VERSION ""

NS_ :

BS_:

BU_: Receiver ChassisBus VehicleBus PartyBus

BO_ 12 ID00CUI_status: 8 VehicleBus
 SG_ UI_audioActive : 1|1@1+ (1,0) [0|1] ""  Receiver
 SG_ UI_autopilotTrial : 12|2@1+ (1,0) [0|3] ""  Receiver
 SG_ UI_bluetoothActive : 2|1@1+ (1,0) [0|1] ""  Receiver
 SG_ UI_cameraActive : 41|1@1+ (1,0) [0|1] ""  Receiver
 SG_ UI_cellActive : 3|1@1+ (1,0) [0|1] ""  Receiver
 SG_ UI_cellConnected : 10|1@1+ (1,0) [0|1] ""  Receiver
 SG_ UI_cellNetworkTechnology : 19|4@1+ (1,0) [0|15] ""  Receiver
 SG_ UI_cellReceiverPower : 24|8@1+ (1,-128) [-128|127] "dB"  Receiver
 SG_ UI_cellSignalBars : 42|3@1+ (1,0) [0|7] ""  Receiver
 SG_ UI_cpuTemperature : 56|8@1- (1,40) [-20|100] "C"  Receiver
 SG_ UI_developmentCar : 40|1@1+ (1,0) [0|1] ""  Receiver
 SG_ UI_displayOn : 5|1@1+ (1,0) [0|1] ""  Receiver
 SG_ UI_displayReady : 4|1@1+ (1,0) [0|1] ""  Receiver
 SG_ UI_factoryReset : 14|2@1+ (1,0) [0|3] ""  Receiver
 SG_ UI_falseTouchCounter : 32|8@1+ (1,0) [0|255] "1"  Receiver
 SG_ UI_gpsActive : 16|1@1+ (1,0) [0|1] ""  Receiver
 SG_ UI_pcbTemperature : 48|8@1- (1,40) [-20|100] "C"  Receiver
 SG_ UI_radioActive : 18|1@1+ (1,0) [0|1] ""  Receiver
 SG_ UI_readyForDrive : 9|1@1+ (1,0) [0|1] ""  Receiver
 SG_ UI_screenshotActive : 17|1@1+ (1,0) [0|1] ""  Receiver
 SG_ UI_systemActive : 8|1@1+ (1,0) [0|1] ""  Receiver
 SG_ UI_touchActive : 0|1@1+ (1,0) [0|1] ""  Receiver
 SG_ UI_vpnActive : 11|1@1+ (1,0) [0|1] ""  Receiver
 SG_ UI_wifiActive : 6|1@1+ (1,0) [0|1] ""  Receiver
 SG_ UI_wifiConnected : 7|1@1+ (1,0) [0|1] ""  Receiver

BO_ 851 ID353UI_status: 8 VehicleBus
 SG_ UI_audioActive : 1|1@1+ (1,0) [0|1] ""  Receiver
 SG_ UI_autopilotTrial : 12|2@1+ (1,0) [0|3] ""  Receiver
 SG_ UI_bluetoothActive : 2|1@1+ (1,0) [0|1] ""  Receiver
 SG_ UI_cameraActive : 41|1@1+ (1,0) [0|1] ""  Receiver
 SG_ UI_cellActive : 3|1@1+ (1,0) [0|1] ""  Receiver
 SG_ UI_cellConnected : 10|1@1+ (1,0) [0|1] ""  Receiver
 SG_ UI_cellNetworkTechnology : 19|4@1+ (1,0) [0|15] ""  Receiver
 SG_ UI_cellReceiverPower : 24|8@1+ (1,-128) [-128|127] "dB"  Receiver
 SG_ UI_cellSignalBars : 42|3@1+ (1,0) [0|7] ""  Receiver
 SG_ UI_cpuTemperature : 56|8@1- (1,40) [-20|100] "C"  Receiver
 SG_ UI_developmentCar : 40|1@1+ (1,0) [0|1] ""  Receiver
 SG_ UI_displayOn : 5|1@1+ (1,0) [0|1] ""  Receiver
 SG_ UI_displayReady : 4|1@1+ (1,0) [0|1] ""  Receiver
 SG_ UI_factoryReset : 14|2@1+ (1,0) [0|3] ""  Receiver
 SG_ UI_falseTouchCounter : 32|8@1+ (1,0) [0|255] "1"  Receiver
 SG_ UI_gpsActive : 16|1@1+ (1,0) [0|1] ""  Receiver
 SG_ UI_pcbTemperature : 48|8@1- (1,40) [-20|100] "C"  Receiver
 SG_ UI_radioActive : 18|1@1+ (1,0) [0|1] ""  Receiver
 SG_ UI_readyForDrive : 9|1@1+ (1,0) [0|1] ""  Receiver
 SG_ UI_screenshotActive : 17|1@1+ (1,0) [0|1] ""  Receiver
 SG_ UI_systemActive : 8|1@1+ (1,0) [0|1] ""  Receiver
 SG_ UI_touchActive : 0|1@1+ (1,0) [0|1] ""  Receiver
 SG_ UI_vpnActive : 11|1@1+ (1,0) [0|1] ""  Receiver
 SG_ UI_wifiActive : 6|1@1+ (1,0) [0|1] ""  Receiver
 SG_ UI_wifiConnected : 7|1@1+ (1,0) [0|1] ""  Receiver

BO_ 22 ID016DI_bmsRequest: 1 VehicleBus
 SG_ DI_bmsOpenContactorsRequest : 4|1@1+ (1,0) [0|1] ""  Receiver
 SG_ DI_bmsRequestInterfaceVersion : 0|4@1+ (1,0) [0|15] ""  Receiver

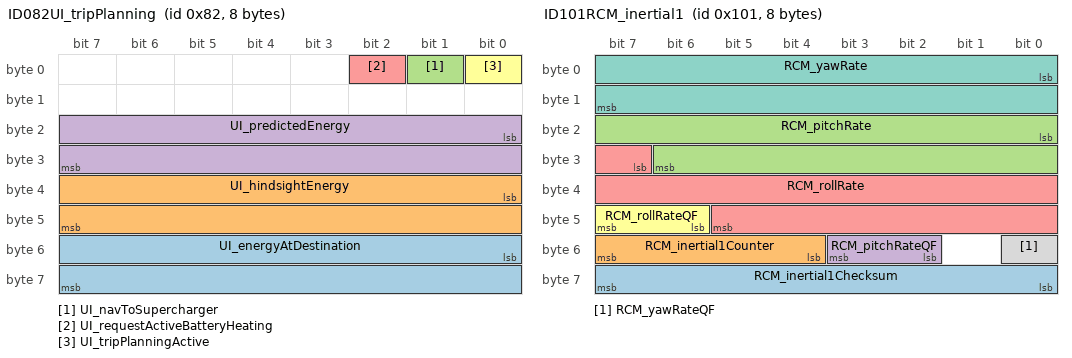
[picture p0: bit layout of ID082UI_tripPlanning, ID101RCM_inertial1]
BO_ 130 ID082UI_tripPlanning: 8 VehicleBus
 SG_ UI_energyAtDestination : 48|16@1- (0.01,0) [-327.67|327.67] "kWh"  Receiver
 SG_ UI_hindsightEnergy : 32|16@1- (0.01,0) [-327.67|327.67] "kWh"  Receiver
 SG_ UI_navToSupercharger : 1|1@1+ (1,0) [0|1] ""  Receiver
 SG_ UI_predictedEnergy : 16|16@1- (0.01,0) [-327.67|327.67] "kWh"  Receiver
 SG_ UI_requestActiveBatteryHeating : 2|1@1+ (1,0) [0|1] ""  Receiver
 SG_ UI_tripPlanningActive : 0|1@1+ (1,0) [0|1] ""  Receiver

BO_ 257 ID101RCM_inertial1: 8 ChassisBus
 SG_ RCM_inertial1Checksum : 56|8@1+ (1,0) [0|255] ""  Receiver
 SG_ RCM_inertial1Counter : 52|4@1+ (1,0) [0|15] ""  Receiver
 SG_ RCM_pitchRate : 16|15@1- (0.00025,0) [-4.096|4.09575] "rad/s"  Receiver
 SG_ RCM_pitchRateQF : 50|2@1+ (1,0) [0|3] ""  Receiver
 SG_ RCM_rollRate : 31|15@1- (0.00025,0) [-4.096|4.09575] "rad/s"  Receiver
 SG_ RCM_rollRateQF : 46|2@1+ (1,0) [0|3] ""  Receiver
 SG_ RCM_yawRate : 0|16@1- (0.0001,0) [-3.2766|3.2766] "rad/s"  Receiver
 SG_ RCM_yawRateQF : 48|1@1+ (1,0) [0|1] ""  Receiver

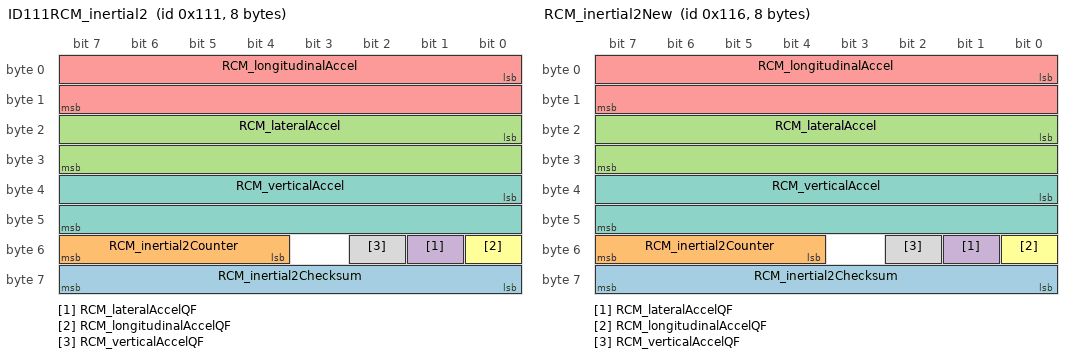
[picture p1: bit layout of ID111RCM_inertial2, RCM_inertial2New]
BO_ 273 ID111RCM_inertial2: 8 ChassisBus
 SG_ RCM_inertial2Checksum : 56|8@1+ (1,0) [0|255] ""  Receiver
 SG_ RCM_inertial2Counter : 52|4@1+ (1,0) [0|15] ""  Receiver
 SG_ RCM_lateralAccel : 16|16@1- (0.00125,0) [-40.9575|40.9575] "m/s^2"  Receiver
 SG_ RCM_lateralAccelQF : 49|1@1+ (1,0) [0|1] ""  Receiver
 SG_ RCM_longitudinalAccel : 0|16@1- (0.00125,0) [-40.9575|40.9575] "m/s^2"  Receiver
 SG_ RCM_longitudinalAccelQF : 48|1@1+ (1,0) [0|1] ""  Receiver
 SG_ RCM_verticalAccel : 32|16@1- (0.00125,0) [-40.9575|40.9575] "m/s^2"  Receiver
 SG_ RCM_verticalAccelQF : 50|1@1+ (1,0) [0|1] ""  Receiver

BO_ 278 RCM_inertial2New: 8 ChassisBus
 SG_ RCM_inertial2Checksum : 56|8@1+ (1,0) [0|255] ""  Receiver
 SG_ RCM_inertial2Counter : 52|4@1+ (1,0) [0|15] ""  Receiver
 SG_ RCM_lateralAccel : 16|16@1- (0.00125,0) [-40.9575|40.9575] "m/s^2"  Receiver
 SG_ RCM_lateralAccelQF : 49|1@1+ (1,0) [0|1] ""  Receiver
 SG_ RCM_longitudinalAccel : 0|16@1- (0.00125,0) [-40.9575|40.9575] "m/s^2"  Receiver
 SG_ RCM_longitudinalAccelQF : 48|1@1+ (1,0) [0|1] ""  Receiver
 SG_ RCM_verticalAccel : 32|16@1- (0.00125,0) [-40.9575|40.9575] "m/s^2"  Receiver
 SG_ RCM_verticalAccelQF : 50|1@1+ (1,0) [0|1] ""  Receiver

BO_ 258 ID102VCLEFT_doorStatus: 8 VehicleBus
 SG_ VCLEFT_frontHandlePWM : 16|7@1+ (1,0) [0|100] "%"  Receiver
 SG_ VCLEFT_frontHandlePulled : 10|1@1+ (1,0) [0|1] ""  Receiver
 SG_ VCLEFT_frontHandlePulledPersist : 62|1@1+ (1,0) [0|1] ""  Receiver
 SG_ VCLEFT_frontIntSwitchPressed : 31|1@1+ (1,0) [0|1] ""  Receiver
 SG_ VCLEFT_frontLatchStatus : 0|4@1+ (1,0) [0|8] ""  Receiver
 SG_ VCLEFT_frontLatchSwitch : 8|1@1+ (1,0) [0|1] ""  Receiver
 SG_ VCLEFT_frontRelActuatorSwitch : 12|1@1+ (1,0) [0|1] ""  Receiver
 SG_ VCLEFT_mirrorDipped : 61|1@1+ (1,0) [0|1] ""  Receiver
 SG_ VCLEFT_mirrorFoldState : 52|3@1+ (1,0) [0|4] ""  Receiver
 SG_ VCLEFT_mirrorHeatState : 58|3@1+ (1,0) [0|4] ""  Receiver
 SG_ VCLEFT_mirrorRecallState : 55|3@1+ (1,0) [0|5] ""  Receiver
 SG_ VCLEFT_mirrorState : 49|3@1+ (1,0) [0|4] ""  Receiver
 SG_ VCLEFT_mirrorTiltXPosition : 33|8@1+ (0.02,0) [0|5] "V"  Receiver
 SG_ VCLEFT_mirrorTiltYPosition : 41|8@1+ (0.02,0) [0|5] "V"  Receiver
 SG_ VCLEFT_rearHandlePWM : 24|7@1+ (1,0) [0|100] "%"  Receiver
 SG_ VCLEFT_rearHandlePulled : 11|1@1+ (1,0) [0|1] ""  Receiver
 SG_ VCLEFT_rearIntSwitchPressed : 32|1@1+ (1,0) [0|1] ""  Receiver
 SG_ VCLEFT_rearLatchStatus : 4|4@1+ (1,0) [0|8] ""  Receiver
 SG_ VCLEFT_rearLatchSwitch : 9|1@1+ (1,0) [0|1] ""  Receiver
 SG_ VCLEFT_rearRelActuatorSwitch : 13|1@1+ (1,0) [0|1] ""  Receiver

BO_ 259 ID103VCRIGHT_doorStatus: 8 VehicleBus
 SG_ VCRIGHT_frontHandlePWM : 14|7@1+ (1,0) [0|100] "%"  Receiver
 SG_ VCRIGHT_frontHandlePulled : 10|1@1+ (1,0) [0|1] ""  Receiver
 SG_ VCRIGHT_frontHandlePulledPersist : 30|1@1+ (1,0) [0|1] ""  Receiver
 SG_ VCRIGHT_frontIntSwitchPressed : 31|1@1+ (1,0) [0|1] ""  Receiver
 SG_ VCRIGHT_frontLatchStatus : 0|4@1+ (1,0) [0|8] ""  Receiver
 SG_ VCRIGHT_frontLatchSwitch : 8|1@1+ (1,0) [0|1] ""  Receiver
 SG_ VCRIGHT_frontRelActuatorSwitch : 12|1@1+ (1,0) [0|1] ""  Receiver
 SG_ VCRIGHT_mirrorDipped : 63|1@1+ (1,0) [0|1] ""  Receiver
 SG_ VCRIGHT_mirrorFoldState : 52|3@1+ (1,0) [0|4] ""  Receiver
 SG_ VCRIGHT_mirrorRecallState : 60|3@1+ (1,0) [0|5] ""  Receiver
 SG_ VCRIGHT_mirrorState : 49|3@1+ (1,0) [0|4] ""  Receiver
 SG_ VCRIGHT_mirrorTiltXPosition : 33|8@1+ (0.02,0) [0|5] "V"  Receiver
 SG_ VCRIGHT_mirrorTiltYPosition : 41|8@1+ (0.02,0) [0|5] "V"  Receiver
 SG_ VCRIGHT_rearHandlePWM : 21|7@1+ (1,0) [0|100] "%"  Receiver
 SG_ VCRIGHT_rearHandlePulled : 11|1@1+ (1,0) [0|1] ""  Receiver
 SG_ VCRIGHT_rearIntSwitchPressed : 32|1@1+ (1,0) [0|1] ""  Receiver
 SG_ VCRIGHT_rearLatchStatus : 4|4@1+ (1,0) [0|8] ""  Receiver
 SG_ VCRIGHT_rearLatchSwitch : 9|1@1+ (1,0) [0|1] ""  Receiver
 SG_ VCRIGHT_rearRelActuatorSwitch : 13|1@1+ (1,0) [0|1] ""  Receiver
 SG_ VCRIGHT_reservedForBackCompat : 28|2@1+ (1,0) [0|3] ""  Receiver
 SG_ VCRIGHT_trunkLatchStatus : 56|4@1+ (1,0) [0|8] ""  Receiver

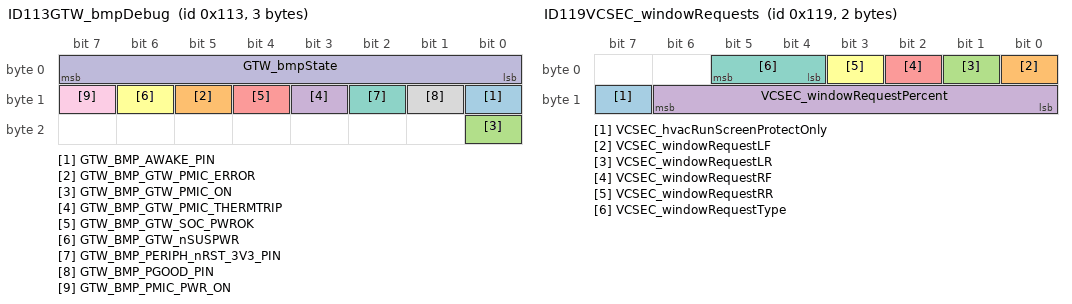
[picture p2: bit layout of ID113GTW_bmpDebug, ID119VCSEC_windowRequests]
BO_ 275 ID113GTW_bmpDebug: 3 VehicleBus
 SG_ GTW_BMP_AWAKE_PIN : 8|1@1+ (1,0) [0|1] ""  Receiver
 SG_ GTW_BMP_GTW_PMIC_ERROR : 13|1@1+ (1,0) [0|1] ""  Receiver
 SG_ GTW_BMP_GTW_PMIC_ON : 16|1@1+ (1,0) [0|1] ""  Receiver
 SG_ GTW_BMP_GTW_PMIC_THERMTRIP : 11|1@1+ (1,0) [0|1] ""  Receiver
 SG_ GTW_BMP_GTW_SOC_PWROK : 12|1@1+ (1,0) [0|1] ""  Receiver
 SG_ GTW_BMP_GTW_nSUSPWR : 14|1@1+ (1,0) [0|1] ""  Receiver
 SG_ GTW_BMP_PERIPH_nRST_3V3_PIN : 10|1@1+ (1,0) [0|1] ""  Receiver
 SG_ GTW_BMP_PGOOD_PIN : 9|1@1+ (1,0) [0|1] ""  Receiver
 SG_ GTW_BMP_PMIC_PWR_ON : 15|1@1+ (1,0) [0|1] ""  Receiver
 SG_ GTW_bmpState : 7|8@0+ (1,0) [0|255] ""  Receiver

BO_ 281 ID119VCSEC_windowRequests: 2 VehicleBus
 SG_ VCSEC_hvacRunScreenProtectOnly : 15|1@1+ (1,0) [0|1] ""  Receiver
 SG_ VCSEC_windowRequestLF : 0|1@1+ (1,0) [0|1] ""  Receiver
 SG_ VCSEC_windowRequestLR : 1|1@1+ (1,0) [0|1] ""  Receiver
 SG_ VCSEC_windowRequestPercent : 8|7@1+ (1,0) [0|127] ""  Receiver
 SG_ VCSEC_windowRequestRF : 2|1@1+ (1,0) [0|1] ""  Receiver
 SG_ VCSEC_windowRequestRR : 3|1@1+ (1,0) [0|1] ""  Receiver
 SG_ VCSEC_windowRequestType : 4|2@1+ (1,0) [0|3] ""  Receiver

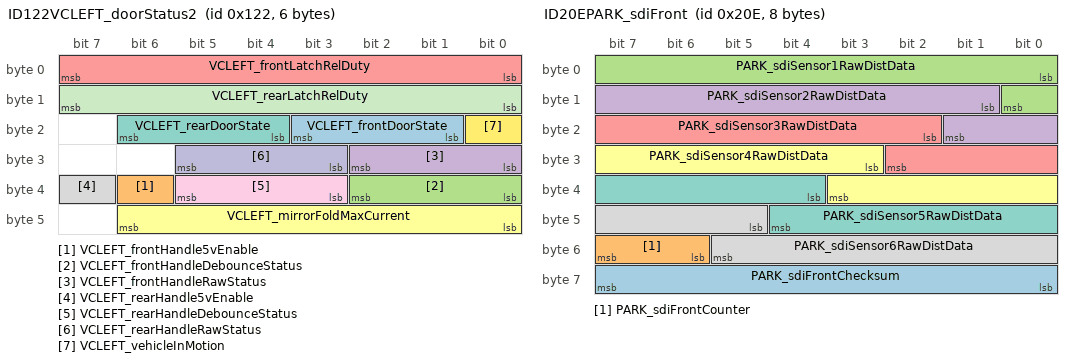
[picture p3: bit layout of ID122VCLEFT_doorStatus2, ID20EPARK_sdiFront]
BO_ 290 ID122VCLEFT_doorStatus2: 6 VehicleBus
 SG_ VCLEFT_frontDoorState : 17|3@1+ (1,0) [0|4] ""  Receiver
 SG_ VCLEFT_frontHandle5vEnable : 38|1@1+ (1,0) [0|1] ""  Receiver
 SG_ VCLEFT_frontHandleDebounceStatus : 32|3@1+ (1,0) [0|5] ""  Receiver
 SG_ VCLEFT_frontHandleRawStatus : 24|3@1+ (1,0) [0|5] ""  Receiver
 SG_ VCLEFT_frontLatchRelDuty : 0|8@1+ (1,0) [0|255] "%"  Receiver
 SG_ VCLEFT_mirrorFoldMaxCurrent : 40|7@1- (0.046,0) [-2.944|2.898] "A"  Receiver
 SG_ VCLEFT_rearDoorState : 20|3@1+ (1,0) [0|4] ""  Receiver
 SG_ VCLEFT_rearHandle5vEnable : 39|1@1+ (1,0) [0|1] ""  Receiver
 SG_ VCLEFT_rearHandleDebounceStatus : 35|3@1+ (1,0) [0|5] ""  Receiver
 SG_ VCLEFT_rearHandleRawStatus : 27|3@1+ (1,0) [0|5] ""  Receiver
 SG_ VCLEFT_rearLatchRelDuty : 8|8@1+ (1,0) [0|255] "%"  Receiver
 SG_ VCLEFT_vehicleInMotion : 16|1@1+ (1,0) [0|1] ""  Receiver

BO_ 291 ID123UI_alertMatrix1: 8 VehicleBus
 SG_ UI_a001_DriverDoorOpen : 0|1@1+ (1,0) [0|1] ""  Receiver
 SG_ UI_a002_DoorOpen : 1|1@1+ (1,0) [0|1] ""  Receiver
 SG_ UI_a003_TrunkOpen : 2|1@1+ (1,0) [0|1] ""  Receiver
 SG_ UI_a004_FrunkOpen : 3|1@1+ (1,0) [0|1] ""  Receiver
 SG_ UI_a005_HeadlightsOnDoorOpen : 4|1@1+ (1,0) [0|1] ""  Receiver
 SG_ UI_a006_RemoteServiceAlert : 5|1@1+ (1,0) [0|1] ""  Receiver
 SG_ UI_a007_SoftPackConfigMismatch : 6|1@1+ (1,0) [0|1] ""  Receiver
 SG_ UI_a008_TouchScreenError : 7|1@1+ (1,0) [0|1] ""  Receiver
 SG_ UI_a009_SquashfsError : 8|1@1+ (1,0) [0|1] ""  Receiver
 SG_ UI_a010_MapsMissing : 9|1@1+ (1,0) [0|1] ""  Receiver
 SG_ UI_a011_IncorrectMap : 10|1@1+ (1,0) [0|1] ""  Receiver
 SG_ UI_a012_NotOnPrivateProperty : 11|1@1+ (1,0) [0|1] ""  Receiver
 SG_ UI_a013_TPMSHardWarning : 12|1@1+ (1,0) [0|1] ""  Receiver
 SG_ UI_a014_TPMSSoftWarning : 13|1@1+ (1,0) [0|1] ""  Receiver
 SG_ UI_a015_TPMSOverPressureWarning : 14|1@1+ (1,0) [0|1] ""  Receiver
 SG_ UI_a016_TPMSTemperatureWarning : 15|1@1+ (1,0) [0|1] ""  Receiver
 SG_ UI_a017_TPMSSystemFault : 16|1@1+ (1,0) [0|1] ""  Receiver
 SG_ UI_a018_SlipStartOn : 17|1@1+ (1,0) [0|1] ""  Receiver
 SG_ UI_a019_ParkBrakeFault : 18|1@1+ (1,0) [0|1] ""  Receiver
 SG_ UI_a020_SteeringReduced : 19|1@1+ (1,0) [0|1] ""  Receiver
 SG_ UI_a021_RearSeatbeltUnbuckled : 20|1@1+ (1,0) [0|1] ""  Receiver
 SG_ UI_a022_ApeFusesEtc : 21|1@1+ (1,0) [0|1] ""  Receiver
 SG_ UI_a023_CellInternetCheckFailed : 22|1@1+ (1,0) [0|1] ""  Receiver
 SG_ UI_a024_WifiInternetCheckFailed : 23|1@1+ (1,0) [0|1] ""  Receiver
 SG_ UI_a025_WifiOnlineCheckFailed : 24|1@1+ (1,0) [0|1] ""  Receiver
 SG_ UI_a026_ModemResetLoopDetected : 25|1@1+ (1,0) [0|1] ""  Receiver
 SG_ UI_a027_AutoSteerMIA : 26|1@1+ (1,0) [0|1] ""  Receiver
 SG_ UI_a028_FrontTrunkPopupClosed : 27|1@1+ (1,0) [0|1] ""  Receiver
 SG_ UI_a029_ModemMIA : 28|1@1+ (1,0) [0|1] ""  Receiver
 SG_ UI_a030_ModemVMCrash : 29|1@1+ (1,0) [0|1] ""  Receiver
 SG_ UI_a031_BrakeFluidLow : 30|1@1+ (1,0) [0|1] ""  Receiver
 SG_ UI_a032_CellModemRecoveryResets : 31|1@1+ (1,0) [0|1] ""  Receiver
 SG_ UI_a033_ApTrialExpired : 32|1@1+ (1,0) [0|1] ""  Receiver
 SG_ UI_a034_WakeupProblem : 33|1@1+ (1,0) [0|1] ""  Receiver
 SG_ UI_a035_AudioWatchdogKernelError : 34|1@1+ (1,0) [0|1] ""  Receiver
 SG_ UI_a036_AudioWatchdogHfpError : 35|1@1+ (1,0) [0|1] ""  Receiver
 SG_ UI_a037_AudioWatchdogXrunStormEr : 36|1@1+ (1,0) [0|1] ""  Receiver
 SG_ UI_a038_AudioWatchdogA2bI2cLocku : 37|1@1+ (1,0) [0|1] ""  Receiver
 SG_ UI_a039_AudioA2bNeedRediscovery : 38|1@1+ (1,0) [0|1] ""  Receiver
 SG_ UI_a040_HomelinkTransmit : 39|1@1+ (1,0) [0|1] ""  Receiver
 SG_ UI_a041_AudioDmesgXrun : 40|1@1+ (1,0) [0|1] ""  Receiver
 SG_ UI_a042_AudioDmesgRtThrottling : 41|1@1+ (1,0) [0|1] ""  Receiver
 SG_ UI_a043_InvalidMapDataOverride : 42|1@1+ (1,0) [0|1] ""  Receiver
 SG_ UI_a044_AudioDmesgDspException : 43|1@1+ (1,0) [0|1] ""  Receiver
 SG_ UI_a045_ECallNeedsService : 44|1@1+ (1,0) [0|1] ""  Receiver
 SG_ UI_a046_BackupCameraStreamError : 45|1@1+ (1,0) [0|1] ""  Receiver
 SG_ UI_a047_CellRoamingDisallowed : 46|1@1+ (1,0) [0|1] ""  Receiver
 SG_ UI_a048_AudioPremiumAmpCheckFail : 47|1@1+ (1,0) [0|1] ""  Receiver
 SG_ UI_a049_BrakeShiftRequired : 48|1@1+ (1,0) [0|1] ""  Receiver
 SG_ UI_a050_BackupCameraIPUTimeout : 49|1@1+ (1,0) [0|1] ""  Receiver
 SG_ UI_a051_BackupCameraFrameTimeout : 50|1@1+ (1,0) [0|1] ""  Receiver
 SG_ UI_a052_KernelPanicReported : 51|1@1+ (1,0) [0|1] ""  Receiver
 SG_ UI_a053_QtCarExitError : 52|1@1+ (1,0) [0|1] ""  Receiver
 SG_ UI_a054_AudioBoostPowerBad : 53|1@1+ (1,0) [0|1] ""  Receiver
 SG_ UI_a055_ManualECallDisabled : 54|1@1+ (1,0) [0|1] ""  Receiver
 SG_ UI_a056_ManualECallButtonDisconn : 55|1@1+ (1,0) [0|1] ""  Receiver
 SG_ UI_a057_CellAntennaDisconnected : 56|1@1+ (1,0) [0|1] ""  Receiver
 SG_ UI_a058_GPSAntennaDisconnected : 57|1@1+ (1,0) [0|1] ""  Receiver
 SG_ UI_a059_ECallSpeakerDisconnected : 58|1@1+ (1,0) [0|1] ""  Receiver
 SG_ UI_a060_ECallMicDisconnected : 59|1@1+ (1,0) [0|1] ""  Receiver
 SG_ UI_a061_SIMTestFailed : 60|1@1+ (1,0) [0|1] ""  Receiver
 SG_ UI_a062_ENSTestFailed : 61|1@1+ (1,0) [0|1] ""  Receiver
 SG_ UI_a063_CellularTestFailed : 62|1@1+ (1,0) [0|1] ""  Receiver
 SG_ UI_a064_ModemFirmwareTestFailed : 63|1@1+ (1,0) [0|1] ""  Receiver

BO_ 322 ID142VCLEFT_liftgateStatus: 8 VehicleBus
 SG_ VCLEFT_liftgateStatusIndex M : 0|2@1+ (1,0) [0|2] ""  Receiver
 SG_ VCLEFT_liftgateLatchRequest m0 : 61|3@1+ (1,0) [0|4] ""  Receiver
 SG_ VCLEFT_liftgateMvmntNotAllowedCo m0 : 14|3@1+ (1,0) [0|5] ""  Receiver
 SG_ VCLEFT_liftgatePhysicalChimeRequ m0 : 21|3@1+ (1,0) [0|4] ""  Receiver
 SG_ VCLEFT_liftgatePosition m1 : 21|7@1- (1,46) [-5|95] "deg"  Receiver
 SG_ VCLEFT_liftgatePositionCalibrate m0 : 17|1@1+ (1,0) [0|1] ""  Receiver
 SG_ VCLEFT_liftgateRequestSource m0 : 7|3@1+ (1,0) [0|7] ""  Receiver
 SG_ VCLEFT_liftgateSpeed m1 : 28|10@1- (0.1,0) [-30|30] "deg/s"  Receiver
 SG_ VCLEFT_liftgateState m0 : 3|4@1+ (1,0) [0|12] ""  Receiver
 SG_ VCLEFT_liftgateStoppingCondition m0 : 10|4@1+ (1,0) [0|11] ""  Receiver
 SG_ VCLEFT_liftgateStrutCurrent m1 : 11|10@1- (0.1,0) [-30|30] "A"  Receiver
 SG_ VCLEFT_liftgateStrutDutyCycle m1 : 3|8@1- (1,0) [-100|100] "%"  Receiver
 SG_ VCLEFT_liftgateUIChimeRequest m0 : 18|3@1+ (1,0) [0|4] ""  Receiver

BO_ 325 ID145ESP_status: 8 ChassisBus
 SG_ ESP_absBrakeEvent2 : 22|2@1+ (1,0) [0|3] ""  Receiver
 SG_ ESP_absFaultLamp : 17|1@1+ (1,0) [0|1] ""  Receiver
 SG_ ESP_brakeApply : 31|1@1+ (1,0) [0|1] ""  Receiver
 SG_ ESP_brakeDiscWipingActive : 28|1@1+ (1,0) [0|1] ""  Receiver
 SG_ ESP_brakeLamp : 21|1@1+ (1,0) [0|1] ""  Receiver
 SG_ ESP_brakeTorqueTarget : 51|13@1+ (2,0) [0|16382] "Nm"  Receiver
 SG_ ESP_btcTargetState : 38|2@1+ (1,0) [0|3] ""  Receiver
 SG_ ESP_cdpStatus : 34|2@1+ (1,0) [0|3] ""  Receiver
 SG_ ESP_driverBrakeApply : 29|2@1+ (1,0) [0|3] ""  Receiver
 SG_ ESP_ebdFaultLamp : 16|1@1+ (1,0) [0|1] ""  Receiver
 SG_ ESP_ebrStandstillSkid : 48|1@1+ (1,0) [0|1] ""  Receiver
 SG_ ESP_ebrStatus : 49|2@1+ (1,0) [0|3] ""  Receiver
 SG_ ESP_espFaultLamp : 18|1@1+ (1,0) [0|1] ""  Receiver
 SG_ ESP_espLampFlash : 20|1@1+ (1,0) [0|1] ""  Receiver
 SG_ ESP_espModeActive : 12|2@1+ (1,0) [0|3] ""  Receiver
 SG_ ESP_hydraulicBoostEnabled : 19|1@1+ (1,0) [0|1] ""  Receiver
 SG_ ESP_lateralAccelQF : 25|1@1+ (1,0) [0|1] ""  Receiver
 SG_ ESP_longitudinalAccelQF : 24|1@1+ (1,0) [0|1] ""  Receiver
 SG_ ESP_ptcTargetState : 36|2@1+ (1,0) [0|3] ""  Receiver
 SG_ ESP_stabilityControlSts2 : 14|2@1+ (1,0) [0|3] ""  Receiver
 SG_ ESP_statusChecksum : 0|8@1+ (1,0) [0|255] ""  Receiver
 SG_ ESP_statusCounter : 8|4@1+ (1,0) [0|15] ""  Receiver
 SG_ ESP_steeringAngleQF : 27|1@1+ (1,0) [0|1] ""  Receiver
 SG_ ESP_yawRateQF : 26|1@1+ (1,0) [0|1] ""  Receiver

BO_ 470 ID1D6DI_limits: 5 VehicleBus
 SG_ DI_limitBaseSpeed : 15|1@1+ (1,0) [0|1] ""  Receiver
 SG_ DI_limitClutch : 28|1@1+ (1,0) [0|1] ""  Receiver
 SG_ DI_limitDcCapTemp : 17|1@1+ (1,0) [0|1] ""  Receiver
 SG_ DI_limitDeltaFluidTemp : 5|1@1+ (1,0) [0|1] ""  Receiver
 SG_ DI_limitDiff : 22|1@1+ (1,0) [0|1] ""  Receiver
 SG_ DI_limitDischargePower : 6|1@1+ (1,0) [0|1] ""  Receiver
 SG_ DI_limitDriveTorque : 10|1@1+ (1,0) [0|1] ""  Receiver
 SG_ DI_limitGracefulPowerOff : 23|1@1+ (1,0) [0|1] ""  Receiver
 SG_ DI_limitIBat : 16|1@1+ (1,0) [0|1] ""  Receiver
 SG_ DI_limitIGBTJunctTemp : 24|1@1+ (1,0) [0|1] ""  Receiver
 SG_ DI_limitInverterTemp : 1|1@1+ (1,0) [0|1] ""  Receiver
 SG_ DI_limitLimpMode : 4|1@1+ (1,0) [0|1] ""  Receiver
 SG_ DI_limitMotorCurrent : 8|1@1+ (1,0) [0|1] ""  Receiver
 SG_ DI_limitMotorSpeed : 20|1@1+ (1,0) [0|1] ""  Receiver
 SG_ DI_limitMotorVoltage : 9|1@1+ (1,0) [0|1] ""  Receiver
 SG_ DI_limitObstacleDetection : 29|1@1+ (1,0) [0|1] ""  Receiver
 SG_ DI_limitOilPumpFluidTemp : 26|1@1+ (1,0) [0|1] ""  Receiver
 SG_ DI_limitPCBTemp : 0|1@1+ (1,0) [0|1] ""  Receiver
 SG_ DI_limitPoleTemp : 3|1@1+ (1,0) [0|1] ""  Receiver
 SG_ DI_limitRegenPower : 7|1@1+ (1,0) [0|1] ""  Receiver
 SG_ DI_limitRegenTorque : 11|1@1+ (1,0) [0|1] ""  Receiver
 SG_ DI_limitRotorTemp : 36|1@1+ (1,0) [0|1] ""  Receiver
 SG_ DI_limitShift : 14|1@1+ (1,0) [0|1] ""  Receiver
 SG_ DI_limitShockTorque : 25|1@1+ (1,0) [0|1] ""  Receiver
 SG_ DI_limitStatorFrequency : 27|1@1+ (1,0) [0|1] ""  Receiver
 SG_ DI_limitStatorTemp : 2|1@1+ (1,0) [0|1] ""  Receiver
 SG_ DI_limitTCDrive : 12|1@1+ (1,0) [0|1] ""  Receiver
 SG_ DI_limitTCRegen : 13|1@1+ (1,0) [0|1] ""  Receiver
 SG_ DI_limitVBatHigh : 19|1@1+ (1,0) [0|1] ""  Receiver
 SG_ DI_limitVBatLow : 18|1@1+ (1,0) [0|1] ""  Receiver
 SG_ DI_limitVehicleSpeed : 21|1@1+ (1,0) [0|1] ""  Receiver
 SG_ DI_limitdcLinkCapTemp : 33|1@1+ (1,0) [0|1] ""  Receiver
 SG_ DI_limithvDcCableTemp : 37|1@1+ (1,0) [0|1] ""  Receiver
 SG_ DI_limitnegDcBusbarTemp : 34|1@1+ (1,0) [0|1] ""  Receiver
 SG_ DI_limitphaseOutBusBarWeldTemp : 31|1@1+ (1,0) [0|1] ""  Receiver
 SG_ DI_limitphaseOutBusbarTemp : 30|1@1+ (1,0) [0|1] ""  Receiver
 SG_ DI_limitphaseOutLugTemp : 32|1@1+ (1,0) [0|1] ""  Receiver
 SG_ DI_limitposDcBusbarTemp : 35|1@1+ (1,0) [0|1] ""  Receiver

BO_ 522 ID20AHVP_contactorState: 6 VehicleBus
 SG_ HVP_dcLinkAllowedToEnergize : 36|1@1+ (1,0) [0|1] ""  Receiver
 SG_ HVP_fcContNegativeAuxOpen : 7|1@1+ (1,0) [0|1] ""  Receiver
 SG_ HVP_fcContNegativeState : 12|3@1+ (1,0) [0|7] ""  Receiver
 SG_ HVP_fcContPositiveAuxOpen : 6|1@1+ (1,0) [0|1] ""  Receiver
 SG_ HVP_fcContPositiveState : 16|3@1+ (1,0) [0|7] ""  Receiver
 SG_ HVP_fcContactorSetState : 19|4@1+ (1,0) [0|9] ""  Receiver
 SG_ HVP_fcCtrsClosingAllowed : 29|1@1+ (1,0) [0|1] ""  Receiver
 SG_ HVP_fcCtrsOpenNowRequested : 27|1@1+ (1,0) [0|1] ""  Receiver
 SG_ HVP_fcCtrsOpenRequested : 28|1@1+ (1,0) [0|1] ""  Receiver
 SG_ HVP_fcCtrsRequestStatus : 24|2@1+ (1,0) [0|2] ""  Receiver
 SG_ HVP_fcCtrsResetRequestRequired : 26|1@1+ (1,0) [0|1] ""  Receiver
 SG_ HVP_fcLinkAllowedToEnergize : 44|2@1+ (1,0) [0|2] ""  Receiver
 SG_ HVP_hvilStatus : 40|4@1+ (1,0) [0|9] ""  Receiver
 SG_ HVP_packContNegativeState : 0|3@1+ (1,0) [0|7] ""  Receiver
 SG_ HVP_packContPositiveState : 3|3@1+ (1,0) [0|7] ""  Receiver
 SG_ HVP_packContactorSetState : 8|4@1+ (1,0) [0|9] ""  Receiver
 SG_ HVP_packCtrsClosingAllowed : 35|1@1+ (1,0) [0|1] ""  Receiver
 SG_ HVP_packCtrsOpenNowRequested : 33|1@1+ (1,0) [0|1] ""  Receiver
 SG_ HVP_packCtrsOpenRequested : 34|1@1+ (1,0) [0|1] ""  Receiver
 SG_ HVP_packCtrsRequestStatus : 30|2@1+ (1,0) [0|2] ""  Receiver
 SG_ HVP_packCtrsResetRequestRequired : 32|1@1+ (1,0) [0|1] ""  Receiver
 SG_ HVP_pyroTestInProgress : 37|1@1+ (1,0) [0|1] ""  Receiver

BO_ 526 ID20EPARK_sdiFront: 8 ChassisBus
 SG_ PARK_sdiFrontChecksum : 56|8@1+ (1,0) [0|255] ""  Receiver
 SG_ PARK_sdiFrontCounter : 54|2@1+ (1,0) [0|3] ""  Receiver
 SG_ PARK_sdiSensor1RawDistData : 0|9@1+ (1,0) [0|511] "cm"  Receiver
 SG_ PARK_sdiSensor2RawDistData : 9|9@1+ (1,0) [0|511] "cm"  Receiver
 SG_ PARK_sdiSensor3RawDistData : 18|9@1+ (1,0) [0|511] "cm"  Receiver
 SG_ PARK_sdiSensor4RawDistData : 27|9@1+ (1,0) [0|511] "cm"  Receiver
 SG_ PARK_sdiSensor5RawDistData : 36|9@1+ (1,0) [0|511] "cm"  Receiver
 SG_ PARK_sdiSensor6RawDistData : 45|9@1+ (1,0) [0|511] "cm"  Receiver

BO_ 537 ID219VCSEC_TPMSData: 5 ChassisBus
 SG_ VCSEC_TPMSDataIndex M : 0|2@1+ (1,0) [0|3] ""  Receiver
 SG_ VCSEC_TPMSBatVoltage0 m0 : 24|8@1+ (0.01,1.5) [1.5|4.04] "V"  Receiver
 SG_ VCSEC_TPMSBatVoltage1 m1 : 24|8@1+ (0.01,1.5) [1.5|4.04] "V"  Receiver
 SG_ VCSEC_TPMSBatVoltage2 m2 : 24|8@1+ (0.01,1.5) [1.5|4.04] "V"  Receiver
 SG_ VCSEC_TPMSBatVoltage3 m3 : 24|8@1+ (0.01,1.5) [1.5|4.04] "V"  Receiver
 SG_ VCSEC_TPMSLocation0 m0 : 32|3@1+ (1,0) [0|4] ""  Receiver
 SG_ VCSEC_TPMSLocation1 m1 : 32|3@1+ (1,0) [0|4] ""  Receiver
 SG_ VCSEC_TPMSLocation2 m2 : 32|3@1+ (1,0) [0|4] ""  Receiver
 SG_ VCSEC_TPMSLocation3 m3 : 32|3@1+ (1,0) [0|4] ""  Receiver
 SG_ VCSEC_TPMSPressure0 m0 : 8|8@1+ (0.025,0) [0|6.35] "bar"  Receiver
 SG_ VCSEC_TPMSPressure1 m1 : 8|8@1+ (0.025,0) [0|6.35] "bar"  Receiver
 SG_ VCSEC_TPMSPressure2 m2 : 8|8@1+ (0.025,0) [0|6.35] "bar"  Receiver
 SG_ VCSEC_TPMSPressure3 m3 : 8|8@1+ (0.025,0) [0|6.35] "bar"  Receiver
 SG_ VCSEC_TPMSTemperature0 m0 : 16|8@1+ (1,-40) [-40|214] "C"  Receiver
 SG_ VCSEC_TPMSTemperature1 m1 : 16|8@1+ (1,-40) [-40|214] "C"  Receiver
 SG_ VCSEC_TPMSTemperature2 m2 : 16|8@1+ (1,-40) [-40|214] "C"  Receiver
 SG_ VCSEC_TPMSTemperature3 m3 : 16|8@1+ (1,-40) [-40|214] "C"  Receiver

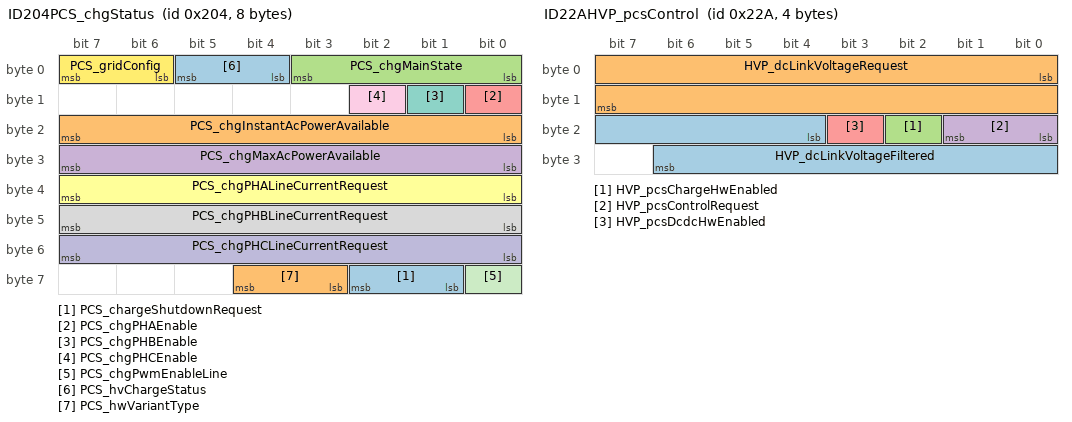
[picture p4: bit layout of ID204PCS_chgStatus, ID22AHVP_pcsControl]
BO_ 516 ID204PCS_chgStatus: 8 VehicleBus
 SG_ PCS_chargeShutdownRequest : 57|2@1+ (1,0) [0|2] ""  Receiver
 SG_ PCS_chgInstantAcPowerAvailable : 16|8@1+ (0.1,0) [0|20] "kW"  Receiver
 SG_ PCS_chgMainState : 0|4@1+ (1,0) [0|9] ""  Receiver
 SG_ PCS_chgMaxAcPowerAvailable : 24|8@1+ (0.1,0) [0|20] "kW"  Receiver
 SG_ PCS_chgPHAEnable : 8|1@1+ (1,0) [0|1] ""  Receiver
 SG_ PCS_chgPHALineCurrentRequest : 32|8@1+ (0.1,0) [0|20] "A"  Receiver
 SG_ PCS_chgPHBEnable : 9|1@1+ (1,0) [0|1] ""  Receiver
 SG_ PCS_chgPHBLineCurrentRequest : 40|8@1+ (0.1,0) [0|20] "A"  Receiver
 SG_ PCS_chgPHCEnable : 10|1@1+ (1,0) [0|1] ""  Receiver
 SG_ PCS_chgPHCLineCurrentRequest : 48|8@1+ (0.1,0) [0|20] "A"  Receiver
 SG_ PCS_chgPwmEnableLine : 56|1@1+ (1,0) [0|1] ""  Receiver
 SG_ PCS_gridConfig : 6|2@1+ (1,0) [0|3] ""  Receiver
 SG_ PCS_hvChargeStatus : 4|2@1+ (1,0) [0|3] ""  Receiver
 SG_ PCS_hwVariantType : 59|2@1+ (1,0) [0|3] ""  Receiver

BO_ 554 ID22AHVP_pcsControl: 4 VehicleBus
 SG_ HVP_dcLinkVoltageFiltered : 20|11@1- (1,0) [-550|550] "V"  Receiver
 SG_ HVP_dcLinkVoltageRequest : 0|16@1- (0.1,0) [-550|550] "V"  Receiver
 SG_ HVP_pcsChargeHwEnabled : 18|1@1+ (1,0) [0|1] ""  Receiver
 SG_ HVP_pcsControlRequest : 16|2@1+ (1,0) [0|3] ""  Receiver
 SG_ HVP_pcsDcdcHwEnabled : 19|1@1+ (1,0) [0|1] ""  Receiver

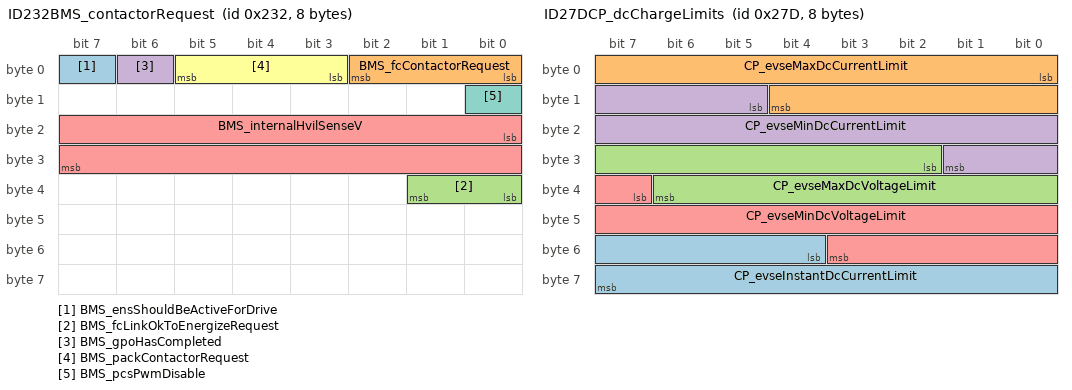
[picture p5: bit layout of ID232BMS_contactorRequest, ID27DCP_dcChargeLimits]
BO_ 562 ID232BMS_contactorRequest: 8 VehicleBus
 SG_ BMS_ensShouldBeActiveForDrive : 7|1@1+ (1,0) [0|1] ""  Receiver
 SG_ BMS_fcContactorRequest : 0|3@1+ (1,0) [0|5] ""  Receiver
 SG_ BMS_fcLinkOkToEnergizeRequest : 32|2@1+ (1,0) [0|2] ""  Receiver
 SG_ BMS_gpoHasCompleted : 6|1@1+ (1,0) [0|1] ""  Receiver
 SG_ BMS_internalHvilSenseV : 16|16@1+ (0.001,0) [0|65.534] "V"  Receiver
 SG_ BMS_packContactorRequest : 3|3@1+ (1,0) [0|5] ""  Receiver
 SG_ BMS_pcsPwmDisable : 8|1@1+ (1,0) [0|1] ""  Receiver

BO_ 627 ID273UI_vehicleControl: 8 VehicleBus
 SG_ UI_accessoryPowerRequest : 0|1@1+ (1,0) [0|1] ""  Receiver
 SG_ UI_alarmEnabled : 20|1@1+ (1,0) [0|1] ""  Receiver
 SG_ UI_ambientLightingEnabled : 40|1@1+ (1,0) [0|1] ""  Receiver
 SG_ UI_autoFoldMirrorsOn : 52|1@1+ (1,0) [0|1] ""  Receiver
 SG_ UI_autoHighBeamEnabled : 41|1@1+ (1,0) [0|1] ""  Receiver
 SG_ UI_childDoorLockOn : 16|1@1+ (1,0) [0|1] ""  Receiver
 SG_ UI_displayBrightnessLevel : 32|8@1+ (0.5,0) [0|127] "%"  Receiver
 SG_ UI_domeLightSwitch : 59|2@1+ (1,0) [0|2] ""  Receiver
 SG_ UI_driveStateRequest : 62|1@1+ (1,0) [0|1] ""  Receiver
 SG_ UI_frontFogSwitch : 3|1@1+ (1,0) [0|1] ""  Receiver
 SG_ UI_frontLeftSeatHeatReq : 42|2@1+ (1,0) [0|3] ""  Receiver
 SG_ UI_frontRightSeatHeatReq : 44|2@1+ (1,0) [0|3] ""  Receiver
 SG_ UI_frunkRequest : 5|1@1+ (1,0) [0|1] ""  Receiver
 SG_ UI_globalUnlockOn : 15|1@1+ (1,0) [0|1] ""  Receiver
 SG_ UI_honkHorn : 61|1@1+ (1,0) [0|1] ""  Receiver
 SG_ UI_intrusionSensorOn : 21|1@1+ (1,0) [0|1] ""  Receiver
 SG_ UI_lockRequest : 17|3@1+ (1,0) [0|7] ""  Receiver
 SG_ UI_mirrorDipOnReverse : 53|1@1+ (1,0) [0|1] ""  Receiver
 SG_ UI_mirrorFoldRequest : 24|2@1+ (1,0) [0|3] ""  Receiver
 SG_ UI_mirrorHeatRequest : 26|1@1+ (1,0) [0|1] ""  Receiver
 SG_ UI_powerOff : 31|1@1+ (1,0) [0|1] ""  Receiver
 SG_ UI_rearCenterSeatHeatReq : 48|2@1+ (1,0) [0|3] ""  Receiver
 SG_ UI_rearFogSwitch : 23|1@1+ (1,0) [0|1] ""  Receiver
 SG_ UI_rearLeftSeatHeatReq : 46|2@1+ (1,0) [0|3] ""  Receiver
 SG_ UI_rearRightSeatHeatReq : 50|2@1+ (1,0) [0|3] ""  Receiver
 SG_ UI_rearWindowLockout : 63|1@1+ (1,0) [0|1] ""  Receiver
 SG_ UI_remoteClosureRequest : 54|2@1+ (1,0) [0|3] ""  Receiver
 SG_ UI_remoteStartRequest : 27|3@1+ (1,0) [0|4] ""  Receiver
 SG_ UI_seeYouHomeLightingOn : 30|1@1+ (1,0) [0|1] ""  Receiver
 SG_ UI_steeringBacklightEnabled : 8|1@1+ (1,0) [0|1] ""  Receiver
 SG_ UI_steeringButtonMode : 9|3@1+ (1,0) [0|5] ""  Receiver
 SG_ UI_stop12vSupport : 22|1@1+ (1,0) [0|1] ""  Receiver
 SG_ UI_summonActive : 4|1@1+ (1,0) [0|1] ""  Receiver
 SG_ UI_unlockOnPark : 14|1@1+ (1,0) [0|1] ""  Receiver
 SG_ UI_walkAwayLock : 13|1@1+ (1,0) [0|1] ""  Receiver
 SG_ UI_walkUpUnlock : 12|1@1+ (1,0) [0|1] ""  Receiver
 SG_ UI_wiperMode : 6|2@1+ (1,0) [0|3] ""  Receiver
 SG_ UI_wiperRequest : 56|3@1+ (1,0) [0|6] ""  Receiver

BO_ 637 ID27DCP_dcChargeLimits: 8 VehicleBus
 SG_ CP_evseInstantDcCurrentLimit : 52|12@1+ (0.146484,0) [0|599.854] "A"  Receiver
 SG_ CP_evseMaxDcCurrentLimit : 0|13@1+ (0.0732422,0) [0|599.927] "A"  Receiver
 SG_ CP_evseMaxDcVoltageLimit : 26|13@1+ (0.0732422,0) [0|599.927] "V"  Receiver
 SG_ CP_evseMinDcCurrentLimit : 13|13@1+ (0.0732422,0) [0|599.927] "A"  Receiver
 SG_ CP_evseMinDcVoltageLimit : 39|13@1+ (0.0732422,0) [0|599.927] "V"  Receiver

BO_ 701 ID2BDCP_dcPowerLimits: 4 VehicleBus
 SG_ CP_evseInstantDcPowerLimit : 0|13@1+ (0.0622559,0) [0|509.938] "kW"  Receiver
 SG_ CP_evseMaxDcPowerLimit : 16|13@1+ (0.0622559,0) [0|509.938] "kW"  Receiver

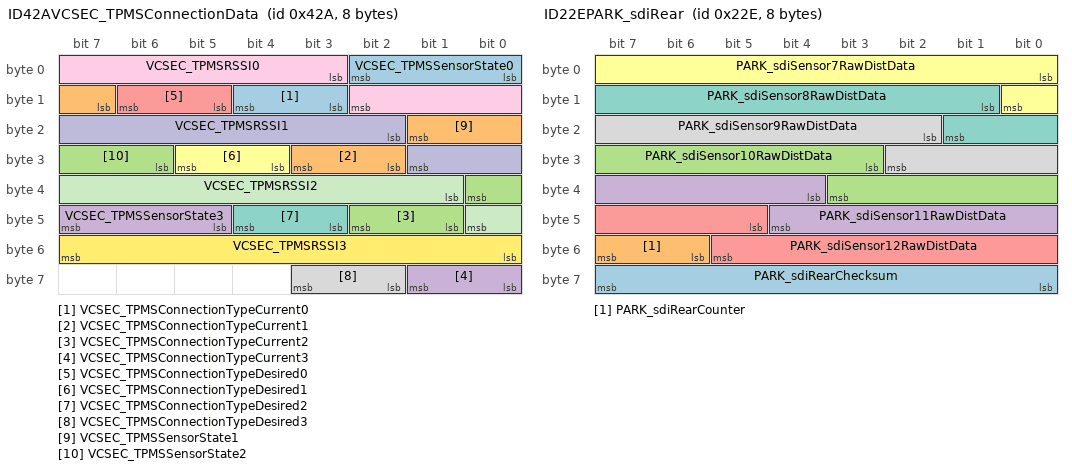
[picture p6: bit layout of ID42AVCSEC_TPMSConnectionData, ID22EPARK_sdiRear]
BO_ 1066 ID42AVCSEC_TPMSConnectionData: 8 VehicleBus
 SG_ VCSEC_TPMSConnectionTypeCurrent0 : 11|2@1+ (1,0) [0|2] ""  Receiver
 SG_ VCSEC_TPMSConnectionTypeCurrent1 : 26|2@1+ (1,0) [0|2] ""  Receiver
 SG_ VCSEC_TPMSConnectionTypeCurrent2 : 41|2@1+ (1,0) [0|2] ""  Receiver
 SG_ VCSEC_TPMSConnectionTypeCurrent3 : 56|2@1+ (1,0) [0|2] ""  Receiver
 SG_ VCSEC_TPMSConnectionTypeDesired0 : 13|2@1+ (1,0) [0|2] ""  Receiver
 SG_ VCSEC_TPMSConnectionTypeDesired1 : 28|2@1+ (1,0) [0|2] ""  Receiver
 SG_ VCSEC_TPMSConnectionTypeDesired2 : 43|2@1+ (1,0) [0|2] ""  Receiver
 SG_ VCSEC_TPMSConnectionTypeDesired3 : 58|2@1+ (1,0) [0|2] ""  Receiver
 SG_ VCSEC_TPMSRSSI0 : 3|8@1- (1,0) [-127|0] "dBm"  Receiver
 SG_ VCSEC_TPMSRSSI1 : 18|8@1- (1,0) [-127|0] "dBm"  Receiver
 SG_ VCSEC_TPMSRSSI2 : 33|8@1- (1,0) [-127|0] "dBm"  Receiver
 SG_ VCSEC_TPMSRSSI3 : 48|8@1- (1,0) [-127|0] "dBm"  Receiver
 SG_ VCSEC_TPMSSensorState0 : 0|3@1+ (1,0) [0|4] ""  Receiver
 SG_ VCSEC_TPMSSensorState1 : 15|3@1+ (1,0) [0|4] ""  Receiver
 SG_ VCSEC_TPMSSensorState2 : 30|3@1+ (1,0) [0|4] ""  Receiver
 SG_ VCSEC_TPMSSensorState3 : 45|3@1+ (1,0) [0|4] ""  Receiver

BO_ 558 ID22EPARK_sdiRear: 8 VehicleBus
 SG_ PARK_sdiRearChecksum : 56|8@1+ (1,0) [0|255] ""  Receiver
 SG_ PARK_sdiRearCounter : 54|2@1+ (1,0) [0|3] ""  Receiver
 SG_ PARK_sdiSensor10RawDistData : 27|9@1+ (1,0) [0|511] "cm"  Receiver
 SG_ PARK_sdiSensor11RawDistData : 36|9@1+ (1,0) [0|511] "cm"  Receiver
 SG_ PARK_sdiSensor12RawDistData : 45|9@1+ (1,0) [0|511] "cm"  Receiver
 SG_ PARK_sdiSensor7RawDistData : 0|9@1+ (1,0) [0|511] "cm"  Receiver
 SG_ PARK_sdiSensor8RawDistData : 9|9@1+ (1,0) [0|511] "cm"  Receiver
 SG_ PARK_sdiSensor9RawDistData : 18|9@1+ (1,0) [0|511] "cm"  Receiver

BO_ 568 ID238UI_driverAssistMapData: 8 ChassisBus
 SG_ UI_acceptBottsDots : 48|1@1+ (1,0) [0|1] ""  Receiver
 SG_ UI_autosteerRestricted : 49|1@1+ (1,0) [0|1] ""  Receiver
 SG_ UI_controlledAccess : 37|1@1+ (1,0) [0|1] ""  Receiver
 SG_ UI_countryCode : 16|10@1+ (1,0) [0|1023] ""  Receiver
 SG_ UI_gpsRoadMatch : 28|1@1+ (1,0) [0|1] ""  Receiver
 SG_ UI_inSuperchargerGeofence : 6|1@1+ (1,0) [0|1] ""  Receiver
 SG_ UI_mapDataChecksum : 56|8@1+ (1,0) [0|255] ""  Receiver
 SG_ UI_mapDataCounter : 52|4@1+ (1,0) [0|15] ""  Receiver
 SG_ UI_mapSpeedLimit : 8|5@1+ (1,0) [0|31] ""  Receiver
 SG_ UI_mapSpeedLimitDependency : 0|3@1+ (1,0) [0|7] ""  Receiver
 SG_ UI_mapSpeedLimitType : 13|3@1+ (1,0) [0|7] ""  Receiver
 SG_ UI_mapSpeedUnits : 7|1@1+ (1,0) [0|1] ""  Receiver
 SG_ UI_navRouteActive : 29|1@1+ (1,0) [0|1] ""  Receiver
 SG_ UI_nextBranchDist : 32|5@1+ (10,0) [0|300] "m"  Receiver
 SG_ UI_nextBranchLeftOffRamp : 38|1@1+ (1,0) [0|1] ""  Receiver
 SG_ UI_nextBranchRightOffRamp : 39|1@1+ (1,0) [0|1] ""  Receiver
 SG_ UI_parallelAutoparkEnabled : 30|1@1+ (1,0) [0|1] ""  Receiver
 SG_ UI_perpendicularAutoparkEnabled : 31|1@1+ (1,0) [0|1] ""  Receiver
 SG_ UI_pmmEnabled : 50|1@1+ (1,0) [0|1] ""  Receiver
 SG_ UI_rejectAutosteer : 46|1@1+ (1,0) [0|1] ""  Receiver
 SG_ UI_rejectHPP : 42|1@1+ (1,0) [0|1] ""  Receiver
 SG_ UI_rejectHandsOn : 47|1@1+ (1,0) [0|1] ""  Receiver
 SG_ UI_rejectLeftFreeSpace : 44|1@1+ (1,0) [0|1] ""  Receiver
 SG_ UI_rejectLeftLane : 40|1@1+ (1,0) [0|1] ""  Receiver
 SG_ UI_rejectNav : 43|1@1+ (1,0) [0|1] ""  Receiver
 SG_ UI_rejectRightFreeSpace : 45|1@1+ (1,0) [0|1] ""  Receiver
 SG_ UI_rejectRightLane : 41|1@1+ (1,0) [0|1] ""  Receiver
 SG_ UI_roadClass : 3|3@1+ (1,0) [0|6] ""  Receiver
 SG_ UI_scaEnabled : 51|1@1+ (1,0) [0|1] ""  Receiver
 SG_ UI_streetCount : 26|2@1+ (1,0) [0|3] ""  Receiver

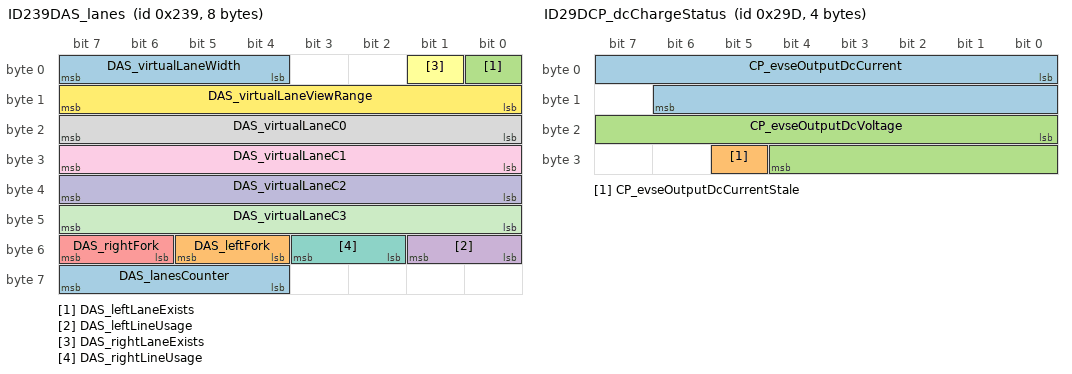
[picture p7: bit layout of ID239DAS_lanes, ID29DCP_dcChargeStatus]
BO_ 569 ID239DAS_lanes: 8 ChassisBus
 SG_ DAS_lanesCounter : 60|4@1+ (1,0) [0|15] ""  Receiver
 SG_ DAS_leftFork : 52|2@1+ (1,0) [0|3] ""  Receiver
 SG_ DAS_leftLaneExists : 0|1@1+ (1,0) [0|1] ""  Receiver
 SG_ DAS_leftLineUsage : 48|2@1+ (1,0) [0|3] ""  Receiver
 SG_ DAS_rightFork : 54|2@1+ (1,0) [0|3] ""  Receiver
 SG_ DAS_rightLaneExists : 1|1@1+ (1,0) [0|1] ""  Receiver
 SG_ DAS_rightLineUsage : 50|2@1+ (1,0) [0|3] ""  Receiver
 SG_ DAS_virtualLaneC0 : 16|8@1+ (0.035,-3.5) [-3.5|3.5] "m"  Receiver
 SG_ DAS_virtualLaneC1 : 24|8@1+ (0.0016,-0.2) [-0.2|0.2] "rad"  Receiver
 SG_ DAS_virtualLaneC2 : 32|8@1+ (2E-005,-0.0025) [-0.0025|0.0025] "m-1"  Receiver
 SG_ DAS_virtualLaneC3 : 40|8@1+ (2.4E-007,-3E-005) [-3E-005|3E-005] "m-2"  Receiver
 SG_ DAS_virtualLaneViewRange : 8|8@1+ (1,0) [0|160] "m"  Receiver
 SG_ DAS_virtualLaneWidth : 4|4@1+ (0.3125,2) [2|6.6875] "m"  Receiver

BO_ 586 ID24ADAS_visualDebug: 8 ChassisBus
 SG_ DAS_accSmartSpeedActive : 48|1@1+ (1,0) [0|1] ""  Receiver
 SG_ DAS_accSmartSpeedState : 49|3@1+ (1,0) [0|7] ""  Receiver
 SG_ DAS_autosteerBottsDotsUsage : 12|2@1+ (1,0) [0|3] ""  Receiver
 SG_ DAS_autosteerHPPUsage : 6|2@1+ (1,0) [0|3] ""  Receiver
 SG_ DAS_autosteerHealthAnomalyLevel : 18|3@1+ (1,0) [0|7] ""  Receiver
 SG_ DAS_autosteerHealthState : 21|3@1+ (1,0) [0|5] ""  Receiver
 SG_ DAS_autosteerModelUsage : 10|2@1+ (1,0) [0|3] ""  Receiver
 SG_ DAS_autosteerNavigationUsage : 8|2@1+ (1,0) [0|3] ""  Receiver
 SG_ DAS_autosteerVehiclesUsage : 4|2@1+ (1,0) [0|3] ""  Receiver
 SG_ DAS_behaviorType : 56|2@1+ (1,0) [0|3] ""  Receiver
 SG_ DAS_devAppInterfaceEnabled : 38|1@1+ (1,0) [0|1] ""  Receiver
 SG_ DAS_lastAutosteerAbortReason : 32|6@1+ (1,0) [0|34] ""  Receiver
 SG_ DAS_lastLinePreferenceReason : 24|4@1+ (1,0) [0|15] ""  Receiver
 SG_ DAS_navAvailable : 39|1@1+ (1,0) [0|1] ""  Receiver
 SG_ DAS_navDistance : 40|8@1+ (100,0) [0|25500] "km"  Receiver
 SG_ DAS_offsetSide : 14|2@1+ (1,0) [0|3] ""  Receiver
 SG_ DAS_plannerState : 28|4@1+ (1,0) [0|7] ""  Receiver
 SG_ DAS_rearLeftVehDetectedCurrent : 61|1@1+ (1,0) [0|1] ""  Receiver
 SG_ DAS_rearLeftVehDetectedTrip : 63|1@1+ (1,0) [0|1] ""  Receiver
 SG_ DAS_rearRightVehDetectedTrip : 62|1@1+ (1,0) [0|1] ""  Receiver
 SG_ DAS_rearVehDetectedThisCycle : 60|1@1+ (1,0) [0|1] ""  Receiver
 SG_ DAS_roadSurfaceType : 16|2@1+ (1,0) [0|2] ""  Receiver
 SG_ DAS_ulcInProgress : 52|1@1+ (1,0) [0|1] ""  Receiver
 SG_ DAS_ulcType : 58|2@1+ (1,0) [0|2] ""  Receiver

BO_ 603 ID25BAPP_environment: 1 ChassisBus
 SG_ APP_environmentRainy : 0|1@1+ (1,0) [0|1] ""  Receiver
 SG_ APP_environmentSnowy : 1|1@1+ (1,0) [0|1] ""  Receiver

BO_ 605 ID25DCP_status: 8 VehicleBus
 SG_ CP_UHF_controlState : 38|4@1+ (1,0) [0|10] ""  Receiver
 SG_ CP_UHF_handleFound : 42|1@1+ (1,0) [0|1] ""  Receiver
 SG_ CP_apsVoltage : 24|8@1+ (0.0715686,0) [0|18.249] "V"  Receiver
 SG_ CP_chargeCablePresent : 3|1@1+ (1,0) [0|1] ""  Receiver
 SG_ CP_chargeCableSecured : 4|1@1+ (1,0) [0|1] ""  Receiver
 SG_ CP_chargeCableState : 14|2@1+ (1,0) [0|2] ""  Receiver
 SG_ CP_chargeDoorOpen : 10|1@1+ (1,0) [0|1] ""  Receiver
 SG_ CP_chargeDoorOpenUI : 51|1@1+ (1,0) [0|1] ""  Receiver
 SG_ CP_coldWeatherMode : 60|1@1+ (1,0) [0|1] ""  Receiver
 SG_ CP_coverClosed : 63|1@1+ (1,0) [0|1] ""  Receiver
 SG_ CP_doorButtonPressed : 32|1@1+ (1,0) [0|1] ""  Receiver
 SG_ CP_doorControlState : 11|3@1+ (1,0) [0|6] ""  Receiver
 SG_ CP_doorOpenRequested : 43|1@1+ (1,0) [0|1] ""  Receiver
 SG_ CP_faultLineSensed : 44|1@1+ (1,0) [0|1] ""  Receiver
 SG_ CP_hvInletExposed : 61|1@1+ (1,0) [0|1] ""  Receiver
 SG_ CP_inductiveDoorState : 45|3@1+ (1,0) [0|7] ""  Receiver
 SG_ CP_inductiveSensorState : 48|3@1+ (1,0) [0|7] ""  Receiver
 SG_ CP_insertEnableLine : 2|1@1+ (1,0) [0|1] ""  Receiver
 SG_ CP_latch2ControlState : 19|3@1+ (1,0) [0|5] ""  Receiver
 SG_ CP_latch2State : 8|2@1+ (1,0) [0|3] ""  Receiver
 SG_ CP_latchControlState : 16|3@1+ (1,0) [0|5] ""  Receiver
 SG_ CP_latchEngaged : 62|1@1+ (1,0) [0|1] ""  Receiver
 SG_ CP_latchState : 5|2@1+ (1,0) [0|3] ""  Receiver
 SG_ CP_ledColor : 33|4@1+ (1,0) [0|10] ""  Receiver
 SG_ CP_numAlertsSet : 53|7@1+ (1,0) [0|127] ""  Receiver
 SG_ CP_permanentPowerRequest : 7|1@1+ (1,0) [0|1] ""  Receiver
 SG_ CP_swcanRelayClosed : 37|1@1+ (1,0) [0|1] ""  Receiver
 SG_ CP_type : 0|2@1+ (1,0) [0|3] ""  Receiver
 SG_ CP_vehicleUnlockRequest : 52|1@1+ (1,0) [0|1] ""  Receiver

BO_ 669 ID29DCP_dcChargeStatus: 4 VehicleBus
 SG_ CP_evseOutputDcCurrent : 0|15@1- (0.0732467,0) [-1200|1200] "A"  Receiver
 SG_ CP_evseOutputDcCurrentStale : 29|1@1+ (1,0) [0|1] ""  Receiver
 SG_ CP_evseOutputDcVoltage : 16|13@1+ (0.0732422,0) [0|599.927] "V"  Receiver

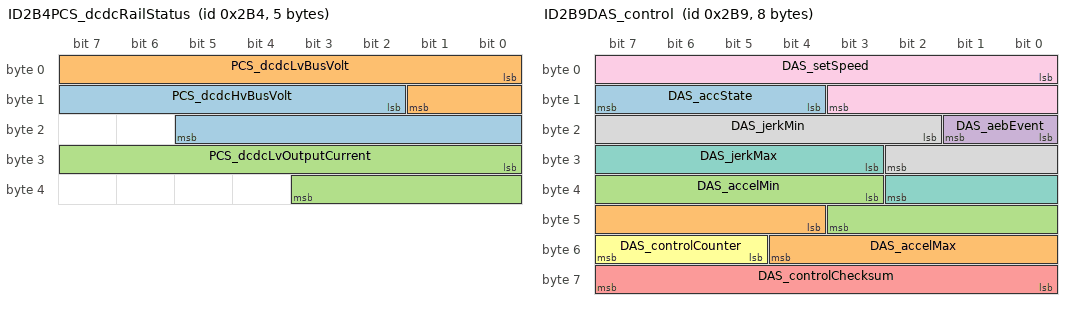
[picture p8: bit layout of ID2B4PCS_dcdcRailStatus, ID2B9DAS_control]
BO_ 692 ID2B4PCS_dcdcRailStatus: 5 VehicleBus
 SG_ PCS_dcdcHvBusVolt : 10|12@1+ (0.146484,0) [0|599.854] "V"  Receiver
 SG_ PCS_dcdcLvBusVolt : 0|10@1+ (0.0390625,0) [0|39.9609] "V"  Receiver
 SG_ PCS_dcdcLvOutputCurrent : 24|12@1+ (0.1,0) [0|400] "A"  Receiver

BO_ 697 ID2B9DAS_control: 8 ChassisBus
 SG_ DAS_accState : 12|4@1+ (1,0) [0|15] ""  Receiver
 SG_ DAS_accelMax : 44|9@1+ (0.04,-15) [-15|5.44] "m/s^2"  Receiver
 SG_ DAS_accelMin : 35|9@1+ (0.04,-15) [-15|5.44] "m/s^2"  Receiver
 SG_ DAS_aebEvent : 16|2@1+ (1,0) [0|3] ""  Receiver
 SG_ DAS_controlChecksum : 56|8@1+ (1,0) [0|255] ""  Receiver
 SG_ DAS_controlCounter : 53|3@1+ (1,0) [0|7] ""  Receiver
 SG_ DAS_jerkMax : 27|8@1+ (0.059,0) [0|15.045] "m/s^3"  Receiver
 SG_ DAS_jerkMin : 18|9@1+ (0.03,-15.232) [-15.232|0.098] "m/s^3"  Receiver
 SG_ DAS_setSpeed : 0|12@1+ (0.1,0) [0|409.4] "kph"  Receiver

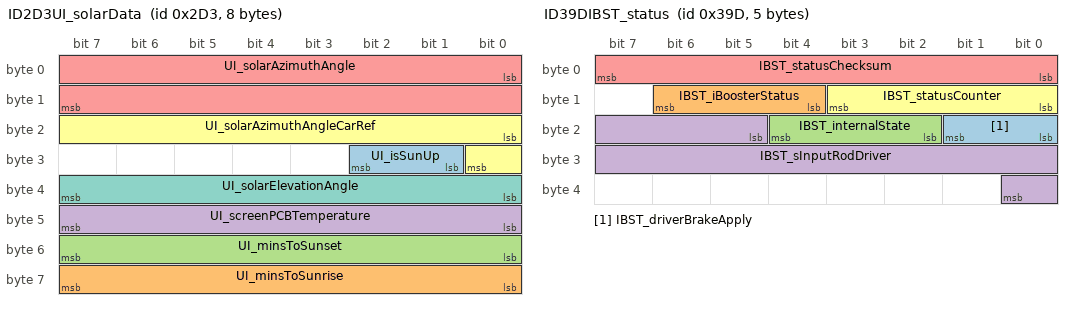
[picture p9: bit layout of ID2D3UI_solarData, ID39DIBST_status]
BO_ 723 ID2D3UI_solarData: 8 ChassisBus
 SG_ UI_isSunUp : 25|2@1+ (1,0) [0|3] ""  Receiver
 SG_ UI_minsToSunrise : 56|8@1+ (10,0) [0|2550] "min"  Receiver
 SG_ UI_minsToSunset : 48|8@1+ (10,0) [0|2550] "min"  Receiver
 SG_ UI_screenPCBTemperature : 40|8@1- (0.5,40) [-20|100] "C"  Receiver
 SG_ UI_solarAzimuthAngle : 0|16@1- (1,0) [-32767|32767] "deg"  Receiver
 SG_ UI_solarAzimuthAngleCarRef : 16|9@1- (1,0) [-256|254] "deg"  Receiver
 SG_ UI_solarElevationAngle : 32|8@1- (1,0) [-128|126] "deg"  Receiver

BO_ 777 ID309DAS_object: 8 VehicleBus
 SG_ DAS_objectId M : 0|3@1+ (1,0) [0|5] ""  Receiver
 SG_ DAS_cutinVehDx m3 : 8|8@1+ (0.5,0) [0|127] "m"  Receiver
 SG_ DAS_cutinVehDy m3 : 20|7@1+ (0.35,-22.05) [-22.05|22.4] "m"  Receiver
 SG_ DAS_cutinVehHeading m5 : 56|8@1+ (0.0245437,-3.14159) [-3.14159|3.09251] "rad"  Receiver
 SG_ DAS_cutinVehId m3 : 27|7@1+ (1,0) [0|127] ""  Receiver
 SG_ DAS_cutinVehRelevantForControl m3 : 7|1@1+ (1,0) [0|1] ""  Receiver
 SG_ DAS_cutinVehType m3 : 3|3@1+ (1,0) [0|5] ""  Receiver
 SG_ DAS_cutinVehVxRel m3 : 16|4@1+ (4,-30) [-30|26] "m/s"  Receiver
 SG_ DAS_leadVeh2Dx m0 : 39|8@1+ (0.5,0) [0|127] "m"  Receiver
 SG_ DAS_leadVeh2Dy m0 : 51|7@1+ (0.35,-22.05) [-22.05|22.4] "m"  Receiver
 SG_ DAS_leadVeh2Heading m5 : 16|8@1+ (0.0245437,-3.14159) [-3.14159|3.09251] "rad"  Receiver
 SG_ DAS_leadVeh2Id m0 : 58|6@1+ (1,0) [0|63] ""  Receiver
 SG_ DAS_leadVeh2RelevantForControl m0 : 38|1@1+ (1,0) [0|1] ""  Receiver
 SG_ DAS_leadVeh2Type m0 : 34|3@1+ (1,0) [0|5] ""  Receiver
 SG_ DAS_leadVeh2VxRel m0 : 47|4@1+ (4,-30) [-30|26] "m/s"  Receiver
 SG_ DAS_leadVehDx m0 : 8|8@1+ (0.5,0) [0|127] "m"  Receiver
 SG_ DAS_leadVehDy m0 : 20|7@1+ (0.35,-22.05) [-22.05|22.4] "m"  Receiver
 SG_ DAS_leadVehHeading m5 : 8|8@1+ (0.0245437,-3.14159) [-3.14159|3.09251] "rad"  Receiver
 SG_ DAS_leadVehId m0 : 27|7@1+ (1,0) [0|127] ""  Receiver
 SG_ DAS_leadVehRelevantForControl m0 : 7|1@1+ (1,0) [0|1] ""  Receiver
 SG_ DAS_leadVehType m0 : 3|3@1+ (1,0) [0|6] ""  Receiver
 SG_ DAS_leadVehVxRel m0 : 16|4@1+ (4,-30) [-30|26] "m/s"  Receiver
 SG_ DAS_leftVeh2Dx m1 : 39|8@1+ (0.5,0) [0|127] "m"  Receiver
 SG_ DAS_leftVeh2Dy m1 : 51|7@1+ (0.35,-22.05) [-22.05|22.4] "m"  Receiver
 SG_ DAS_leftVeh2Heading m5 : 32|8@1+ (0.0245437,-3.14159) [-3.14159|3.09251] "rad"  Receiver
 SG_ DAS_leftVeh2Id m1 : 58|6@1+ (1,0) [0|63] ""  Receiver
 SG_ DAS_leftVeh2RelevantForControl m1 : 38|1@1+ (1,0) [0|1] ""  Receiver
 SG_ DAS_leftVeh2Type m1 : 34|3@1+ (1,0) [0|5] ""  Receiver
 SG_ DAS_leftVeh2VxRel m1 : 47|4@1+ (4,-30) [-30|26] "m/s"  Receiver
 SG_ DAS_leftVehDx m1 : 8|8@1+ (0.5,0) [0|127] "m"  Receiver
 SG_ DAS_leftVehDy m1 : 20|7@1+ (0.35,-22.05) [-22.05|22.4] "m"  Receiver
 SG_ DAS_leftVehHeading m5 : 24|8@1+ (0.0245437,-3.14159) [-3.14159|3.09251] "rad"  Receiver
 SG_ DAS_leftVehId m1 : 27|7@1+ (1,0) [0|127] ""  Receiver
 SG_ DAS_leftVehRelevantForControl m1 : 7|1@1+ (1,0) [0|1] ""  Receiver
 SG_ DAS_leftVehType m1 : 3|3@1+ (1,0) [0|5] ""  Receiver
 SG_ DAS_leftVehVxRel m1 : 16|4@1+ (4,-30) [-30|26] "m/s"  Receiver
 SG_ DAS_rightVeh2Dx m2 : 39|8@1+ (0.5,0) [0|127] "m"  Receiver
 SG_ DAS_rightVeh2Dy m2 : 51|7@1+ (0.35,-22.05) [-22.05|22.4] "m"  Receiver
 SG_ DAS_rightVeh2Heading m5 : 48|8@1+ (0.0245437,-3.14159) [-3.14159|3.09251] "rad"  Receiver
 SG_ DAS_rightVeh2Id m2 : 58|6@1+ (1,0) [0|63] ""  Receiver
 SG_ DAS_rightVeh2RelevantForControl m2 : 38|1@1+ (1,0) [0|1] ""  Receiver
 SG_ DAS_rightVeh2Type m2 : 34|3@1+ (1,0) [0|5] ""  Receiver
 SG_ DAS_rightVeh2VxRel m2 : 47|4@1+ (4,-30) [-30|26] "m/s"  Receiver
 SG_ DAS_rightVehDx m2 : 8|8@1+ (0.5,0) [0|127] "m"  Receiver
 SG_ DAS_rightVehDy m2 : 20|7@1+ (0.35,-22.05) [-22.05|22.4] "m"  Receiver
 SG_ DAS_rightVehHeading m5 : 40|8@1+ (0.0245437,-3.14159) [-3.14159|3.09251] "rad"  Receiver
 SG_ DAS_rightVehId m2 : 27|7@1+ (1,0) [0|127] ""  Receiver
 SG_ DAS_rightVehRelevantForControl m2 : 7|1@1+ (1,0) [0|1] ""  Receiver
 SG_ DAS_rightVehType m2 : 3|3@1+ (1,0) [0|5] ""  Receiver
 SG_ DAS_rightVehVxRel m2 : 16|4@1+ (4,-30) [-30|26] "m/s"  Receiver
 SG_ DAS_roadSignArrow m4 : 27|3@1+ (1,0) [0|4] ""  Receiver
 SG_ DAS_roadSignColor m4 : 3|3@1+ (1,0) [0|4] ""  Receiver
 SG_ DAS_roadSignControlActive m4 : 24|1@1+ (1,0) [0|1] ""  Receiver
 SG_ DAS_roadSignId m4 : 6|8@1+ (1,0) [0|255] ""  Receiver
 SG_ DAS_roadSignOrientation m4 : 30|2@1+ (1,0) [0|2] ""  Receiver
 SG_ DAS_roadSignSource m4 : 25|2@1+ (1,0) [0|2] ""  Receiver
 SG_ DAS_roadSignStopLineDist m4 : 14|10@1+ (0.2,-20) [-20|184.4] "m"  Receiver

BO_ 905 ID389DAS_status2: 8 ChassisBus
 SG_ DAS_ACC_report : 26|5@1+ (1,0) [0|24] ""  Receiver
 SG_ DAS_accSpeedLimit : 0|10@1+ (0.2,0) [0|204.6] "mph"  Receiver
 SG_ DAS_activationFailureStatus : 14|2@1+ (1,0) [0|2] ""  Receiver
 SG_ DAS_csaState : 32|2@1+ (1,0) [0|3] ""  Receiver
 SG_ DAS_driverInteractionLevel : 38|2@1+ (1,0) [0|2] ""  Receiver
 SG_ DAS_longCollisionWarning : 48|4@1+ (1,0) [0|15] ""  Receiver
 SG_ DAS_pmmCameraFaultReason : 24|2@1+ (1,0) [0|2] ""  Receiver
 SG_ DAS_pmmLoggingRequest : 13|1@1+ (1,0) [0|1] ""  Receiver
 SG_ DAS_pmmObstacleSeverity : 10|3@1+ (1,0) [0|7] ""  Receiver
 SG_ DAS_pmmRadarFaultReason : 19|2@1+ (1,0) [0|2] ""  Receiver
 SG_ DAS_pmmSysFaultReason : 21|3@1+ (1,0) [0|7] ""  Receiver
 SG_ DAS_pmmUltrasonicsFaultReason : 16|3@1+ (1,0) [0|4] ""  Receiver
 SG_ DAS_ppOffsetDesiredRamp : 40|8@1+ (0.01,-1.28) [-1.28|1.27] "m"  Receiver
 SG_ DAS_radarTelemetry : 34|2@1+ (1,0) [0|2] ""  Receiver
 SG_ DAS_relaxCruiseLimits : 31|1@1+ (1,0) [0|1] ""  Receiver
 SG_ DAS_robState : 36|2@1+ (1,0) [0|3] ""  Receiver
 SG_ DAS_status2Checksum : 56|8@1+ (1,0) [0|255] ""  Receiver
 SG_ DAS_status2Counter : 52|4@1+ (1,0) [0|15] ""  Receiver

BO_ 921 ID399DAS_status: 8 ChassisBus
 SG_ DAS_autoLaneChangeState : 46|5@1+ (1,0) [0|31] ""  Receiver
 SG_ DAS_autoParked : 25|1@1+ (1,0) [0|1] ""  Receiver
 SG_ DAS_autoparkReady : 24|1@1+ (1,0) [0|1] ""  Receiver
 SG_ DAS_autoparkWaitingForBrake : 26|1@1+ (1,0) [0|1] ""  Receiver
 SG_ DAS_autopilotHandsOnState : 42|4@1+ (1,0) [0|15] ""  Receiver
 SG_ DAS_autopilotState : 0|4@1+ (1,0) [0|15] ""  Receiver
 SG_ DAS_blindSpotRearLeft : 4|2@1+ (1,0) [0|3] ""  Receiver
 SG_ DAS_blindSpotRearRight : 6|2@1+ (1,0) [0|3] ""  Receiver
 SG_ DAS_fleetSpeedState : 40|2@1+ (1,0) [0|3] ""  Receiver
 SG_ DAS_forwardCollisionWarning : 22|2@1+ (1,0) [0|3] ""  Receiver
 SG_ DAS_fusedSpeedLimit : 8|5@1+ (5,0) [0|150] "kph/mph"  Receiver
 SG_ DAS_heaterState : 21|1@1+ (1,0) [0|1] ""  Receiver
 SG_ DAS_laneDepartureWarning : 37|3@1+ (1,0) [0|5] ""  Receiver
 SG_ DAS_lssState : 29|3@1+ (1,0) [0|7] ""  Receiver
 SG_ DAS_sideCollisionAvoid : 32|2@1+ (1,0) [0|3] ""  Receiver
 SG_ DAS_sideCollisionInhibit : 36|1@1+ (1,0) [0|1] ""  Receiver
 SG_ DAS_sideCollisionWarning : 34|2@1+ (1,0) [0|3] ""  Receiver
 SG_ DAS_statusChecksum : 56|8@1+ (1,0) [0|255] ""  Receiver
 SG_ DAS_statusCounter : 52|4@1+ (1,0) [0|15] ""  Receiver
 SG_ DAS_summonAvailable : 51|1@1+ (1,0) [0|1] ""  Receiver
 SG_ DAS_summonClearedGate : 15|1@1+ (1,0) [0|1] ""  Receiver
 SG_ DAS_summonFwdLeashReached : 27|1@1+ (1,0) [0|1] ""  Receiver
 SG_ DAS_summonObstacle : 14|1@1+ (1,0) [0|1] ""  Receiver
 SG_ DAS_summonRvsLeashReached : 28|1@1+ (1,0) [0|1] ""  Receiver
 SG_ DAS_suppressSpeedWarning : 13|1@1+ (1,0) [0|1] ""  Receiver
 SG_ DAS_visionOnlySpeedLimit : 16|5@1+ (5,0) [0|150] "kph/mph"  Receiver

BO_ 925 ID39DIBST_status: 5 ChassisBus
 SG_ IBST_driverBrakeApply : 16|2@1+ (1,0) [0|3] ""  Receiver
 SG_ IBST_iBoosterStatus : 12|3@1+ (1,0) [0|6] ""  Receiver
 SG_ IBST_internalState : 18|3@1+ (1,0) [0|6] ""  Receiver
 SG_ IBST_sInputRodDriver : 21|12@1+ (0.015625,-5) [-5|47] "mm"  Receiver
 SG_ IBST_statusChecksum : 0|8@1+ (1,0) [0|255] ""  Receiver
 SG_ IBST_statusCounter : 8|4@1+ (1,0) [0|15] ""  Receiver

BO_ 929 ID3A1VCFRONT_vehicleStatus: 8 VehicleBus
 SG_ VCFRONT_12vStatusForDrive : 14|2@1+ (1,0) [0|2] ""  Receiver
 SG_ VCFRONT_2RowCenterUnbuckled : 38|2@1+ (1,0) [0|2] ""  Receiver
 SG_ VCFRONT_2RowLeftUnbuckled : 36|2@1+ (1,0) [0|2] ""  Receiver
 SG_ VCFRONT_2RowRightUnbuckled : 40|2@1+ (1,0) [0|2] ""  Receiver
 SG_ VCFRONT_APGlassHeaterState : 2|3@1+ (1,0) [0|4] ""  Receiver
 SG_ VCFRONT_accPlusAvailable : 9|1@1+ (1,0) [0|1] ""  Receiver
 SG_ VCFRONT_batterySupportRequest : 27|1@1+ (1,0) [0|1] ""  Receiver
 SG_ VCFRONT_bmsHvChargeEnable : 0|1@1+ (1,0) [0|1] ""  Receiver
 SG_ VCFRONT_diPowerOnState : 10|3@1+ (1,0) [0|4] ""  Receiver
 SG_ VCFRONT_driverBuckleStatus : 30|1@1+ (1,0) [0|1] ""  Receiver
 SG_ VCFRONT_driverDoorStatus : 31|1@1+ (1,0) [0|1] ""  Receiver
 SG_ VCFRONT_driverIsLeaving : 28|1@1+ (1,0) [0|1] ""  Receiver
 SG_ VCFRONT_driverIsLeavingAnySpeed : 13|1@1+ (1,0) [0|1] ""  Receiver
 SG_ VCFRONT_driverPresent : 7|1@1+ (1,0) [0|1] ""  Receiver
 SG_ VCFRONT_driverUnbuckled : 32|2@1+ (1,0) [0|2] ""  Receiver
 SG_ VCFRONT_ota12VSupportRequest : 29|1@1+ (1,0) [0|1] ""  Receiver
 SG_ VCFRONT_passengerPresent : 8|1@1+ (1,0) [0|1] ""  Receiver
 SG_ VCFRONT_passengerUnbuckled : 34|2@1+ (1,0) [0|2] ""  Receiver
 SG_ VCFRONT_pcs12vVoltageTarget : 16|11@1+ (0.01,0) [0|16] "V"  Receiver
 SG_ VCFRONT_pcsEFuseVoltage : 42|10@1+ (0.1,0) [0|102.2] "V"  Receiver
 SG_ VCFRONT_preconditionRequest : 1|1@1+ (1,0) [0|1] ""  Receiver
 SG_ VCFRONT_standbySupplySupported : 6|1@1+ (1,0) [0|1] ""  Receiver
 SG_ VCFRONT_thermalSystemType : 5|1@1+ (1,0) [0|1] ""  Receiver
 SG_ VCFRONT_vehicleStatusChecksum : 56|8@1+ (1,0) [0|255] ""  Receiver
 SG_ VCFRONT_vehicleStatusCounter : 52|4@1+ (1,0) [0|15] ""  Receiver

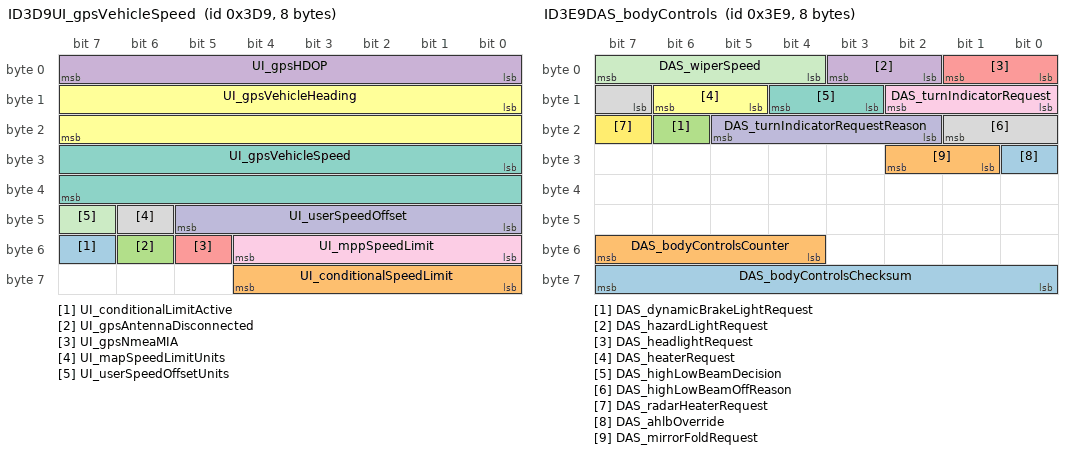
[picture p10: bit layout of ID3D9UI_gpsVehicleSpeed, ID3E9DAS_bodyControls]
BO_ 985 ID3D9UI_gpsVehicleSpeed: 8 ChassisBus
 SG_ UI_conditionalLimitActive : 55|1@1+ (1,0) [0|1] ""  Receiver
 SG_ UI_conditionalSpeedLimit : 56|5@1+ (5,0) [0|155] "kph/mph"  Receiver
 SG_ UI_gpsAntennaDisconnected : 54|1@1+ (1,0) [0|1] ""  Receiver
 SG_ UI_gpsHDOP : 0|8@1+ (0.1,0) [0|25.5] ""  Receiver
 SG_ UI_gpsNmeaMIA : 53|1@1+ (1,0) [0|1] ""  Receiver
 SG_ UI_gpsVehicleHeading : 8|16@1+ (0.0078125,0) [0|511.992] "deg"  Receiver
 SG_ UI_gpsVehicleSpeed : 24|16@1+ (0.00390625,0) [0|250.996] "kph"  Receiver
 SG_ UI_mapSpeedLimitUnits : 46|1@1+ (1,0) [0|1] ""  Receiver
 SG_ UI_mppSpeedLimit : 48|5@1+ (5,0) [0|155] "kph/mph"  Receiver
 SG_ UI_userSpeedOffset : 40|6@1+ (1,-30) [-30|33] "kph/mph"  Receiver
 SG_ UI_userSpeedOffsetUnits : 47|1@1+ (1,0) [0|1] ""  Receiver

BO_ 994 ID3E2VCLEFT_lightStatus: 7 VehicleBus
 SG_ VCLEFT_FLMapLightStatus : 6|2@1+ (1,0) [0|3] ""  Receiver
 SG_ VCLEFT_FLMapLightSwitchPressed : 14|1@1+ (1,0) [0|1] ""  Receiver
 SG_ VCLEFT_FRMapLightStatus : 8|2@1+ (1,0) [0|3] ""  Receiver
 SG_ VCLEFT_FRMapLightSwitchPressed : 15|1@1+ (1,0) [0|1] ""  Receiver
 SG_ VCLEFT_RLMapLightStatus : 10|2@1+ (1,0) [0|3] ""  Receiver
 SG_ VCLEFT_RLMapLightSwitchPressed : 16|1@1+ (1,0) [0|1] ""  Receiver
 SG_ VCLEFT_RRMapLightStatus : 12|2@1+ (1,0) [0|3] ""  Receiver
 SG_ VCLEFT_RRMapLightSwitchPressed : 17|1@1+ (1,0) [0|1] ""  Receiver
 SG_ VCLEFT_brakeLightStatus : 0|2@1+ (1,0) [0|3] ""  Receiver
 SG_ VCLEFT_brakeTrailerLightStatus : 22|2@1+ (1,0) [0|3] ""  Receiver
 SG_ VCLEFT_dynamicBrakeLightStatus : 44|2@1+ (1,0) [0|2] ""  Receiver
 SG_ VCLEFT_fogTrailerLightStatus : 26|2@1+ (1,0) [0|3] ""  Receiver
 SG_ VCLEFT_frontRideHeight : 28|8@1- (1,0) [-127|127] "mm"  Receiver
 SG_ VCLEFT_leftTurnTrailerLightStatu : 18|2@1+ (1,0) [0|3] ""  Receiver
 SG_ VCLEFT_rearRideHeight : 36|8@1- (1,0) [-127|127] "mm"  Receiver
 SG_ VCLEFT_reverseTrailerLightStatus : 49|2@1+ (1,0) [0|3] ""  Receiver
 SG_ VCLEFT_rideHeightSensorFault : 48|1@1+ (1,0) [0|1] ""  Receiver
 SG_ VCLEFT_rightTrnTrailerLightStatu : 20|2@1+ (1,0) [0|3] ""  Receiver
 SG_ VCLEFT_tailLightOutageStatus : 51|1@1+ (1,0) [0|1] ""  Receiver
 SG_ VCLEFT_tailLightStatus : 2|2@1+ (1,0) [0|3] ""  Receiver
 SG_ VCLEFT_tailTrailerLightStatus : 24|2@1+ (1,0) [0|3] ""  Receiver
 SG_ VCLEFT_trailerDetected : 46|2@1+ (1,0) [0|3] ""  Receiver
 SG_ VCLEFT_turnSignalStatus : 4|2@1+ (1,0) [0|3] ""  Receiver

BO_ 1001 ID3E9DAS_bodyControls: 8 VehicleBus
 SG_ DAS_bodyControlsChecksum : 56|8@1+ (1,0) [0|255] ""  Receiver
 SG_ DAS_bodyControlsCounter : 52|4@1+ (1,0) [0|15] ""  Receiver
 SG_ DAS_dynamicBrakeLightRequest : 22|1@1+ (1,0) [0|1] ""  Receiver
 SG_ DAS_hazardLightRequest : 2|2@1+ (1,0) [0|3] ""  Receiver
 SG_ DAS_headlightRequest : 0|2@1+ (1,0) [0|3] ""  Receiver
 SG_ DAS_heaterRequest : 13|2@1+ (1,0) [0|2] ""  Receiver
 SG_ DAS_highLowBeamDecision : 11|2@1+ (1,0) [0|3] ""  Receiver
 SG_ DAS_highLowBeamOffReason : 15|3@1+ (1,0) [0|5] ""  Receiver
 SG_ DAS_turnIndicatorRequest : 8|3@1+ (1,0) [0|4] ""  Receiver
 SG_ DAS_turnIndicatorRequestReason : 18|4@1+ (1,0) [0|12] ""  Receiver
 SG_ DAS_wiperSpeed : 4|4@1+ (1,0) [0|15] ""  Receiver
 SG_ DAS_radarHeaterRequest : 23|1@1+ (1,0) [0|1] ""  Receiver
 SG_ DAS_ahlbOverride : 24|1@1+ (1,0) [0|1] ""  Receiver
 SG_ DAS_mirrorFoldRequest : 25|2@1+ (1,0) [0|0] ""  Receiver

BO_ 1011 ID3F3UI_odo: 3 ChassisBus
 SG_ UI_odometer : 0|24@1+ (0.1,0) [0|1677720] "km"  Receiver

BO_ 1013 ID3F5VCFRONT_lighting: 8 VehicleBus
 SG_ VCFRONT_DRLLeftStatus : 36|2@1+ (1,0) [0|3] ""  Receiver
 SG_ VCFRONT_DRLRightStatus : 38|2@1+ (1,0) [0|3] ""  Receiver
 SG_ VCFRONT_ambientLightingBrightnes : 8|8@1+ (0.5,0) [0|127] "%"  Receiver
 SG_ VCFRONT_approachLightingRequest : 25|1@1+ (1,0) [0|1] ""  Receiver
 SG_ VCFRONT_courtesyLightingRequest : 24|1@1+ (1,0) [0|1] ""  Receiver
 SG_ VCFRONT_fogLeftStatus : 40|2@1+ (1,0) [0|3] ""  Receiver
 SG_ VCFRONT_fogRightStatus : 42|2@1+ (1,0) [0|3] ""  Receiver
 SG_ VCFRONT_hazardLightRequest : 4|4@1+ (1,0) [0|8] ""  Receiver
 SG_ VCFRONT_hazardSwitchBacklight : 27|1@1+ (1,0) [0|1] ""  Receiver
 SG_ VCFRONT_highBeamLeftStatus : 32|2@1+ (1,0) [0|3] ""  Receiver
 SG_ VCFRONT_highBeamRightStatus : 34|2@1+ (1,0) [0|3] ""  Receiver
 SG_ VCFRONT_highBeamSwitchActive : 58|1@1+ (1,0) [0|1] ""  Receiver
 SG_ VCFRONT_indicatorLeftRequest : 0|2@1+ (1,0) [0|2] ""  Receiver
 SG_ VCFRONT_indicatorRightRequest : 2|2@1+ (1,0) [0|2] ""  Receiver
 SG_ VCFRONT_lowBeamLeftStatus : 28|2@1+ (1,0) [0|3] ""  Receiver
 SG_ VCFRONT_lowBeamRightStatus : 30|2@1+ (1,0) [0|3] ""  Receiver
 SG_ VCFRONT_lowBeamsCalibrated : 62|1@1+ (1,0) [0|1] ""  Receiver
 SG_ VCFRONT_lowBeamsOnForDRL : 61|1@1+ (1,0) [0|1] ""  Receiver
 SG_ VCFRONT_parkLeftStatus : 54|2@1+ (1,0) [0|3] ""  Receiver
 SG_ VCFRONT_parkRightStatus : 56|2@1+ (1,0) [0|3] ""  Receiver
 SG_ VCFRONT_seeYouHomeLightingReq : 26|1@1+ (1,0) [0|1] ""  Receiver
 SG_ VCFRONT_sideMarkersStatus : 44|2@1+ (1,0) [0|3] ""  Receiver
 SG_ VCFRONT_sideRepeaterLeftStatus : 46|2@1+ (1,0) [0|3] ""  Receiver
 SG_ VCFRONT_sideRepeaterRightStatus : 48|2@1+ (1,0) [0|3] ""  Receiver
 SG_ VCFRONT_simLatchingStalk : 59|2@1+ (1,0) [0|3] ""  Receiver
 SG_ VCFRONT_switchLightingBrightness : 16|8@1+ (0.5,0) [0|127] "%"  Receiver
 SG_ VCFRONT_turnSignalLeftStatus : 50|2@1+ (1,0) [0|3] ""  Receiver
 SG_ VCFRONT_turnSignalRightStatus : 52|2@1+ (1,0) [0|3] ""  Receiver

BO_ 1016 ID3F8UI_driverAssistControl: 8 ChassisBus
 SG_ UI_accFollowDistanceSetting : 45|3@1+ (1,0) [0|7] ""  Receiver
 SG_ UI_adaptiveSetSpeedEnable : 39|1@1+ (1,0) [0|1] ""  Receiver
 SG_ UI_alcOffHighwayEnable : 56|1@1+ (1,0) [0|1] ""  Receiver
 SG_ UI_autoSummonEnable : 10|1@1+ (1,0) [0|1] ""  Receiver
 SG_ UI_autopilotControlRequest : 0|1@1+ (1,0) [0|1] ""  Receiver
 SG_ UI_coastToCoast : 9|1@1+ (1,0) [0|1] ""  Receiver
 SG_ UI_curvSpeedAdaptDisable : 4|1@1+ (1,0) [0|1] ""  Receiver
 SG_ UI_curvatureDatabaseOnly : 22|1@1+ (1,0) [0|1] ""  Receiver
 SG_ UI_dasDeveloper : 5|1@1+ (1,0) [0|1] ""  Receiver
 SG_ UI_driveOnMapsEnable : 13|1@1+ (1,0) [0|1] ""  Receiver
 SG_ UI_drivingSide : 40|2@1+ (1,0) [0|2] ""  Receiver
 SG_ UI_enableBrakeLightPulse : 63|1@1+ (1,0) [0|1] ""  Receiver
 SG_ UI_enableClipTelemetry : 42|1@1+ (1,0) [0|1] ""  Receiver
 SG_ UI_enableRoadSegmentTelemetry : 44|1@1+ (1,0) [0|1] ""  Receiver
 SG_ UI_enableTripTelemetry : 43|1@1+ (1,0) [0|1] ""  Receiver
 SG_ UI_enableVinAssociation : 6|1@1+ (1,0) [0|1] ""  Receiver
 SG_ UI_enableVisionOnlyStops : 60|1@1+ (1,0) [0|1] ""  Receiver
 SG_ UI_exceptionListEnable : 11|1@1+ (1,0) [0|1] ""  Receiver
 SG_ UI_followNavRouteEnable : 49|1@1+ (1,0) [0|1] ""  Receiver
 SG_ UI_fuseHPPDisable : 17|1@1+ (1,0) [0|1] ""  Receiver
 SG_ UI_fuseLanesDisable : 16|1@1+ (1,0) [0|1] ""  Receiver
 SG_ UI_fuseVehiclesDisable : 18|1@1+ (1,0) [0|1] ""  Receiver
 SG_ UI_handsOnRequirementDisable : 14|1@1+ (1,0) [0|1] ""  Receiver
 SG_ UI_hasDriveOnNav : 48|1@1+ (1,0) [0|1] ""  Receiver
 SG_ UI_lssElkEnabled : 23|1@1+ (1,0) [0|1] ""  Receiver
 SG_ UI_lssLdwEnabled : 8|1@1+ (1,0) [0|1] ""  Receiver
 SG_ UI_lssLkaEnabled : 7|1@1+ (1,0) [0|1] ""  Receiver
 SG_ UI_roadCheckDisable : 12|1@1+ (1,0) [0|1] ""  Receiver
 SG_ UI_selfParkRequest : 28|4@1+ (1,0) [0|15] ""  Receiver
 SG_ UI_smartSummonType : 58|2@1+ (1,0) [0|2] ""  Receiver
 SG_ UI_source3D : 61|2@1+ (1,0) [0|2] ""  Receiver
 SG_ UI_summonEntryType : 26|2@1+ (1,0) [0|3] ""  Receiver
 SG_ UI_summonExitType : 24|2@1+ (1,0) [0|3] ""  Receiver
 SG_ UI_summonHeartbeat : 2|2@1+ (1,0) [0|3] ""  Receiver
 SG_ UI_summonReverseDist : 32|6@1+ (1,0) [0|63] ""  Receiver
 SG_ UI_ulcBlindSpotConfig : 52|2@1+ (1,0) [0|2] ""  Receiver
 SG_ UI_ulcOffHighway : 15|1@1+ (1,0) [0|1] ""  Receiver
 SG_ UI_ulcSpeedConfig : 50|2@1+ (1,0) [0|3] ""  Receiver
 SG_ UI_ulcStalkConfirm : 1|1@1+ (1,0) [0|1] ""  Receiver
 SG_ UI_undertakeAssistEnable : 38|1@1+ (1,0) [0|1] ""  Receiver
 SG_ UI_validationLoop : 57|1@1+ (1,0) [0|1] ""  Receiver
 SG_ UI_visionSpeedType : 20|2@1+ (1,0) [0|3] ""  Receiver

BO_ 1021 ID3FDUI_autopilotControl: 8 ChassisBus
 SG_ UI_autopilotControlIndex M : 0|3@1+ (1,0) [0|7] ""  Receiver
 SG_ UI_apmv3Branch m1 : 40|3@1+ (1,0) [0|5] ""  Receiver
 SG_ UI_applyEceR79 m1 : 19|1@1+ (1,0) [0|1] ""  Receiver
 SG_ UI_blindspotDistance m0 : 15|3@1+ (1,0) [0|5] ""  Receiver
 SG_ UI_blindspotMinSpeed m0 : 11|4@1+ (1,0) [0|10] ""  Receiver
 SG_ UI_blindspotTTC m0 : 18|3@1+ (1,0) [0|7] ""  Receiver
 SG_ UI_disableBackup m1 : 30|1@1+ (1,0) [0|1] ""  Receiver
 SG_ UI_disableFisheye m1 : 25|1@1+ (1,0) [0|1] ""  Receiver
 SG_ UI_disableLeftPillar m1 : 26|1@1+ (1,0) [0|1] ""  Receiver
 SG_ UI_disableLeftRepeater m1 : 28|1@1+ (1,0) [0|1] ""  Receiver
 SG_ UI_disableMain m1 : 23|1@1+ (1,0) [0|1] ""  Receiver
 SG_ UI_disableNarrow m1 : 24|1@1+ (1,0) [0|1] ""  Receiver
 SG_ UI_disableRadar m1 : 31|1@1+ (1,0) [0|1] ""  Receiver
 SG_ UI_disableRightPillar m1 : 27|1@1+ (1,0) [0|1] ""  Receiver
 SG_ UI_disableRightRepeater m1 : 29|1@1+ (1,0) [0|1] ""  Receiver
 SG_ UI_donAlcProgGoreAbortThres m0 : 29|4@1+ (1,0) [0|9] ""  Receiver
 SG_ UI_donDisableAutoWiperDuration m0 : 4|3@1+ (1,0) [0|6] ""  Receiver
 SG_ UI_donDisableCutin m0 : 24|1@1+ (1,0) [0|1] ""  Receiver
 SG_ UI_donDisableOnAutoWiperSpeed m0 : 7|4@1+ (1,0) [0|15] ""  Receiver
 SG_ UI_donMinGoreWidthForAbortMap m0 : 25|4@1+ (1,0) [0|11] ""  Receiver
 SG_ UI_donMinGoreWidthForAbortNotMap m0 : 33|4@1+ (1,0) [0|11] ""  Receiver
 SG_ UI_donStopEndOfRampBuffer m0 : 21|3@1+ (1,0) [0|4] ""  Receiver
 SG_ UI_driverMonitorConfirmation m1 : 17|1@1+ (1,0) [0|1] ""  Receiver
 SG_ UI_enableAutopilotStopWarning m1 : 44|1@1+ (1,0) [0|1] ""  Receiver
 SG_ UI_enableCabinCamera m1 : 43|1@1+ (1,0) [0|1] ""  Receiver
 SG_ UI_enableCabinCameraTelemetry m1 : 48|1@1+ (1,0) [0|1] ""  Receiver
 SG_ UI_enableMapStops m1 : 20|1@1+ (1,0) [0|1] ""  Receiver
 SG_ UI_factorySummonEnable m1 : 39|1@1+ (1,0) [0|1] ""  Receiver
 SG_ UI_fsdStopsControlEnabled m0 : 38|1@1+ (1,0) [0|1] ""  Receiver
 SG_ UI_fsdVisualizationEnabled m0 : 37|1@1+ (1,0) [0|1] ""  Receiver
 SG_ UI_hardCoreSummon m1 : 47|1@1+ (1,0) [0|1] ""  Receiver
 SG_ UI_homelinkNearby m0 : 45|1@1+ (1,0) [0|1] ""  Receiver
 SG_ UI_hovEnabled m0 : 3|1@1+ (1,0) [0|1] ""  Receiver
 SG_ UI_noStalkConfirmAlertChime m1 : 37|1@1+ (1,0) [0|1] ""  Receiver
 SG_ UI_noStalkConfirmAlertHaptic m1 : 32|1@1+ (1,0) [0|1] ""  Receiver
 SG_ UI_showLaneGraph m1 : 45|1@1+ (1,0) [0|1] ""  Receiver
 SG_ UI_showTrackLabels m1 : 46|1@1+ (1,0) [0|1] ""  Receiver
 SG_ UI_ulcSnooze m1 : 36|1@1+ (1,0) [0|1] ""  Receiver

BO_ 611 ID263VCRIGHT_logging10Hz: 8 VehicleBus
 SG_ VCRIGHT_logging10HzIndex M : 0|3@1+ (1,0) [0|4] ""  Receiver
 SG_ VCRIGHT_EvapPulldownBias m3 : 8|8@1+ (0.4,0) [0|100] "%"  Receiver
 SG_ VCRIGHT_EvapPulldownBiasActive m3 : 16|1@1+ (1,0) [0|1] ""  Receiver
 SG_ VCRIGHT_hvacCabinHumidityLevel m2 : 55|8@1+ (1,0) [0|100] "%"  Receiver
 SG_ VCRIGHT_hvacEstimateWindshieldRH m2 : 39|8@1+ (1,0) [0|150] "%"  Receiver
 SG_ VCRIGHT_hvacFilterLifeDetectActi m2 : 3|1@1+ (1,0) [0|1] ""  Receiver
 SG_ VCRIGHT_hvacFlashFoggingDetected m2 : 63|1@1+ (1,0) [0|1] ""  Receiver
 SG_ VCRIGHT_hvacFoggingRiskLevel m2 : 47|8@1+ (1,0) [0|100] "%"  Receiver
 SG_ VCRIGHT_hvacIntakeActuatorState m2 : 24|2@1+ (1,0) [0|2] ""  Receiver
 SG_ VCRIGHT_hvacIntakeOperationMode m2 : 10|1@1+ (1,0) [0|1] ""  Receiver
 SG_ VCRIGHT_hvacIntakePosition m1 : 56|8@1+ (0.4,0) [0|100] "%"  Receiver
 SG_ VCRIGHT_hvacIntakeTarget m0 : 56|8@1+ (0.4,0) [0|100] "%"  Receiver
 SG_ VCRIGHT_hvacLHBleedActuatorState m2 : 11|2@1+ (1,0) [0|2] ""  Receiver
 SG_ VCRIGHT_hvacLHBleedOperationMode m2 : 4|1@1+ (1,0) [0|1] ""  Receiver
 SG_ VCRIGHT_hvacLHBleedPosition m1 : 8|8@1+ (0.4,0) [0|100] "%"  Receiver
 SG_ VCRIGHT_hvacLHBleedTarget m0 : 8|8@1+ (0.4,0) [0|100] "%"  Receiver
 SG_ VCRIGHT_hvacLHVaneActuatorState m2 : 16|2@1+ (1,0) [0|2] ""  Receiver
 SG_ VCRIGHT_hvacLHVaneOperationMode m2 : 6|1@1+ (1,0) [0|1] ""  Receiver
 SG_ VCRIGHT_hvacLHVanePosition m1 : 24|8@1+ (0.4,0) [0|100] "%"  Receiver
 SG_ VCRIGHT_hvacLHVaneTarget m0 : 24|8@1+ (0.4,0) [0|100] "%"  Receiver
 SG_ VCRIGHT_hvacLowerModeActState m2 : 22|2@1+ (1,0) [0|2] ""  Receiver
 SG_ VCRIGHT_hvacLowerModeOpMode m2 : 9|1@1+ (1,0) [0|1] ""  Receiver
 SG_ VCRIGHT_hvacLowerModePosition m1 : 48|8@1+ (0.4,0) [0|100] "%"  Receiver
 SG_ VCRIGHT_hvacLowerModeTarget m0 : 48|8@1+ (0.4,0) [0|100] "%"  Receiver
 SG_ VCRIGHT_hvacRHBleedActuatorState m2 : 13|2@1+ (1,0) [0|2] ""  Receiver
 SG_ VCRIGHT_hvacRHBleedOperationMode m2 : 5|1@1+ (1,0) [0|1] ""  Receiver
 SG_ VCRIGHT_hvacRHBleedPosition m1 : 16|8@1+ (0.4,0) [0|100] "%"  Receiver
 SG_ VCRIGHT_hvacRHBleedTarget m0 : 16|8@1+ (0.4,0) [0|100] "%"  Receiver
 SG_ VCRIGHT_hvacRHVaneActuatorState m2 : 18|2@1+ (1,0) [0|2] ""  Receiver
 SG_ VCRIGHT_hvacRHVaneOperationMode m2 : 7|1@1+ (1,0) [0|1] ""  Receiver
 SG_ VCRIGHT_hvacRHVanePosition m1 : 32|8@1+ (0.4,0) [0|100] "%"  Receiver
 SG_ VCRIGHT_hvacRHVaneTarget m0 : 32|8@1+ (0.4,0) [0|100] "%"  Receiver
 SG_ VCRIGHT_hvacUpperModeActState m2 : 20|2@1+ (1,0) [0|2] ""  Receiver
 SG_ VCRIGHT_hvacUpperModeOpMode m2 : 8|1@1+ (1,0) [0|1] ""  Receiver
 SG_ VCRIGHT_hvacUpperModePosition m1 : 40|8@1+ (0.4,0) [0|100] "%"  Receiver
 SG_ VCRIGHT_hvacUpperModeTarget m0 : 40|8@1+ (0.4,0) [0|100] "%"  Receiver
 SG_ VCRIGHT_timeLeftToCabinModelInit m2 : 32|7@1+ (1,0) [0|127] ""  Receiver

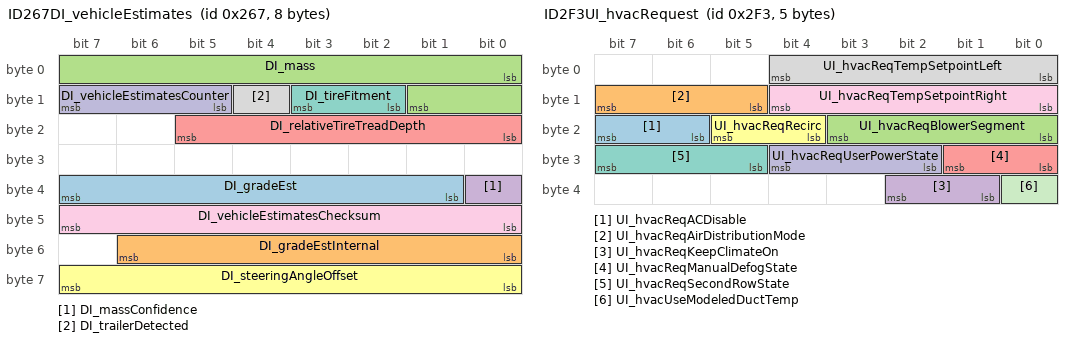
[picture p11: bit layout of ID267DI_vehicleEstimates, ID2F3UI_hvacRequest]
BO_ 615 ID267DI_vehicleEstimates: 8 VehicleBus
 SG_ DI_gradeEst : 33|7@1- (1,0) [-40|40] "%"  Receiver
 SG_ DI_gradeEstInternal : 48|7@1- (1,0) [-40|40] "%"  Receiver
 SG_ DI_mass : 0|10@1+ (5,1900) [1900|7010] "kg"  Receiver
 SG_ DI_massConfidence : 32|1@1+ (1,0) [0|1] ""  Receiver
 SG_ DI_relativeTireTreadDepth : 16|6@1- (0.2,0) [-6.2|6.2] "mm"  Receiver
 SG_ DI_steeringAngleOffset : 56|8@1- (0.2,0) [-25.6|25.4] "Deg"  Receiver
 SG_ DI_tireFitment : 10|2@1+ (1,0) [0|3] ""  Receiver
 SG_ DI_trailerDetected : 12|1@1+ (1,0) [0|1] ""  Receiver
 SG_ DI_vehicleEstimatesChecksum : 40|8@1+ (1,0) [0|255] ""  Receiver
 SG_ DI_vehicleEstimatesCounter : 13|3@1+ (1,0) [0|7] ""  Receiver

BO_ 642 ID282VCLEFT_hvacBlowerFeedback: 8 VehicleBus
 SG_ VCLEFT_blowerIndex M : 0|2@1+ (1,0) [0|1] ""  Receiver
 SG_ VCLEFT_hvacBlowerCBCCtrlState m1 : 58|3@1+ (1,0) [0|4] ""  Receiver
 SG_ VCLEFT_hvacBlowerCBCEstState m1 : 54|4@1+ (1,0) [0|14] ""  Receiver
 SG_ VCLEFT_hvacBlowerEnabled m0 : 2|1@1+ (1,0) [0|1] ""  Receiver
 SG_ VCLEFT_hvacBlowerFETTemp m0 : 44|7@1+ (1.5,-40) [-40|149] "C"  Receiver
 SG_ VCLEFT_hvacBlowerFault m0 : 59|1@1+ (1,0) [0|1] ""  Receiver
 SG_ VCLEFT_hvacBlowerIPhase0 m1 : 10|8@1+ (0.2,0) [0|50] "A"  Receiver
 SG_ VCLEFT_hvacBlowerIPhase1 m1 : 18|8@1+ (0.2,0) [0|50] "A"  Receiver
 SG_ VCLEFT_hvacBlowerIPhase2 m1 : 26|8@1+ (0.2,0) [0|50] "A"  Receiver
 SG_ VCLEFT_hvacBlowerITerm m0 : 51|7@1+ (0.05,-1.5) [-1.5|4.5] "Nm"  Receiver
 SG_ VCLEFT_hvacBlowerInitd m0 : 58|1@1+ (1,0) [0|1] ""  Receiver
 SG_ VCLEFT_hvacBlowerLimitFETTemps m0 : 60|1@1+ (1,0) [0|1] ""  Receiver
 SG_ VCLEFT_hvacBlowerOutputDuty m0 : 3|7@1+ (1,0) [0|100] "%"  Receiver
 SG_ VCLEFT_hvacBlowerPowerOn m0 : 61|1@1+ (1,0) [0|1] ""  Receiver
 SG_ VCLEFT_hvacBlowerRPMActual m0 : 20|10@1+ (10,0) [0|10000] "rpm"  Receiver
 SG_ VCLEFT_hvacBlowerRPMTarget m0 : 10|10@1+ (10,0) [0|10000] "rpm"  Receiver
 SG_ VCLEFT_hvacBlowerRs m1 : 2|8@1+ (0.25,0) [0|60] "mOhm"  Receiver
 SG_ VCLEFT_hvacBlowerRsOnlineActive m1 : 61|1@1+ (1,0) [0|1] ""  Receiver
 SG_ VCLEFT_hvacBlowerSpiError m0 : 62|1@1+ (1,0) [0|1] ""  Receiver
 SG_ VCLEFT_hvacBlowerTorque m0 : 34|10@1+ (0.006,-1.5) [-1.5|4.5] "Nm"  Receiver
 SG_ VCLEFT_hvacBlower_IO_CBC_HEAD m1 : 34|4@1+ (1,0) [0|15] ""  Receiver
 SG_ VCLEFT_hvacBlower_IO_CBC_Status m1 : 43|1@1+ (1,0) [0|1] ""  Receiver
 SG_ VCLEFT_hvacBlower_IO_CBC_TAIL m1 : 38|4@1+ (1,0) [0|15] ""  Receiver
 SG_ VCLEFT_hvacBlower_IO_CBC_TAIL_va m1 : 42|1@1+ (1,0) [0|1] ""  Receiver
 SG_ VCLEFT_hvacBlower_IO_CBC_numUart m1 : 46|8@1+ (1,0) [0|255] ""  Receiver

BO_ 755 ID2F3UI_hvacRequest: 5 VehicleBus
 SG_ UI_hvacReqACDisable : 22|2@1+ (1,0) [0|2] ""  Receiver
 SG_ UI_hvacReqAirDistributionMode : 13|3@1+ (1,0) [0|7] ""  Receiver
 SG_ UI_hvacReqBlowerSegment : 16|4@1+ (1,0) [0|11] ""  Receiver
 SG_ UI_hvacReqKeepClimateOn : 33|2@1+ (1,0) [0|3] ""  Receiver
 SG_ UI_hvacReqManualDefogState : 24|2@1+ (1,0) [0|2] ""  Receiver
 SG_ UI_hvacReqRecirc : 20|2@1+ (1,0) [0|2] ""  Receiver
 SG_ UI_hvacReqSecondRowState : 29|3@1+ (1,0) [0|4] ""  Receiver
 SG_ UI_hvacReqTempSetpointLeft : 0|5@1+ (0.5,15) [15|28] "C"  Receiver
 SG_ UI_hvacReqTempSetpointRight : 8|5@1+ (0.5,15) [15|28] "C"  Receiver
 SG_ UI_hvacReqUserPowerState : 26|3@1+ (1,0) [0|4] ""  Receiver
 SG_ UI_hvacUseModeledDuctTemp : 32|1@1+ (1,0) [0|1] ""  Receiver

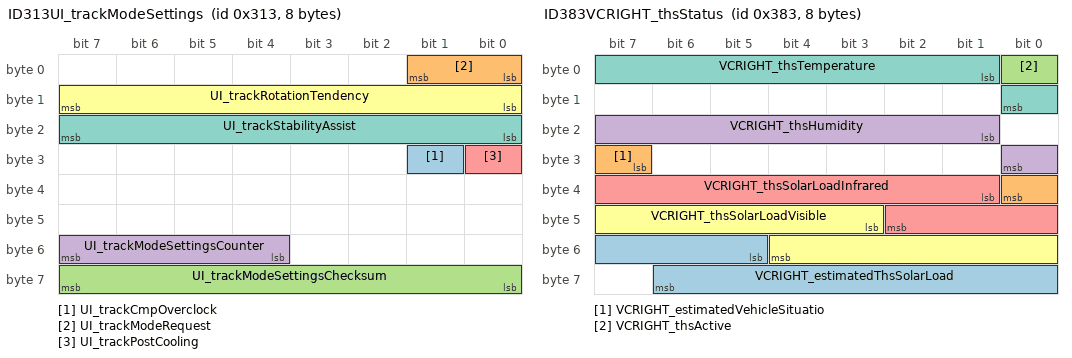
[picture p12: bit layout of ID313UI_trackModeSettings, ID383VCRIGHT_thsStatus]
BO_ 787 ID313UI_trackModeSettings: 8 VehicleBus
 SG_ UI_trackCmpOverclock : 25|1@1+ (1,0) [0|1] ""  Receiver
 SG_ UI_trackModeRequest : 0|2@1+ (1,0) [0|2] ""  Receiver
 SG_ UI_trackModeSettingsChecksum : 56|8@1+ (1,0) [0|255] ""  Receiver
 SG_ UI_trackModeSettingsCounter : 52|4@1+ (1,0) [0|15] ""  Receiver
 SG_ UI_trackPostCooling : 24|1@1+ (1,0) [0|1] ""  Receiver
 SG_ UI_trackRotationTendency : 8|8@1+ (0.5,0) [0|100] "%"  Receiver
 SG_ UI_trackStabilityAssist : 16|8@1+ (0.5,0) [0|100] "%"  Receiver

BO_ 821 ID335RearDIinfo: 8 VehicleBus
 SG_ DIR_infoIndex M : 0|8@1+ (1,0) [0|255] ""  Receiver
 SG_ DIR_FPGA_version m16 : 48|8@1+ (1,0) [0|255] ""  Receiver
 SG_ DIR_appGitHash m17 : 8|56@1+ (1,0) [0|7.20576E+016] ""  Receiver
 SG_ DIR_applicationCrc m13 : 32|32@1+ (1,0) [0|4294970000] ""  Receiver
 SG_ DIR_assemblyId m11 : 24|8@1+ (1,0) [0|255] ""  Receiver
 SG_ DIR_bootGitHash m18 : 8|56@1+ (1,0) [0|7.20576E+016] ""  Receiver
 SG_ DIR_bootloaderCrc m20 : 32|32@1+ (1,0) [0|4294970000] ""  Receiver
 SG_ DIR_buildConfigurationId m10 : 16|16@1+ (1,0) [0|65535] ""  Receiver
 SG_ DIR_buildType m10 : 8|3@1+ (1,0) [0|4] ""  Receiver
 SG_ DIR_componentId m10 : 48|16@1+ (1,0) [0|65535] ""  Receiver
 SG_ DIR_hardwareId m10 : 32|8@1+ (1,0) [0|252] ""  Receiver
 SG_ DIR_infoBootLdUdsProtocolVersion m20 : 8|8@1+ (1,0) [0|255] ""  Receiver
 SG_ DIR_oilPumpAppCrc m16 : 16|32@1+ (1,0) [0|4294970000] ""  Receiver
 SG_ DIR_oilPumpBuildType m16 : 8|3@1+ (1,0) [0|4] ""  Receiver
 SG_ DIR_pcbaId m11 : 16|8@1+ (1,0) [0|255] ""  Receiver
 SG_ DIR_platformTyp m19 : 8|8@1+ (1,0) [0|255] ""  Receiver
 SG_ DIR_subUsageId m11 : 48|16@1+ (1,0) [0|65535] ""  Receiver
 SG_ DIR_subcomponentGitHash m31 : 8|56@1+ (1,0) [0|7.20576E+016] ""  Receiver
 SG_ DIR_usageId m11 : 32|16@1+ (1,0) [0|65535] ""  Receiver

BO_ 899 ID383VCRIGHT_thsStatus: 8 VehicleBus
 SG_ VCRIGHT_estimatedThsSolarLoad : 53|10@1+ (1,0) [0|1022] "W/m2"  Receiver
 SG_ VCRIGHT_estimatedVehicleSituatio : 31|2@1+ (1,0) [0|2] ""  Receiver
 SG_ VCRIGHT_thsActive : 0|1@1+ (1,0) [0|1] ""  Receiver
 SG_ VCRIGHT_thsHumidity : 17|8@1+ (1,0) [0|100] "%"  Receiver
 SG_ VCRIGHT_thsSolarLoadInfrared : 33|10@1+ (1,0) [0|1022] "W/m2"  Receiver
 SG_ VCRIGHT_thsSolarLoadVisible : 43|10@1+ (1,0) [0|1022] "W/m2"  Receiver
 SG_ VCRIGHT_thsTemperature : 1|8@1- (1,-40) [-40|150] "C"  Receiver

BO_ 915 ID393VCRIGHT_epbmDebug: 8 VehicleBus
 SG_ VCRIGHT_epbmDebugIndex M : 0|1@1+ (1,0) [0|1] ""  Receiver
 SG_ VCRIGHT_cdpEnumDummy m1 : 24|2@1+ (1,0) [0|2] ""  Receiver
 SG_ VCRIGHT_epbFaultStatus m0 : 58|2@1+ (1,0) [0|3] ""  Receiver
 SG_ VCRIGHT_epbMotorCurrent m0 : 5|11@1+ (0.01,0) [0|20.47] "A"  Receiver
 SG_ VCRIGHT_epbSummonState m0 : 45|3@1+ (1,0) [0|6] ""  Receiver
 SG_ VCRIGHT_epbUnitStatus m0 : 51|5@1+ (1,0) [0|22] ""  Receiver
 SG_ VCRIGHT_epbmApplyVoltage m0 : 16|11@1+ (0.01,0) [0|20.47] "A"  Receiver
 SG_ VCRIGHT_epbmCaliperState m0 : 1|3@1+ (1,0) [0|6] ""  Receiver
 SG_ VCRIGHT_epbmDynApplyingAllowed m1 : 9|1@1+ (1,0) [0|1] ""  Receiver
 SG_ VCRIGHT_epbmDynamicAllowed m1 : 2|1@1+ (1,0) [0|1] ""  Receiver
 SG_ VCRIGHT_epbmFaultAllowed m1 : 11|1@1+ (1,0) [0|1] ""  Receiver
 SG_ VCRIGHT_epbmFaultStatus m0 : 56|2@1+ (1,0) [0|3] ""  ui
 SG_ VCRIGHT_epbmMotorEnabled m0 : 4|1@1+ (1,0) [0|1] ""  Receiver
 SG_ VCRIGHT_epbmOpenAllowed m1 : 1|1@1+ (1,0) [0|1] ""  Receiver
 SG_ VCRIGHT_epbmParkAllowed m1 : 3|1@1+ (1,0) [0|1] ""  Receiver
 SG_ VCRIGHT_epbmParkingAllowed m1 : 8|1@1+ (1,0) [0|1] ""  Receiver
 SG_ VCRIGHT_epbmReleaseVoltage m0 : 27|11@1+ (0.01,0) [0|20.47] "A"  Receiver
 SG_ VCRIGHT_epbmReleasingAllowed m1 : 10|1@1+ (1,0) [0|1] ""  Receiver
 SG_ VCRIGHT_epbmServiceAllowed m1 : 5|1@1+ (1,0) [0|1] ""  Receiver
 SG_ VCRIGHT_epbmStartAllowed m1 : 4|1@1+ (1,0) [0|1] ""  Receiver
 SG_ VCRIGHT_epbmSummonAllowed m1 : 12|1@1+ (1,0) [0|1] ""  Receiver
 SG_ VCRIGHT_epbmSummonParkAllowed m1 : 13|1@1+ (1,0) [0|1] ""  Receiver
 SG_ VCRIGHT_epbmSummonReleaseAllowed m1 : 14|1@1+ (1,0) [0|1] ""  Receiver
 SG_ VCRIGHT_epbmSummonState m0 : 48|3@1+ (1,0) [0|6] ""  Receiver
 SG_ VCRIGHT_epbmSystemStatus m0 : 60|4@1+ (1,0) [0|8] ""  Receiver
 SG_ VCRIGHT_epbmUnknownAllowed m1 : 16|1@1+ (1,0) [0|1] ""  Receiver
 SG_ VCRIGHT_epbmWinchAllowed m1 : 6|1@1+ (1,0) [0|1] ""  Receiver
 SG_ VCRIGHT_epbmWinchReleaseAllowed m1 : 7|1@1+ (1,0) [0|1] ""  Receiver
 SG_ VCRIGHT_summonActiveAllowed m1 : 19|1@1+ (1,0) [0|1] ""  Receiver
 SG_ VCRIGHT_summonArmedAllowed m1 : 18|1@1+ (1,0) [0|1] ""  Receiver
 SG_ VCRIGHT_summonCompleteAllowed m1 : 20|1@1+ (1,0) [0|1] ""  Receiver
 SG_ VCRIGHT_summonFaultAllowed m1 : 21|1@1+ (1,0) [0|1] ""  Receiver
 SG_ VCRIGHT_summonFaultReason m0 : 40|5@1+ (1,0) [0|28] ""  Receiver
 SG_ VCRIGHT_summonIdleAllowed m1 : 17|1@1+ (1,0) [0|1] ""  Receiver
 SG_ VCRIGHT_summonInitAllowed m1 : 15|1@1+ (1,0) [0|1] ""  Receiver
 SG_ VCRIGHT_summonUnavailableAllowed m1 : 22|1@1+ (1,0) [0|1] ""  Receiver

BO_ 947 ID3B3UI_vehicleControl2: 4 VehicleBus
 SG_ UI_PINToDriveEnabled : 6|1@1+ (1,0) [0|1] ""  Receiver
 SG_ UI_PINToDrivePassed : 7|1@1+ (1,0) [0|1] ""  Receiver
 SG_ UI_UMCUpdateInhibit : 2|1@1+ (1,0) [0|1] ""  Receiver
 SG_ UI_VCLEFTFeature1 : 15|1@1+ (1,0) [0|1] ""  Receiver
 SG_ UI_VCSECFeature1 : 14|1@1+ (1,0) [0|1] ""  Receiver
 SG_ UI_WCUpdateInhibit : 3|1@1+ (1,0) [0|1] ""  Receiver
 SG_ UI_alarmTriggerRequest : 13|1@1+ (1,0) [0|1] ""  Receiver
 SG_ UI_autoRollWindowsOnLockEnable : 29|1@1+ (1,0) [0|1] ""  Receiver
 SG_ UI_autopilotPowerStateRequest : 25|2@1+ (1,0) [0|2] ""  Receiver
 SG_ UI_batteryPreconditioningRequest : 23|1@1+ (1,0) [0|1] ""  Receiver
 SG_ UI_coastDownMode : 24|1@1+ (1,0) [0|1] ""  Receiver
 SG_ UI_conditionalLoggingEnabledVCSE : 31|1@1+ (1,0) [0|1] ""  Receiver
 SG_ UI_efuseMXResistanceEstArmed : 30|1@1+ (1,0) [0|1] ""  Receiver
 SG_ UI_freeRollModeRequest : 19|1@1+ (1,0) [0|1] ""  Receiver
 SG_ UI_gloveboxRequest : 0|1@1+ (1,0) [0|1] ""  Receiver
 SG_ UI_lightSwitch : 9|3@1+ (1,0) [0|4] ""  Receiver
 SG_ UI_locksPanelActive : 5|1@1+ (1,0) [0|1] ""  Receiver
 SG_ UI_readyToAddKey : 12|1@1+ (1,0) [0|1] ""  Receiver
 SG_ UI_shorted12VCellTestMode : 27|2@1+ (1,0) [0|2] ""  Receiver
 SG_ UI_soundHornOnLock : 4|1@1+ (1,0) [0|1] ""  Receiver
 SG_ UI_summonState : 16|2@1+ (1,0) [0|3] ""  Receiver
 SG_ UI_trunkRequest : 1|1@1+ (1,0) [0|1] ""  Receiver
 SG_ UI_userPresent : 18|1@1+ (1,0) [0|1] ""  Receiver
 SG_ UI_windowRequest : 20|3@1+ (1,0) [0|4] ""  Receiver

BO_ 963 ID3C3VCRIGHT_switchStatus: 7 VehicleBus
 SG_ VCRIGHT_2RowSeatReclineSwitch : 54|1@1+ (1,0) [0|1] ""  Receiver
 SG_ VCRIGHT_btnWindowAutoDownRF : 27|1@1+ (1,0) [0|1] ""  Receiver
 SG_ VCRIGHT_btnWindowAutoDownRR : 31|1@1+ (1,0) [0|1] ""  Receiver
 SG_ VCRIGHT_btnWindowAutoUpRF : 25|1@1+ (1,0) [0|1] ""  Receiver
 SG_ VCRIGHT_btnWindowAutoUpRR : 29|1@1+ (1,0) [0|1] ""  Receiver
 SG_ VCRIGHT_btnWindowDownRF : 26|1@1+ (1,0) [0|1] ""  Receiver
 SG_ VCRIGHT_btnWindowDownRR : 30|1@1+ (1,0) [0|1] ""  Receiver
 SG_ VCRIGHT_btnWindowSwPackAutoDwnLF : 35|1@1+ (1,0) [0|1] ""  Receiver
 SG_ VCRIGHT_btnWindowSwPackAutoDwnLR : 39|1@1+ (1,0) [0|1] ""  Receiver
 SG_ VCRIGHT_btnWindowSwPackAutoDwnRR : 52|1@1+ (1,0) [0|1] ""  Receiver
 SG_ VCRIGHT_btnWindowSwPackAutoUpLF : 33|1@1+ (1,0) [0|1] ""  Receiver
 SG_ VCRIGHT_btnWindowSwPackAutoUpLR : 37|1@1+ (1,0) [0|1] ""  Receiver
 SG_ VCRIGHT_btnWindowSwPackAutoUpRR : 50|1@1+ (1,0) [0|1] ""  Receiver
 SG_ VCRIGHT_btnWindowSwPackDownLF : 34|1@1+ (1,0) [0|1] ""  Receiver
 SG_ VCRIGHT_btnWindowSwPackDownLR : 38|1@1+ (1,0) [0|1] ""  Receiver
 SG_ VCRIGHT_btnWindowSwPackDownRR : 51|1@1+ (1,0) [0|1] ""  Receiver
 SG_ VCRIGHT_btnWindowSwPackUpLF : 32|1@1+ (1,0) [0|1] ""  Receiver
 SG_ VCRIGHT_btnWindowSwPackUpLR : 36|1@1+ (1,0) [0|1] ""  Receiver
 SG_ VCRIGHT_btnWindowSwPackUpRR : 49|1@1+ (1,0) [0|1] ""  Receiver
 SG_ VCRIGHT_btnWindowUpRF : 24|1@1+ (1,0) [0|1] ""  Receiver
 SG_ VCRIGHT_btnWindowUpRR : 28|1@1+ (1,0) [0|1] ""  Receiver
 SG_ VCRIGHT_frontBuckleSwitch : 40|2@1+ (1,0) [0|3] ""  Receiver
 SG_ VCRIGHT_frontOccupancySwitch : 42|2@1+ (1,0) [0|3] ""  Receiver
 SG_ VCRIGHT_frontSeatBackrestBack : 12|2@1+ (1,0) [0|3] ""  Receiver
 SG_ VCRIGHT_frontSeatBackrestForward : 14|2@1+ (1,0) [0|3] ""  Receiver
 SG_ VCRIGHT_frontSeatLiftDown : 8|2@1+ (1,0) [0|3] ""  Receiver
 SG_ VCRIGHT_frontSeatLiftUp : 10|2@1+ (1,0) [0|3] ""  Receiver
 SG_ VCRIGHT_frontSeatLumbarDown : 16|2@1+ (1,0) [0|3] ""  Receiver
 SG_ VCRIGHT_frontSeatLumbarIn : 20|2@1+ (1,0) [0|3] ""  Receiver
 SG_ VCRIGHT_frontSeatLumbarOut : 22|2@1+ (1,0) [0|3] ""  Receiver
 SG_ VCRIGHT_frontSeatLumbarUp : 18|2@1+ (1,0) [0|3] ""  Receiver
 SG_ VCRIGHT_frontSeatTiltDown : 4|2@1+ (1,0) [0|3] ""  Receiver
 SG_ VCRIGHT_frontSeatTiltUp : 6|2@1+ (1,0) [0|3] ""  Receiver
 SG_ VCRIGHT_frontSeatTrackBack : 0|2@1+ (1,0) [0|3] ""  Receiver
 SG_ VCRIGHT_frontSeatTrackForward : 2|2@1+ (1,0) [0|3] ""  Receiver
 SG_ VCRIGHT_liftgateShutfaceSwitchPr : 53|1@1+ (1,0) [0|1] ""  Receiver
 SG_ VCRIGHT_rearCenterBuckleSwitch : 44|2@1+ (1,0) [0|3] ""  Receiver
 SG_ VCRIGHT_rearRightBuckleSwitch : 46|2@1+ (1,0) [0|3] ""  Receiver
 SG_ VCRIGHT_trunkExtReleasePressed : 48|1@1+ (1,0) [0|1] ""  Receiver

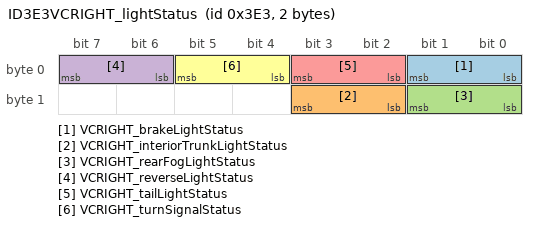
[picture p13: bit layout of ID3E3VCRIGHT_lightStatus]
BO_ 995 ID3E3VCRIGHT_lightStatus: 2 VehicleBus
 SG_ VCRIGHT_brakeLightStatus : 0|2@1+ (1,0) [0|3] ""  Receiver
 SG_ VCRIGHT_interiorTrunkLightStatus : 10|2@1+ (1,0) [0|3] ""  Receiver
 SG_ VCRIGHT_rearFogLightStatus : 8|2@1+ (1,0) [0|3] ""  Receiver
 SG_ VCRIGHT_reverseLightStatus : 6|2@1+ (1,0) [0|3] ""  Receiver
 SG_ VCRIGHT_tailLightStatus : 2|2@1+ (1,0) [0|3] ""  Receiver
 SG_ VCRIGHT_turnSignalStatus : 4|2@1+ (1,0) [0|3] ""  Receiver

CM_ SG_ 130 UI_tripPlanningActive "Navigation Active";
CM_ SG_ 257 RCM_pitchRate "Pitch";
CM_ SG_ 257 RCM_rollRate "Roll";
CM_ SG_ 257 RCM_yawRate "Yaw";
CM_ SG_ 273 RCM_lateralAccel "L/R Acceleration";
CM_ SG_ 273 RCM_longitudinalAccel "F/B Acceleration";
CM_ SG_ 273 RCM_verticalAccel "Vertical Acceleration";
CM_ SG_ 692 PCS_dcdcHvBusVolt "DCDC HV Voltage";
CM_ SG_ 692 PCS_dcdcLvBusVolt "DCDC 12v Voltage";
CM_ SG_ 692 PCS_dcdcLvOutputCurrent "DCDC 12v Output Current";
CM_ SG_ 985 UI_gpsVehicleHeading "GPS Heading";
CM_ SG_ 985 UI_gpsVehicleSpeed "GPS Speed";
CM_ SG_ 1011 UI_odometer "UI Odometer";
CM_ SG_ 615 DI_gradeEst "Estimated Grade";
CM_ SG_ 615 DI_mass "Estimated Mass";
CM_ SG_ 642 VCLEFT_hvacBlowerRPMActual "HVAC Blower Speed";
BA_DEF_ BO_  "GenMsgSendType" ENUM  "Cyclic","SendType1","SendType2","SendType3","SendType4","SendType5","SendType6","SendType7","SendType8","SendType9";
BA_DEF_ BO_  "GenMsgCycleTime" INT 0 0;
BA_DEF_  "BusType" STRING ;
BA_DEF_ SG_  "GenSigEnvVarType" ENUM  "Cyclic","SendType1","SendType2","SendType3","SendType4","SendType5","SendType6","SendType7","SendType8","SendType9","No","Yes","No","Yes","No","Yes","No","Yes","int","float","undef";
BA_DEF_  "Modified" STRING ;
BA_DEF_ SG_  "SystemSignalLongSymbol" STRING ;
BA_DEF_ BO_  "SystemMessageLongSymbol" STRING ;
BA_DEF_DEF_  "GenMsgSendType" "Cyclic";
BA_DEF_DEF_  "GenMsgCycleTime" 0;
BA_DEF_DEF_  "BusType" "";
BA_DEF_DEF_  "GenSigEnvVarType" "";
BA_DEF_DEF_  "Modified" "JW2021Aug29";
BA_DEF_DEF_  "SystemMessageLongSymbol" "";
BA_ "BusType" "CAN";
BA_ "SystemSignalLongSymbol" SG_ 291 UI_a037_AudioWatchdogXrunStormEr "UI_a037_AudioWatchdogXrunStormError";
BA_ "SystemSignalLongSymbol" SG_ 291 UI_a038_AudioWatchdogA2bI2cLocku "UI_a038_AudioWatchdogA2bI2cLockupError";
BA_ "SystemSignalLongSymbol" SG_ 291 UI_a048_AudioPremiumAmpCheckFail "UI_a048_AudioPremiumAmpCheckFailed";
BA_ "SystemSignalLongSymbol" SG_ 291 UI_a056_ManualECallButtonDisconn "UI_a056_ManualECallButtonDisconnected";
BA_ "SystemSignalLongSymbol" SG_ 611 VCRIGHT_hvacFilterLifeDetectActi "VCRIGHT_hvacFilterLifeDetectActive";
BA_ "SystemSignalLongSymbol" SG_ 642 VCLEFT_hvacBlower_IO_CBC_TAIL_va "VCLEFT_hvacBlower_IO_CBC_TAIL_valid";
BA_ "SystemSignalLongSymbol" SG_ 642 VCLEFT_hvacBlower_IO_CBC_numUart "VCLEFT_hvacBlower_IO_CBC_numUartErr";
BA_ "SystemSignalLongSymbol" SG_ 899 VCRIGHT_estimatedVehicleSituatio "VCRIGHT_estimatedVehicleSituation";
BA_ "SystemSignalLongSymbol" SG_ 963 VCRIGHT_liftgateShutfaceSwitchPr "VCRIGHT_liftgateShutfaceSwitchPressed";
VAL_ 12 UI_autopilotTrial 3 "ACTIVE" 0 "NONE" 1 "START" 2 "STOP" ;
VAL_ 12 UI_cellNetworkTechnology 9 "CELL_NETWORK_CDMA" 2 "CELL_NETWORK_EDGE" 1 "CELL_NETWORK_GPRS" 8 "CELL_NETWORK_GSM" 4 "CELL_NETWORK_HSDPA" 6 "CELL_NETWORK_HSPA" 5 "CELL_NETWORK_HSUPA" 7 "CELL_NETWORK_LTE" 0 "CELL_NETWORK_NONE" 15 "CELL_NETWORK_SNA" 3 "CELL_NETWORK_UMTS" 10 "CELL_NETWORK_WCDMA" ;
VAL_ 12 UI_cellSignalBars 5 "FIVE" 4 "FOUR" 1 "ONE" 7 "SNA" 3 "THREE" 2 "TWO" 0 "ZERO" ;
VAL_ 12 UI_factoryReset 3 "CUSTOMER" 1 "DEVELOPER" 2 "DIAGNOSTIC" 0 "NONE_SNA" ;
VAL_ 130 UI_energyAtDestination -32768 "SNA" -32767 "TRIP_TOO_LONG" ;
VAL_ 130 UI_hindsightEnergy -32768 "SNA" -32767 "TRIP_TOO_LONG" ;
VAL_ 130 UI_predictedEnergy -32768 "SNA" -32767 "TRIP_TOO_LONG" ;
VAL_ 257 RCM_pitchRate -16384 "SNA" ;
VAL_ 257 RCM_pitchRateQF 3 "FAULTED" 0 "INIT" 2 "TEMP_INVALID" 1 "VALID" ;
VAL_ 257 RCM_rollRate -16384 "SNA" ;
VAL_ 257 RCM_rollRateQF 3 "FAULTED" 0 "INIT" 2 "TEMP_INVALID" 1 "VALID" ;
VAL_ 257 RCM_yawRate -32768 "SNA" ;
VAL_ 257 RCM_yawRateQF 0 "FAULTED" 1 "NOT_FAULTED" ;
VAL_ 273 RCM_lateralAccel -32768 "SNA" ;
VAL_ 273 RCM_lateralAccelQF 0 "FAULTED" 1 "NOT_FAULTED" ;
VAL_ 273 RCM_longitudinalAccel -32768 "SNA" ;
VAL_ 273 RCM_longitudinalAccelQF 0 "FAULTED" 1 "NOT_FAULTED" ;
VAL_ 273 RCM_verticalAccel -32768 "SNA" ;
VAL_ 273 RCM_verticalAccelQF 0 "FAULTED" 1 "NOT_FAULTED" ;
VAL_ 258 VCLEFT_frontLatchStatus 5 "LATCH_AJAR" 2 "LATCH_CLOSED" 3 "LATCH_CLOSING" 7 "LATCH_DEFAULT" 8 "LATCH_FAULT" 1 "LATCH_OPENED" 4 "LATCH_OPENING" 0 "LATCH_SNA" 6 "LATCH_TIMEOUT" ;
VAL_ 258 VCLEFT_mirrorFoldState 1 "MIRROR_FOLD_STATE_FOLDED" 3 "MIRROR_FOLD_STATE_FOLDING" 2 "MIRROR_FOLD_STATE_UNFOLDED" 4 "MIRROR_FOLD_STATE_UNFOLDING" 0 "MIRROR_FOLD_STATE_UNKNOWN" ;
VAL_ 258 VCLEFT_mirrorHeatState 4 "HEATER_STATE_FAULT" 2 "HEATER_STATE_OFF" 3 "HEATER_STATE_OFF_UNAVAILABLE" 1 "HEATER_STATE_ON" 0 "HEATER_STATE_SNA" ;
VAL_ 258 VCLEFT_mirrorRecallState 0 "MIRROR_RECALL_STATE_INIT" 1 "MIRROR_RECALL_STATE_RECALLING_AXIS_1" 2 "MIRROR_RECALL_STATE_RECALLING_AXIS_2" 3 "MIRROR_RECALL_STATE_RECALLING_COMPLETE" 4 "MIRROR_RECALL_STATE_RECALLING_FAILED" 5 "MIRROR_RECALL_STATE_RECALLING_STOPPED" ;
VAL_ 258 VCLEFT_mirrorState 3 "MIRROR_STATE_FOLD_UNFOLD" 0 "MIRROR_STATE_IDLE" 4 "MIRROR_STATE_RECALL" 1 "MIRROR_STATE_TILT_X" 2 "MIRROR_STATE_TILT_Y" ;
VAL_ 258 VCLEFT_rearLatchStatus 5 "LATCH_AJAR" 2 "LATCH_CLOSED" 3 "LATCH_CLOSING" 7 "LATCH_DEFAULT" 8 "LATCH_FAULT" 1 "LATCH_OPENED" 4 "LATCH_OPENING" 0 "LATCH_SNA" 6 "LATCH_TIMEOUT" ;
VAL_ 259 VCRIGHT_frontLatchStatus 5 "LATCH_AJAR" 2 "LATCH_CLOSED" 3 "LATCH_CLOSING" 7 "LATCH_DEFAULT" 8 "LATCH_FAULT" 1 "LATCH_OPENED" 4 "LATCH_OPENING" 0 "LATCH_SNA" 6 "LATCH_TIMEOUT" ;
VAL_ 259 VCRIGHT_mirrorFoldState 1 "MIRROR_FOLD_STATE_FOLDED" 3 "MIRROR_FOLD_STATE_FOLDING" 2 "MIRROR_FOLD_STATE_UNFOLDED" 4 "MIRROR_FOLD_STATE_UNFOLDING" 0 "MIRROR_FOLD_STATE_UNKNOWN" ;
VAL_ 259 VCRIGHT_mirrorRecallState 0 "MIRROR_RECALL_STATE_INIT" 1 "MIRROR_RECALL_STATE_RECALLING_AXIS_1" 2 "MIRROR_RECALL_STATE_RECALLING_AXIS_2" 3 "MIRROR_RECALL_STATE_RECALLING_COMPLETE" 4 "MIRROR_RECALL_STATE_RECALLING_FAILED" 5 "MIRROR_RECALL_STATE_RECALLING_STOPPED" ;
VAL_ 259 VCRIGHT_mirrorState 3 "MIRROR_STATE_FOLD_UNFOLD" 0 "MIRROR_STATE_IDLE" 4 "MIRROR_STATE_RECALL" 1 "MIRROR_STATE_TILT_X" 2 "MIRROR_STATE_TILT_Y" ;
VAL_ 259 VCRIGHT_rearLatchStatus 5 "LATCH_AJAR" 2 "LATCH_CLOSED" 3 "LATCH_CLOSING" 7 "LATCH_DEFAULT" 8 "LATCH_FAULT" 1 "LATCH_OPENED" 4 "LATCH_OPENING" 0 "LATCH_SNA" 6 "LATCH_TIMEOUT" ;
VAL_ 259 VCRIGHT_trunkLatchStatus 5 "LATCH_AJAR" 2 "LATCH_CLOSED" 3 "LATCH_CLOSING" 7 "LATCH_DEFAULT" 8 "LATCH_FAULT" 1 "LATCH_OPENED" 4 "LATCH_OPENING" 0 "LATCH_SNA" 6 "LATCH_TIMEOUT" ;
VAL_ 322 VCLEFT_liftgateStatusIndex 0 "LIFTGATE_STATUS_INDEX_0" 1 "LIFTGATE_STATUS_INDEX_1" 2 "LIFTGATE_STATUS_INDEX_INVALID" ;
VAL_ 322 VCLEFT_liftgateLatchRequest 1 "LATCH_REQUEST_CINCH" 3 "LATCH_REQUEST_FORCE_RELEASE" 0 "LATCH_REQUEST_NONE" 2 "LATCH_REQUEST_RELEASE" 4 "LATCH_REQUEST_RESET" ;
VAL_ 322 VCLEFT_liftgateMvmntNotAllowedCo 4 "PLG_MVMT_NOT_ALLOWED_EXTERIOR_PRESS_AT_MAX_OPEN" 5 "PLG_MVMT_NOT_ALLOWED_LOCKED" 1 "PLG_MVMT_NOT_ALLOWED_LOW_12V" 0 "PLG_MVMT_NOT_ALLOWED_NONE" 3 "PLG_MVMT_NOT_ALLOWED_UNCALIBRATED" 2 "PLG_MVMT_NOT_ALLOWED_VEHICLE_AT_SPEED" ;
VAL_ 322 VCLEFT_liftgatePhysicalChimeRequ 0 "LIFTGATE_CHIME_REQUEST_NONE" 4 "LIFTGATE_CHIME_REQUEST_ONE_LONG" 1 "LIFTGATE_CHIME_REQUEST_ONE_SHORT" 3 "LIFTGATE_CHIME_REQUEST_THREE_SHORT" 2 "LIFTGATE_CHIME_REQUEST_TWO_SHORT" ;
VAL_ 322 VCLEFT_liftgateRequestSource 5 "PLG_REQUEST_SOURCE_CLOSE_ALL" 2 "PLG_REQUEST_SOURCE_EXTERIOR" 4 "PLG_REQUEST_SOURCE_KEY_TRUNK_BUTTON" 6 "PLG_REQUEST_SOURCE_MCU_CLOSE" 1 "PLG_REQUEST_SOURCE_MCU_SWITCH" 0 "PLG_REQUEST_SOURCE_NONE" 3 "PLG_REQUEST_SOURCE_SHUTFACE" 7 "PLG_REQUEST_SOURCE_UDS" ;
VAL_ 322 VCLEFT_liftgateState 2 "PLG_STATE_BACKOFF" 5 "PLG_STATE_CLOSED" 4 "PLG_STATE_CLOSING" 11 "PLG_STATE_END_OF_TRAVEL" 0 "PLG_STATE_INIT" 7 "PLG_STATE_LATCH_CLOSING" 12 "PLG_STATE_LATCH_ENTRY" 10 "PLG_STATE_LATCH_EXIT" 6 "PLG_STATE_LATCH_OPENING" 8 "PLG_STATE_NOT_INSTALLED" 1 "PLG_STATE_OFF" 3 "PLG_STATE_OPENING" 9 "PLG_STATE_UNKNOWN" ;
VAL_ 322 VCLEFT_liftgateStoppingCondition 11 "PLG_STOPPING_CONDITION_COUNT" 10 "PLG_STOPPING_CONDITION_LATCH_FAULT" 3 "PLG_STOPPING_CONDITION_LOW_12V" 0 "PLG_STOPPING_CONDITION_NONE" 6 "PLG_STOPPING_CONDITION_OBSTACLE_CURRENT" 2 "PLG_STOPPING_CONDITION_OBSTACLE_STALL" 7 "PLG_STOPPING_CONDITION_OBSTACLE_TRAJ_POS" 8 "PLG_STOPPING_CONDITION_OBSTACLE_TRAJ_VEL" 1 "PLG_STOPPING_CONDITION_PINCH" 4 "PLG_STOPPING_CONDITION_STATE_TIMEOUT" 9 "PLG_STOPPING_CONDITION_UNCALIBRATED" 5 "PLG_STOPPING_CONDITION_VEHICLE_AT_SPEED" ;
VAL_ 322 VCLEFT_liftgateUIChimeRequest 0 "LIFTGATE_CHIME_REQUEST_NONE" 4 "LIFTGATE_CHIME_REQUEST_ONE_LONG" 1 "LIFTGATE_CHIME_REQUEST_ONE_SHORT" 3 "LIFTGATE_CHIME_REQUEST_THREE_SHORT" 2 "LIFTGATE_CHIME_REQUEST_TWO_SHORT" ;
VAL_ 325 ESP_absBrakeEvent2 2 "ABS_EVENT_ACTIVE_FRONT" 1 "ABS_EVENT_ACTIVE_FRONT_REAR" 3 "ABS_EVENT_ACTIVE_REAR" 0 "ABS_EVENT_NOT_ACTIVE" ;
VAL_ 325 ESP_absFaultLamp 0 "ABS_FAULT_LAMP_OFF" 1 "ABS_FAULT_LAMP_ON" ;
VAL_ 325 ESP_brakeApply 1 "BLS_ACTIVE" 0 "BLS_INACTIVE" ;
VAL_ 325 ESP_brakeDiscWipingActive 1 "BDW_ACTIVE" 0 "BDW_INACTIVE" ;
VAL_ 325 ESP_brakeLamp 0 "LAMP_OFF" 1 "LAMP_ON" ;
VAL_ 325 ESP_brakeTorqueTarget 8191 "SNA" ;
VAL_ 325 ESP_btcTargetState 1 "BACKUP" 0 "OFF" 2 "ON" 3 "SNA" ;
VAL_ 325 ESP_cdpStatus 2 "ACTUATING_EPB_CDP" 3 "CDP_COMMAND_INVALID" 1 "CDP_IS_AVAILABLE" 0 "CDP_IS_NOT_AVAILABLE" ;
VAL_ 325 ESP_driverBrakeApply 2 "Driver_applying_brakes" 3 "Faulty_SNA" 0 "NotInit_orOff" 1 "Not_Applied" ;
VAL_ 325 ESP_ebdFaultLamp 0 "EBD_FAULT_LAMP_OFF" 1 "EBD_FAULT_LAMP_ON" ;
VAL_ 325 ESP_ebrStandstillSkid 0 "NO_STANDSTILL_SKID" 1 "STANDSTILL_SKID_DETECTED" ;
VAL_ 325 ESP_ebrStatus 2 "ACTUATING_DI_EBR" 3 "EBR_COMMAND_INVALID" 1 "EBR_IS_AVAILABLE" 0 "EBR_IS_NOT_AVAILABLE" ;
VAL_ 325 ESP_espFaultLamp 0 "ESP_FAULT_LAMP_OFF" 1 "ESP_FAULT_LAMP_ON" ;
VAL_ 325 ESP_espLampFlash 1 "ESP_LAMP_FLASH" 0 "ESP_LAMP_OFF" ;
VAL_ 325 ESP_espModeActive 0 "ESP_MODE_00_NORMAL" 1 "ESP_MODE_01" 2 "ESP_MODE_02" 3 "ESP_MODE_03" ;
VAL_ 325 ESP_lateralAccelQF 1 "IN_SPEC" 0 "UNDEFINABLE_ACCURACY" ;
VAL_ 325 ESP_longitudinalAccelQF 1 "IN_SPEC" 0 "UNDEFINABLE_ACCURACY" ;
VAL_ 325 ESP_ptcTargetState 1 "BACKUP" 0 "FAULT" 2 "ON" 3 "SNA" ;
VAL_ 325 ESP_stabilityControlSts2 2 "ENGAGED" 3 "FAULTED" 0 "INIT" 1 "ON" ;
VAL_ 325 ESP_steeringAngleQF 1 "IN_SPEC" 0 "UNDEFINABLE_ACCURACY" ;
VAL_ 325 ESP_yawRateQF 1 "IN_SPEC" 0 "UNDEFINABLE_ACCURACY" ;
VAL_ 522 HVP_fcContNegativeState 3 "CONTACTOR_STATE_BLOCKED" 6 "CONTACTOR_STATE_ECONOMIZED" 1 "CONTACTOR_STATE_OPEN" 5 "CONTACTOR_STATE_OPENING" 2 "CONTACTOR_STATE_PRECHARGE" 4 "CONTACTOR_STATE_PULLED_IN" 0 "CONTACTOR_STATE_SNA" 7 "CONTACTOR_STATE_WELDED" ;
VAL_ 522 HVP_fcContPositiveState 3 "CONTACTOR_STATE_BLOCKED" 6 "CONTACTOR_STATE_ECONOMIZED" 1 "CONTACTOR_STATE_OPEN" 5 "CONTACTOR_STATE_OPENING" 2 "CONTACTOR_STATE_PRECHARGE" 4 "CONTACTOR_STATE_PULLED_IN" 0 "CONTACTOR_STATE_SNA" 7 "CONTACTOR_STATE_WELDED" ;
VAL_ 522 HVP_fcContactorSetState 3 "CONTACTOR_SET_STATE_BLOCKED" 5 "CONTACTOR_SET_STATE_CLOSED" 2 "CONTACTOR_SET_STATE_CLOSING" 9 "CONTACTOR_SET_STATE_NEGATIVE_CLOSED" 1 "CONTACTOR_SET_STATE_OPEN" 4 "CONTACTOR_SET_STATE_OPENING" 6 "CONTACTOR_SET_STATE_PARTIAL_WELD" 8 "CONTACTOR_SET_STATE_POSITIVE_CLOSED" 0 "CONTACTOR_SET_STATE_SNA" 7 "CONTACTOR_SET_STATE_WELDED" ;
VAL_ 522 HVP_fcCtrsRequestStatus 1 "REQUEST_ACTIVE" 2 "REQUEST_COMPLETED" 0 "REQUEST_NOT_ACTIVE" ;
VAL_ 522 HVP_fcLinkAllowedToEnergize 1 "FC_LINK_ENERGY_AC" 2 "FC_LINK_ENERGY_DC" 0 "FC_LINK_ENERGY_NONE" ;
VAL_ 522 HVP_hvilStatus 2 "CURRENT_SOURCE_FAULT" 3 "INTERNAL_OPEN_FAULT" 8 "NO_12V_SUPPLY" 5 "PENTHOUSE_LID_OPEN_FAULT" 1 "STATUS_OK" 0 "UNKNOWN" 6 "UNKNOWN_LOCATION_OPEN_FAULT" 7 "VEHICLE_NODE_FAULT" 4 "VEHICLE_OPEN_FAULT" 9 "VEHICLE_OR_PENTHOUSE_LID_OPEN_FAULT" ;
VAL_ 522 HVP_packContNegativeState 3 "CONTACTOR_STATE_BLOCKED" 6 "CONTACTOR_STATE_ECONOMIZED" 1 "CONTACTOR_STATE_OPEN" 5 "CONTACTOR_STATE_OPENING" 2 "CONTACTOR_STATE_PRECHARGE" 4 "CONTACTOR_STATE_PULLED_IN" 0 "CONTACTOR_STATE_SNA" 7 "CONTACTOR_STATE_WELDED" ;
VAL_ 522 HVP_packContPositiveState 3 "CONTACTOR_STATE_BLOCKED" 6 "CONTACTOR_STATE_ECONOMIZED" 1 "CONTACTOR_STATE_OPEN" 5 "CONTACTOR_STATE_OPENING" 2 "CONTACTOR_STATE_PRECHARGE" 4 "CONTACTOR_STATE_PULLED_IN" 0 "CONTACTOR_STATE_SNA" 7 "CONTACTOR_STATE_WELDED" ;
VAL_ 522 HVP_packContactorSetState 3 "CONTACTOR_SET_STATE_BLOCKED" 5 "CONTACTOR_SET_STATE_CLOSED" 2 "CONTACTOR_SET_STATE_CLOSING" 9 "CONTACTOR_SET_STATE_NEGATIVE_CLOSED" 1 "CONTACTOR_SET_STATE_OPEN" 4 "CONTACTOR_SET_STATE_OPENING" 6 "CONTACTOR_SET_STATE_PARTIAL_WELD" 8 "CONTACTOR_SET_STATE_POSITIVE_CLOSED" 0 "CONTACTOR_SET_STATE_SNA" 7 "CONTACTOR_SET_STATE_WELDED" ;
VAL_ 522 HVP_packCtrsRequestStatus 1 "REQUEST_ACTIVE" 2 "REQUEST_COMPLETED" 0 "REQUEST_NOT_ACTIVE" ;
VAL_ 526 PARK_sdiSensor1RawDistData 0 "BLOCKED" 1 "NEAR_DETECTION" 500 "NO_OBJECT_DETECTED" 511 "SNA" ;
VAL_ 526 PARK_sdiSensor2RawDistData 0 "BLOCKED" 1 "NEAR_DETECTION" 500 "NO_OBJECT_DETECTED" 511 "SNA" ;
VAL_ 526 PARK_sdiSensor3RawDistData 0 "BLOCKED" 1 "NEAR_DETECTION" 500 "NO_OBJECT_DETECTED" 511 "SNA" ;
VAL_ 526 PARK_sdiSensor4RawDistData 0 "BLOCKED" 1 "NEAR_DETECTION" 500 "NO_OBJECT_DETECTED" 511 "SNA" ;
VAL_ 526 PARK_sdiSensor5RawDistData 0 "BLOCKED" 1 "NEAR_DETECTION" 500 "NO_OBJECT_DETECTED" 511 "SNA" ;
VAL_ 526 PARK_sdiSensor6RawDistData 0 "BLOCKED" 1 "NEAR_DETECTION" 500 "NO_OBJECT_DETECTED" 511 "SNA" ;
VAL_ 537 VCSEC_TPMSDataIndex 0 "TPMS_DATA_SENSOR_0" 1 "TPMS_DATA_SENSOR_1" 2 "TPMS_DATA_SENSOR_2" 3 "TPMS_DATA_SENSOR_3" ;
VAL_ 537 VCSEC_TPMSBatVoltage0 255 "SNA" ;
VAL_ 537 VCSEC_TPMSBatVoltage1 255 "SNA" ;
VAL_ 537 VCSEC_TPMSBatVoltage2 255 "SNA" ;
VAL_ 537 VCSEC_TPMSBatVoltage3 255 "SNA" ;
VAL_ 537 VCSEC_TPMSLocation0 0 "LOCATION_FL" 1 "LOCATION_FR" 2 "LOCATION_RL" 3 "LOCATION_RR" 4 "LOCATION_UNKNOWN" ;
VAL_ 537 VCSEC_TPMSLocation1 0 "LOCATION_FL" 1 "LOCATION_FR" 2 "LOCATION_RL" 3 "LOCATION_RR" 4 "LOCATION_UNKNOWN" ;
VAL_ 537 VCSEC_TPMSLocation2 0 "LOCATION_FL" 1 "LOCATION_FR" 2 "LOCATION_RL" 3 "LOCATION_RR" 4 "LOCATION_UNKNOWN" ;
VAL_ 537 VCSEC_TPMSLocation3 0 "LOCATION_FL" 1 "LOCATION_FR" 2 "LOCATION_RL" 3 "LOCATION_RR" 4 "LOCATION_UNKNOWN" ;
VAL_ 537 VCSEC_TPMSPressure0 255 "SNA" ;
VAL_ 537 VCSEC_TPMSPressure1 255 "SNA" ;
VAL_ 537 VCSEC_TPMSPressure2 255 "SNA" ;
VAL_ 537 VCSEC_TPMSPressure3 255 "SNA" ;
VAL_ 537 VCSEC_TPMSTemperature0 255 "SNA" ;
VAL_ 537 VCSEC_TPMSTemperature1 255 "SNA" ;
VAL_ 537 VCSEC_TPMSTemperature2 255 "SNA" ;
VAL_ 537 VCSEC_TPMSTemperature3 255 "SNA" ;
VAL_ 516 PCS_chargeShutdownRequest 2 "EMERGENCY_SHUTDOWN_REQUESTED" 1 "GRACEFUL_SHUTDOWN_REQUESTED" 0 "NO_SHUTDOWN_REQUESTED" ;
VAL_ 516 PCS_chgMainState 9 "PCS_CHG_STATE_CLEAR_FAULTS" 6 "PCS_CHG_STATE_ENABLE" 8 "PCS_CHG_STATE_FAULTED" 1 "PCS_CHG_STATE_IDLE" 0 "PCS_CHG_STATE_INIT" 4 "PCS_CHG_STATE_QUALIFY_LINE_CONFIG" 7 "PCS_CHG_STATE_SHUTDOWN" 2 "PCS_CHG_STATE_STARTUP" 5 "PCS_CHG_STATE_SYSTEM_CONFIG" 3 "PCS_CHG_STATE_WAIT_FOR_LINE_VOLTAGE" ;
VAL_ 516 PCS_gridConfig 1 "GRID_CONFIG_SINGLE_PHASE" 0 "GRID_CONFIG_SNA" 2 "GRID_CONFIG_THREE_PHASE" 3 "GRID_CONFIG_THREE_PHASE_DELTA" ;
VAL_ 516 PCS_hvChargeStatus 1 "PCS_CHARGE_BLOCKED" 2 "PCS_CHARGE_ENABLED" 3 "PCS_CHARGE_FAULTED" 0 "PCS_CHARGE_STANDBY" ;
VAL_ 516 PCS_hwVariantType 1 "PCS_32A_SINGLE_PHASE_VARIANT" 0 "PCS_48A_SINGLE_PHASE_VARIANT" 3 "PCS_HW_VARIANT_TYPE_SNA" 2 "PCS_THREE_PHASES_VARIANT" ;
VAL_ 554 HVP_dcLinkVoltageFiltered 550 "SNA" ;
VAL_ 554 HVP_pcsControlRequest 3 "DISCHARGE" 2 "PRECHARGE" 0 "SHUTDOWN" 1 "SUPPORT" ;
VAL_ 562 BMS_fcContactorRequest 1 "SET_REQUEST_CLOSE" 4 "SET_REQUEST_CLOSE_NEGATIVE_ONLY" 5 "SET_REQUEST_CLOSE_POSITIVE_ONLY" 2 "SET_REQUEST_OPEN" 3 "SET_REQUEST_OPEN_IMMEDIATELY" 0 "SET_REQUEST_SNA" ;
VAL_ 562 BMS_fcLinkOkToEnergizeRequest 1 "FC_LINK_ENERGY_AC" 2 "FC_LINK_ENERGY_DC" 0 "FC_LINK_ENERGY_NONE" ;
VAL_ 562 BMS_internalHvilSenseV 65535 "SNA" ;
VAL_ 562 BMS_packContactorRequest 1 "SET_REQUEST_CLOSE" 4 "SET_REQUEST_CLOSE_NEGATIVE_ONLY" 5 "SET_REQUEST_CLOSE_POSITIVE_ONLY" 2 "SET_REQUEST_OPEN" 3 "SET_REQUEST_OPEN_IMMEDIATELY" 0 "SET_REQUEST_SNA" ;
VAL_ 627 UI_displayBrightnessLevel 255 "SNA" ;
VAL_ 627 UI_domeLightSwitch 2 "DOME_LIGHT_SWITCH_AUTO" 0 "DOME_LIGHT_SWITCH_OFF" 1 "DOME_LIGHT_SWITCH_ON" ;
VAL_ 627 UI_driveStateRequest 0 "DRIVE_STATE_REQ_IDLE" 1 "DRIVE_STATE_REQ_START" ;
VAL_ 627 UI_frontLeftSeatHeatReq 1 "HEATER_REQUEST_LEVEL1" 2 "HEATER_REQUEST_LEVEL2" 3 "HEATER_REQUEST_LEVEL3" 0 "HEATER_REQUEST_OFF" ;
VAL_ 627 UI_frontRightSeatHeatReq 1 "HEATER_REQUEST_LEVEL1" 2 "HEATER_REQUEST_LEVEL2" 3 "HEATER_REQUEST_LEVEL3" 0 "HEATER_REQUEST_OFF" ;
VAL_ 627 UI_lockRequest 0 "UI_LOCK_REQUEST_IDLE" 1 "UI_LOCK_REQUEST_LOCK" 4 "UI_LOCK_REQUEST_REMOTE_LOCK" 3 "UI_LOCK_REQUEST_REMOTE_UNLOCK" 7 "UI_LOCK_REQUEST_SNA" 2 "UI_LOCK_REQUEST_UNLOCK" ;
VAL_ 627 UI_mirrorFoldRequest 0 "MIRROR_FOLD_REQUEST_IDLE" 2 "MIRROR_FOLD_REQUEST_PRESENT" 1 "MIRROR_FOLD_REQUEST_RETRACT" 3 "MIRROR_FOLD_REQUEST_SNA" ;
VAL_ 627 UI_rearCenterSeatHeatReq 1 "HEATER_REQUEST_LEVEL1" 2 "HEATER_REQUEST_LEVEL2" 3 "HEATER_REQUEST_LEVEL3" 0 "HEATER_REQUEST_OFF" ;
VAL_ 627 UI_rearLeftSeatHeatReq 1 "HEATER_REQUEST_LEVEL1" 2 "HEATER_REQUEST_LEVEL2" 3 "HEATER_REQUEST_LEVEL3" 0 "HEATER_REQUEST_OFF" ;
VAL_ 627 UI_rearRightSeatHeatReq 1 "HEATER_REQUEST_LEVEL1" 2 "HEATER_REQUEST_LEVEL2" 3 "HEATER_REQUEST_LEVEL3" 0 "HEATER_REQUEST_OFF" ;
VAL_ 627 UI_remoteClosureRequest 2 "UI_REMOTE_CLOSURE_REQUEST_FRONT_TRUNK_MOVE" 0 "UI_REMOTE_CLOSURE_REQUEST_IDLE" 1 "UI_REMOTE_CLOSURE_REQUEST_REAR_TRUNK_MOVE" 3 "UI_REMOTE_CLOSURE_REQUEST_SNA" ;
VAL_ 627 UI_remoteStartRequest 0 "UI_REMOTE_START_REQUEST_IDLE" 4 "UI_REMOTE_START_REQUEST_SNA" 1 "UI_REMOTE_START_REQUEST_START" ;
VAL_ 627 UI_steeringBacklightEnabled 0 "STEERING_BACKLIGHT_DISABLED" 1 "STEERING_BACKLIGHT_ENABLED" ;
VAL_ 627 UI_steeringButtonMode 4 "STEERING_BUTTON_MODE_HEADLIGHT_LEFT" 5 "STEERING_BUTTON_MODE_HEADLIGHT_RIGHT" 2 "STEERING_BUTTON_MODE_MIRROR_LEFT" 3 "STEERING_BUTTON_MODE_MIRROR_RIGHT" 0 "STEERING_BUTTON_MODE_OFF" 1 "STEERING_BUTTON_MODE_STEERING_COLUMN_ADJ" ;
VAL_ 627 UI_wiperMode 2 "WIPER_MODE_NORMAL" 3 "WIPER_MODE_PARK" 1 "WIPER_MODE_SERVICE" 0 "WIPER_MODE_SNA" ;
VAL_ 627 UI_wiperRequest 2 "WIPER_REQUEST_AUTO" 6 "WIPER_REQUEST_FAST_CONTINUOUS" 4 "WIPER_REQUEST_FAST_INTERMITTENT" 1 "WIPER_REQUEST_OFF" 5 "WIPER_REQUEST_SLOW_CONTINUOUS" 3 "WIPER_REQUEST_SLOW_INTERMITTENT" 0 "WIPER_REQUEST_SNA" ;
VAL_ 1066 VCSEC_TPMSConnectionTypeCurrent0 0 "CONNECTIONTYPE_FAST" 1 "CONNECTIONTYPE_SLOW" 2 "CONNECTIONTYPE_UNKNOWN" ;
VAL_ 1066 VCSEC_TPMSConnectionTypeCurrent1 0 "CONNECTIONTYPE_FAST" 1 "CONNECTIONTYPE_SLOW" 2 "CONNECTIONTYPE_UNKNOWN" ;
VAL_ 1066 VCSEC_TPMSConnectionTypeCurrent2 0 "CONNECTIONTYPE_FAST" 1 "CONNECTIONTYPE_SLOW" 2 "CONNECTIONTYPE_UNKNOWN" ;
VAL_ 1066 VCSEC_TPMSConnectionTypeCurrent3 0 "CONNECTIONTYPE_FAST" 1 "CONNECTIONTYPE_SLOW" 2 "CONNECTIONTYPE_UNKNOWN" ;
VAL_ 1066 VCSEC_TPMSConnectionTypeDesired0 0 "CONNECTIONTYPE_FAST" 1 "CONNECTIONTYPE_SLOW" 2 "CONNECTIONTYPE_UNKNOWN" ;
VAL_ 1066 VCSEC_TPMSConnectionTypeDesired1 0 "CONNECTIONTYPE_FAST" 1 "CONNECTIONTYPE_SLOW" 2 "CONNECTIONTYPE_UNKNOWN" ;
VAL_ 1066 VCSEC_TPMSConnectionTypeDesired2 0 "CONNECTIONTYPE_FAST" 1 "CONNECTIONTYPE_SLOW" 2 "CONNECTIONTYPE_UNKNOWN" ;
VAL_ 1066 VCSEC_TPMSConnectionTypeDesired3 0 "CONNECTIONTYPE_FAST" 1 "CONNECTIONTYPE_SLOW" 2 "CONNECTIONTYPE_UNKNOWN" ;
VAL_ 1066 VCSEC_TPMSSensorState0 3 "SENSOR_CONNECTED" 4 "SENSOR_DISCONNECTING" 0 "SENSOR_NOT_PAIRED" 1 "SENSOR_WAIT_FOR_ADV" 2 "SENSOR_WAIT_FOR_CONN" ;
VAL_ 1066 VCSEC_TPMSSensorState1 3 "SENSOR_CONNECTED" 4 "SENSOR_DISCONNECTING" 0 "SENSOR_NOT_PAIRED" 1 "SENSOR_WAIT_FOR_ADV" 2 "SENSOR_WAIT_FOR_CONN" ;
VAL_ 1066 VCSEC_TPMSSensorState2 3 "SENSOR_CONNECTED" 4 "SENSOR_DISCONNECTING" 0 "SENSOR_NOT_PAIRED" 1 "SENSOR_WAIT_FOR_ADV" 2 "SENSOR_WAIT_FOR_CONN" ;
VAL_ 1066 VCSEC_TPMSSensorState3 3 "SENSOR_CONNECTED" 4 "SENSOR_DISCONNECTING" 0 "SENSOR_NOT_PAIRED" 1 "SENSOR_WAIT_FOR_ADV" 2 "SENSOR_WAIT_FOR_CONN" ;
VAL_ 558 PARK_sdiSensor10RawDistData 0 "BLOCKED" 1 "NEAR_DETECTION" 500 "NO_OBJECT_DETECTED" 511 "SNA" ;
VAL_ 558 PARK_sdiSensor11RawDistData 0 "BLOCKED" 1 "NEAR_DETECTION" 500 "NO_OBJECT_DETECTED" 511 "SNA" ;
VAL_ 558 PARK_sdiSensor12RawDistData 0 "BLOCKED" 1 "NEAR_DETECTION" 500 "NO_OBJECT_DETECTED" 511 "SNA" ;
VAL_ 558 PARK_sdiSensor7RawDistData 0 "BLOCKED" 1 "NEAR_DETECTION" 500 "NO_OBJECT_DETECTED" 511 "SNA" ;
VAL_ 558 PARK_sdiSensor8RawDistData 0 "BLOCKED" 1 "NEAR_DETECTION" 500 "NO_OBJECT_DETECTED" 511 "SNA" ;
VAL_ 558 PARK_sdiSensor9RawDistData 0 "BLOCKED" 1 "NEAR_DETECTION" 500 "NO_OBJECT_DETECTED" 511 "SNA" ;
VAL_ 568 UI_countryCode 1023 "SNA" 0 "UNKNOWN" ;
VAL_ 568 UI_mapSpeedLimit 3 "LESS_OR_EQ_10" 21 "LESS_OR_EQ_100" 22 "LESS_OR_EQ_105" 23 "LESS_OR_EQ_110" 24 "LESS_OR_EQ_115" 25 "LESS_OR_EQ_120" 26 "LESS_OR_EQ_130" 27 "LESS_OR_EQ_140" 4 "LESS_OR_EQ_15" 28 "LESS_OR_EQ_150" 29 "LESS_OR_EQ_160" 5 "LESS_OR_EQ_20" 6 "LESS_OR_EQ_25" 7 "LESS_OR_EQ_30" 8 "LESS_OR_EQ_35" 9 "LESS_OR_EQ_40" 10 "LESS_OR_EQ_45" 1 "LESS_OR_EQ_5" 11 "LESS_OR_EQ_50" 12 "LESS_OR_EQ_55" 13 "LESS_OR_EQ_60" 14 "LESS_OR_EQ_65" 2 "LESS_OR_EQ_7" 15 "LESS_OR_EQ_70" 16 "LESS_OR_EQ_75" 17 "LESS_OR_EQ_80" 18 "LESS_OR_EQ_85" 19 "LESS_OR_EQ_90" 20 "LESS_OR_EQ_95" 31 "SNA" 0 "UNKNOWN" 30 "UNLIMITED" ;
VAL_ 568 UI_mapSpeedLimitDependency 6 "LANE" 0 "NONE" 2 "RAIN" 1 "SCHOOL" 5 "SEASON" 7 "SNA" 3 "SNOW" 4 "TIME" ;
VAL_ 568 UI_mapSpeedLimitType 2 "ADVISORY" 4 "BUMPS" 3 "DEPENDENT" 1 "REGULAR" 7 "UNKNOWN_SNA" ;
VAL_ 568 UI_mapSpeedUnits 1 "KPH" 0 "MPH" ;
VAL_ 568 UI_nextBranchDist 31 "SNA" ;
VAL_ 568 UI_roadClass 1 "CLASS_1_MAJOR" 2 "CLASS_2" 3 "CLASS_3" 4 "CLASS_4" 5 "CLASS_5" 6 "CLASS_6_MINOR" 0 "UNKNOWN_INVALID_SNA" ;
VAL_ 569 DAS_leftFork 1 "LEFT_FORK_AVAILABLE" 0 "LEFT_FORK_NONE" 2 "LEFT_FORK_SELECTED" 3 "LEFT_FORK_UNAVAILABLE" ;
VAL_ 569 DAS_leftLineUsage 1 "AVAILABLE" 3 "BLACKLISTED" 2 "FUSED" 0 "REJECTED_UNAVAILABLE" ;
VAL_ 569 DAS_rightFork 1 "RIGHT_FORK_AVAILABLE" 0 "RIGHT_FORK_NONE" 2 "RIGHT_FORK_SELECTED" 3 "RIGHT_FORK_UNAVAILABLE" ;
VAL_ 569 DAS_rightLineUsage 1 "AVAILABLE" 3 "BLACKLISTED" 2 "FUSED" 0 "REJECTED_UNAVAILABLE" ;
VAL_ 586 DAS_accSmartSpeedState 2 "ACTIVE_INTEGRATING" 1 "ACTIVE_OFFRAMP" 3 "ACTIVE_ONRAMP" 0 "NOT_ACTIVE" 5 "OFFRAMP_DELAY" 4 "SET_SPEED_SET_REQUESTED" 7 "SNA" ;
VAL_ 586 DAS_autosteerBottsDotsUsage 1 "AVAILABLE" 3 "BLACKLISTED" 2 "FUSED" 0 "REJECTED_UNAVAILABLE" ;
VAL_ 586 DAS_autosteerHPPUsage 1 "AVAILABLE" 3 "BLACKLISTED" 2 "FUSED" 0 "REJECTED_UNAVAILABLE" ;
VAL_ 586 DAS_autosteerHealthState 4 "HEALTH_ABORTING" 2 "HEALTH_DEGRADED" 5 "HEALTH_FAULT" 1 "HEALTH_NOMINAL" 3 "HEALTH_SEVERELY_DEGRADED" 0 "HEALTH_UNAVAILABLE" ;
VAL_ 586 DAS_autosteerModelUsage 1 "AVAILABLE" 3 "BLACKLISTED" 2 "FUSED" 0 "REJECTED_UNAVAILABLE" ;
VAL_ 586 DAS_autosteerNavigationUsage 1 "AVAILABLE" 3 "BLACKLISTED" 2 "FUSED" 0 "REJECTED_UNAVAILABLE" ;
VAL_ 586 DAS_autosteerVehiclesUsage 1 "AVAILABLE" 3 "BLACKLISTED" 2 "FUSED" 0 "REJECTED_UNAVAILABLE" ;
VAL_ 586 DAS_behaviorType 0 "DAS_BEHAVIOR_INVALID" 1 "DAS_BEHAVIOR_IN_LANE" 2 "DAS_BEHAVIOR_LANE_CHANGE_LEFT" 3 "DAS_BEHAVIOR_LANE_CHANGE_RIGHT" ;
VAL_ 586 DAS_lastAutosteerAbortReason 29 "UI_ABORT_REASON_ACC_CANCEL" 32 "UI_ABORT_REASON_AEB" 14 "UI_ABORT_REASON_APP_ME_STATE_NOT_VISION" 30 "UI_ABORT_REASON_CAMERA_FAILSAFES" 16 "UI_ABORT_REASON_CAM_MSG_MIA" 17 "UI_ABORT_REASON_CAM_WATCHDOG" 23 "UI_ABORT_REASON_CID_SWITCH_DISABLED" 21 "UI_ABORT_REASON_COMPONENT_MIA" 22 "UI_ABORT_REASON_CRUISE_FAULT" 24 "UI_ABORT_REASON_DRIVING_OFF_NAV" 20 "UI_ABORT_REASON_EPAS_EAC_DENIED" 28 "UI_ABORT_REASON_EPAS_ERROR_CODE" 26 "UI_ABORT_REASON_FOLLOWER_OUTPUT_INVALID" 0 "UI_ABORT_REASON_HM_LANE_VIEW_RANGE" 2 "UI_ABORT_REASON_HM_STEERING_ERROR" 1 "UI_ABORT_REASON_HM_VIRTUAL_LANE_NO_INPUTS" 15 "UI_ABORT_REASON_ME_MAIN_STATE_NOT_VISION" 31 "UI_ABORT_REASON_NO_ABORT" 27 "UI_ABORT_REASON_PLANNER_OUTPUT_INVALID" 33 "UI_ABORT_REASON_SEATBELT_UNBUCKLED" 19 "UI_ABORT_REASON_SIDE_COLLISION_IMMINENT" 18 "UI_ABORT_REASON_TRAILER_MODE" 34 "UI_ABORT_REASON_USER_OVERRIDE_STRIKEOUT" 25 "UI_ABORT_REASON_VEHICLE_SPEED_ABOVE_MAX" ;
VAL_ 586 DAS_lastLinePreferenceReason 1 "AGREEMENT_WITH_NEIGHBOR_LANES" 4 "AVOID_ONCOMING_LANES" 5 "COUNTRY_DRIVING_SIDE" 3 "NAVIGATION_BRANCH" 2 "NEIGHBOR_LANE_PROBABILIY" 15 "NONE" 0 "OTHER_LANE_DISAGREES_WITH_MODEL" ;
VAL_ 586 DAS_navAvailable 1 "DAS_NAV_AVAILABLE" 0 "DAS_NAV_UNAVAILABLE" ;
VAL_ 586 DAS_offsetSide 0 "NO_OFFSET" 3 "OFFSET_BOTH_OBJECTS" 2 "OFFSET_LEFT_OBJECT" 1 "OFFSET_RIGHT_OBJECT" ;
VAL_ 586 DAS_plannerState 0 "TP_EXTSTATE_DISABLED" 2 "TP_EXTSTATE_FOLLOW" 7 "TP_EXTSTATE_LANECHANGE_ABORT" 4 "TP_EXTSTATE_LANECHANGE_IN_PROGRESS" 3 "TP_EXTSTATE_LANECHANGE_REQUESTED" 6 "TP_EXTSTATE_LANECHANGE_WAIT_FOR_FWD_OBSTACLE" 5 "TP_EXTSTATE_LANECHANGE_WAIT_FOR_SIDE_OBSTACLE" 1 "TP_EXTSTATE_VL" ;
VAL_ 586 DAS_rearLeftVehDetectedCurrent 1 "VEHICLE_DETECTED" 0 "VEHICLE_NOT_DETECTED" ;
VAL_ 586 DAS_rearLeftVehDetectedTrip 1 "VEHICLE_DETECTED" 0 "VEHICLE_NOT_DETECTED" ;
VAL_ 586 DAS_rearRightVehDetectedTrip 1 "VEHICLE_DETECTED" 0 "VEHICLE_NOT_DETECTED" ;
VAL_ 586 DAS_rearVehDetectedThisCycle 1 "VEHICLE_DETECTED" 0 "VEHICLE_NOT_DETECTED" ;
VAL_ 586 DAS_roadSurfaceType 2 "ROAD_SURFACE_ENHANCED" 1 "ROAD_SURFACE_NORMAL" 0 "ROAD_SURFACE_SNA" ;
VAL_ 586 DAS_ulcInProgress 1 "ULC_ACTIVE" 0 "ULC_INACTIVE" ;
VAL_ 586 DAS_ulcType 1 "ULC_TYPE_NAV" 0 "ULC_TYPE_NONE" 2 "ULC_TYPE_SPEED" ;
VAL_ 605 CP_UHF_controlState 3 "CP_UHF_CALIBRATE" 6 "CP_UHF_CHECK_RX" 1 "CP_UHF_CONFIG" 10 "CP_UHF_FAULT" 8 "CP_UHF_HANDLE_FOUND" 2 "CP_UHF_IDLE" 0 "CP_UHF_INIT" 4 "CP_UHF_PREPARE_RX" 7 "CP_UHF_READ_RXFIFO" 5 "CP_UHF_RX" 9 "CP_UHF_SLEEP" ;
VAL_ 605 CP_chargeCablePresent 0 "CABLE_NOT_PRESENT" 1 "CABLE_PRESENT" ;
VAL_ 605 CP_chargeCableState 2 "CHARGE_CABLE_CONNECTED" 1 "CHARGE_CABLE_NOT_CONNECTED" 0 "CHARGE_CABLE_UNKNOWN_SNA" ;
VAL_ 605 CP_coldWeatherMode 1 "CP_COLD_WEATHER_LATCH_MITIGATION" 0 "CP_COLD_WEATHER_NONE" ;
VAL_ 605 CP_doorControlState 5 "CP_doorClosing" 1 "CP_doorIdle" 0 "CP_doorInit" 2 "CP_doorOpenRequested" 3 "CP_doorOpening" 6 "CP_doorSenseClosed" 4 "CP_doorSenseOpen" ;
VAL_ 605 CP_faultLineSensed 0 "FAULT_LINE_CLEARED" 1 "FAULT_LINE_SET" ;
VAL_ 605 CP_inductiveDoorState 7 "CP_INDUCTIVE_DOOR_FAULT" 0 "CP_INDUCTIVE_DOOR_INIT" 1 "CP_INDUCTIVE_DOOR_INIT_FROM_CHARGE" 2 "CP_INDUCTIVE_DOOR_INIT_FROM_DRIVE" 4 "CP_INDUCTIVE_DOOR_NOT_PRESENT" 6 "CP_INDUCTIVE_DOOR_OFF_CHARGE" 5 "CP_INDUCTIVE_DOOR_OFF_DRIVE" 3 "CP_INDUCTIVE_DOOR_PRESENT" ;
VAL_ 605 CP_inductiveSensorState 7 "CP_INDUCTIVE_SENSOR_CONFIG" 5 "CP_INDUCTIVE_SENSOR_FAULT" 0 "CP_INDUCTIVE_SENSOR_INIT" 3 "CP_INDUCTIVE_SENSOR_PAUSE" 1 "CP_INDUCTIVE_SENSOR_POLL" 6 "CP_INDUCTIVE_SENSOR_RESET" 2 "CP_INDUCTIVE_SENSOR_SHUTDOWN" 4 "CP_INDUCTIVE_SENSOR_WAIT_FOR_INIT" ;
VAL_ 605 CP_latch2ControlState 2 "CP_latchDisengageRequested" 4 "CP_latchDisengaged" 3 "CP_latchDisengaging" 5 "CP_latchEngaging" 1 "CP_latchIdle" 0 "CP_latchInit" ;
VAL_ 605 CP_latch2State 3 "CP_LATCH_BLOCKING" 1 "CP_LATCH_DISENGAGED" 2 "CP_LATCH_ENGAGED" 0 "CP_LATCH_SNA" ;
VAL_ 605 CP_latchControlState 2 "CP_latchDisengageRequested" 4 "CP_latchDisengaged" 3 "CP_latchDisengaging" 5 "CP_latchEngaging" 1 "CP_latchIdle" 0 "CP_latchInit" ;
VAL_ 605 CP_latchState 3 "CP_LATCH_BLOCKING" 1 "CP_LATCH_DISENGAGED" 2 "CP_LATCH_ENGAGED" 0 "CP_LATCH_SNA" ;
VAL_ 605 CP_ledColor 7 "CP_LEDS_AMBER" 3 "CP_LEDS_BLUE" 9 "CP_LEDS_DEBUG" 6 "CP_LEDS_FLASHING_AMBER" 10 "CP_LEDS_FLASHING_BLUE" 5 "CP_LEDS_FLASHING_GREEN" 2 "CP_LEDS_GREEN" 0 "CP_LEDS_OFF" 8 "CP_LEDS_RAVE" 1 "CP_LEDS_RED" 4 "CP_LEDS_WHITE" ;
VAL_ 605 CP_type 1 "CP_TYPE_EURO_IEC" 2 "CP_TYPE_GB" 3 "CP_TYPE_IEC_CCS" 0 "CP_TYPE_US_TESLA" ;
VAL_ 697 DAS_accState 1 "ACC_CANCEL_CAMERA_BLIND" 0 "ACC_CANCEL_GENERIC" 13 "ACC_CANCEL_GENERIC_SILENT" 14 "ACC_CANCEL_OUT_OF_CALIBRATION" 12 "ACC_CANCEL_PATH_NOT_CLEAR" 2 "ACC_CANCEL_RADAR_BLIND" 3 "ACC_HOLD" 4 "ACC_ON" 8 "APC_ABORT" 5 "APC_BACKWARD" 7 "APC_COMPLETE" 6 "APC_FORWARD" 9 "APC_PAUSE" 11 "APC_SELFPARK_START" 10 "APC_UNPARK_COMPLETE" 15 "FAULT_SNA" ;
VAL_ 697 DAS_accelMax 511 "SNA" ;
VAL_ 697 DAS_accelMin 511 "SNA" ;
VAL_ 697 DAS_aebEvent 1 "AEB_ACTIVE" 2 "AEB_FAULT" 0 "AEB_NOT_ACTIVE" 3 "AEB_SNA" ;
VAL_ 697 DAS_jerkMax 255 "SNA" ;
VAL_ 697 DAS_jerkMin 511 "SNA" ;
VAL_ 697 DAS_setSpeed 4095 "SNA" ;
VAL_ 723 UI_isSunUp 0 "SUN_DOWN" 3 "SUN_SNA" 1 "SUN_UP" ;
VAL_ 723 UI_solarAzimuthAngle 32768 "SNA" ;
VAL_ 723 UI_solarAzimuthAngleCarRef 255 "SNA" ;
VAL_ 723 UI_solarElevationAngle 127 "SNA" ;
VAL_ 777 DAS_objectId 3 "CUTIN_VEHICLE" 0 "LEAD_VEHICLES" 1 "LEFT_VEHICLES" 2 "RIGHT_VEHICLES" 4 "ROAD_SIGN" 5 "VEHICLE_HEADINGS" ;
VAL_ 777 DAS_cutinVehDx 255 "SNA" ;
VAL_ 777 DAS_cutinVehHeading 255 "SNA" ;
VAL_ 777 DAS_cutinVehId 127 "SNA" ;
VAL_ 777 DAS_cutinVehType 4 "BICYCLE" 2 "CAR" 3 "MOTORCYCLE" 5 "PEDESTRIAN" 1 "TRUCK" 0 "UNKNOWN" ;
VAL_ 777 DAS_cutinVehVxRel 15 "SNA" ;
VAL_ 777 DAS_leadVeh2Dx 255 "SNA" ;
VAL_ 777 DAS_leadVeh2Heading 255 "SNA" ;
VAL_ 777 DAS_leadVeh2Id 0 "SNA" ;
VAL_ 777 DAS_leadVeh2Type 4 "BICYCLE" 2 "CAR" 3 "MOTORCYCLE" 5 "PEDESTRIAN" 1 "TRUCK" 0 "UNKNOWN" ;
VAL_ 777 DAS_leadVeh2VxRel 15 "SNA" ;
VAL_ 777 DAS_leadVehDx 255 "SNA" ;
VAL_ 777 DAS_leadVehHeading 255 "SNA" ;
VAL_ 777 DAS_leadVehId 127 "SNA" ;
VAL_ 777 DAS_leadVehType 4 "BICYCLE" 2 "CAR" 6 "IPSO" 3 "MOTORCYCLE" 5 "PEDESTRIAN" 1 "TRUCK" 0 "UNKNOWN" ;
VAL_ 777 DAS_leadVehVxRel 15 "SNA" ;
VAL_ 777 DAS_leftVeh2Dx 255 "SNA" ;
VAL_ 777 DAS_leftVeh2Heading 255 "SNA" ;
VAL_ 777 DAS_leftVeh2Id 0 "SNA" ;
VAL_ 777 DAS_leftVeh2Type 4 "BICYCLE" 2 "CAR" 3 "MOTORCYCLE" 5 "PEDESTRIAN" 1 "TRUCK" 0 "UNKNOWN" ;
VAL_ 777 DAS_leftVeh2VxRel 15 "SNA" ;
VAL_ 777 DAS_leftVehDx 255 "SNA" ;
VAL_ 777 DAS_leftVehHeading 255 "SNA" ;
VAL_ 777 DAS_leftVehId 127 "SNA" ;
VAL_ 777 DAS_leftVehType 4 "BICYCLE" 2 "CAR" 3 "MOTORCYCLE" 5 "PEDESTRIAN" 1 "TRUCK" 0 "UNKNOWN" ;
VAL_ 777 DAS_leftVehVxRel 15 "SNA" ;
VAL_ 777 DAS_rightVeh2Dx 255 "SNA" ;
VAL_ 777 DAS_rightVeh2Heading 255 "SNA" ;
VAL_ 777 DAS_rightVeh2Id 0 "SNA" ;
VAL_ 777 DAS_rightVeh2Type 4 "BICYCLE" 2 "CAR" 3 "MOTORCYCLE" 5 "PEDESTRIAN" 1 "TRUCK" 0 "UNKNOWN" ;
VAL_ 777 DAS_rightVeh2VxRel 15 "SNA" ;
VAL_ 777 DAS_rightVehDx 255 "SNA" ;
VAL_ 777 DAS_rightVehHeading 255 "SNA" ;
VAL_ 777 DAS_rightVehId 127 "SNA" ;
VAL_ 777 DAS_rightVehType 4 "BICYCLE" 2 "CAR" 3 "MOTORCYCLE" 5 "PEDESTRIAN" 1 "TRUCK" 0 "UNKNOWN" ;
VAL_ 777 DAS_rightVehVxRel 15 "SNA" ;
VAL_ 777 DAS_roadSignArrow 0 "CIRCLE" 1 "LEFT" 2 "RIGHT" 3 "STRAIGHT" 4 "UNKNOWN" ;
VAL_ 777 DAS_roadSignColor 3 "GREEN" 0 "NONE" 1 "RED" 4 "RED_YELLOW" 2 "YELLOW" ;
VAL_ 777 DAS_roadSignId 255 "SNA" 0 "STOP_SIGN" 1 "TRAFFIC_LIGHT" ;
VAL_ 777 DAS_roadSignOrientation 2 "HORIZONTAL_3_LIGHT" 0 "UNKNOWN" 1 "VERTICAL_3_LIGHT" ;
VAL_ 777 DAS_roadSignSource 1 "NAV" 0 "NONE" 2 "VISION" ;
VAL_ 777 DAS_roadSignStopLineDist 1023 "SNA" ;
VAL_ 905 DAS_ACC_report 24 "ACC_REPORT_BEHAVIOR_REPORT" 23 "ACC_REPORT_CAMERA_ONLY" 21 "ACC_REPORT_CIPV_CUTTING_OUT" 10 "ACC_REPORT_CSA" 18 "ACC_REPORT_FLEET_SPEEDS" 13 "ACC_REPORT_LC_EXTERNAL_STATE_ABORTED" 12 "ACC_REPORT_LC_EXTERNAL_STATE_ABORTING" 14 "ACC_REPORT_LC_EXTERNAL_STATE_ACTIVE_RESTRICTED" 11 "ACC_REPORT_LC_HANDS_ON_REQD_STRUCK_OUT" 19 "ACC_REPORT_MCVLR_DPP" 20 "ACC_REPORT_MCVLR_IN_PATH" 22 "ACC_REPORT_RADAR_OBJ_FIVE" 15 "ACC_REPORT_RADAR_OBJ_ONE" 16 "ACC_REPORT_RADAR_OBJ_TWO" 1 "ACC_REPORT_TARGET_CIPV" 5 "ACC_REPORT_TARGET_CUTIN" 2 "ACC_REPORT_TARGET_IN_FRONT_OF_CIPV" 17 "ACC_REPORT_TARGET_MCP" 3 "ACC_REPORT_TARGET_MCVL" 4 "ACC_REPORT_TARGET_MCVR" 0 "ACC_REPORT_TARGET_NONE" 9 "ACC_REPORT_TARGET_TYPE_FAULT" 8 "ACC_REPORT_TARGET_TYPE_IPSO" 6 "ACC_REPORT_TARGET_TYPE_STOP_SIGN" 7 "ACC_REPORT_TARGET_TYPE_TRAFFIC_LIGHT" ;
VAL_ 905 DAS_accSpeedLimit 0 "NONE" 1023 "SNA" ;
VAL_ 905 DAS_activationFailureStatus 1 "LC_ACTIVATION_FAILED_1" 2 "LC_ACTIVATION_FAILED_2" 0 "LC_ACTIVATION_IDLE" ;
VAL_ 905 DAS_csaState 1 "CSA_EXTERNAL_STATE_AVAILABLE" 2 "CSA_EXTERNAL_STATE_ENABLE" 3 "CSA_EXTERNAL_STATE_HOLD" 0 "CSA_EXTERNAL_STATE_UNAVAILABLE" ;
VAL_ 905 DAS_driverInteractionLevel 2 "CONTINUED_DRIVER_NOT_INTERACTING" 0 "DRIVER_INTERACTING" 1 "DRIVER_NOT_INTERACTING" ;
VAL_ 905 DAS_longCollisionWarning 3 "FCM_LONG_COLLISION_WARNING_IPSO" 0 "FCM_LONG_COLLISION_WARNING_NONE" 2 "FCM_LONG_COLLISION_WARNING_PEDESTRIAN" 15 "FCM_LONG_COLLISION_WARNING_SNA" 4 "FCM_LONG_COLLISION_WARNING_STOPSIGN_STOPLINE" 5 "FCM_LONG_COLLISION_WARNING_TFL_STOPLINE" 6 "FCM_LONG_COLLISION_WARNING_VEHICLE_CIPV" 12 "FCM_LONG_COLLISION_WARNING_VEHICLE_CIPV2" 7 "FCM_LONG_COLLISION_WARNING_VEHICLE_CUTIN" 8 "FCM_LONG_COLLISION_WARNING_VEHICLE_MCVL" 9 "FCM_LONG_COLLISION_WARNING_VEHICLE_MCVL2" 10 "FCM_LONG_COLLISION_WARNING_VEHICLE_MCVR" 11 "FCM_LONG_COLLISION_WARNING_VEHICLE_MCVR2" 1 "FCM_LONG_COLLISION_WARNING_VEHICLE_UNKNOWN" ;
VAL_ 905 DAS_pmmCameraFaultReason 1 "PMM_CAMERA_BLOCKED_FRONT" 2 "PMM_CAMERA_INVALID_MIA" 0 "PMM_CAMERA_NO_FAULT" ;
VAL_ 905 DAS_pmmLoggingRequest 0 "FALSE" 1 "TRUE" ;
VAL_ 905 DAS_pmmObstacleSeverity 6 "PMM_ACCEL_LIMIT" 3 "PMM_BRAKE_REQUEST" 5 "PMM_CRASH_FRONT" 4 "PMM_CRASH_REAR" 2 "PMM_IMMINENT_FRONT" 1 "PMM_IMMINENT_REAR" 0 "PMM_NONE" 7 "PMM_SNA" ;
VAL_ 905 DAS_pmmRadarFaultReason 1 "PMM_RADAR_BLOCKED_FRONT" 2 "PMM_RADAR_INVALID_MIA" 0 "PMM_RADAR_NO_FAULT" ;
VAL_ 905 DAS_pmmSysFaultReason 7 "PMM_FAULT_BRAKE_PEDAL_INHIBIT" 1 "PMM_FAULT_DAS_DISABLED" 5 "PMM_FAULT_DISABLED_BY_USER" 3 "PMM_FAULT_DI_FAULT" 0 "PMM_FAULT_NONE" 6 "PMM_FAULT_ROAD_TYPE" 2 "PMM_FAULT_SPEED" 4 "PMM_FAULT_STEERING_ANGLE_RATE" ;
VAL_ 905 DAS_pmmUltrasonicsFaultReason 3 "PMM_ULTRASONICS_BLOCKED_BOTH" 1 "PMM_ULTRASONICS_BLOCKED_FRONT" 2 "PMM_ULTRASONICS_BLOCKED_REAR" 4 "PMM_ULTRASONICS_INVALID_MIA" 0 "PMM_ULTRASONICS_NO_FAULT" ;
VAL_ 905 DAS_ppOffsetDesiredRamp 128 "PP_NO_OFFSET" ;
VAL_ 905 DAS_radarTelemetry 0 "RADAR_TELEMETRY_IDLE" 1 "RADAR_TELEMETRY_NORMAL" 2 "RADAR_TELEMETRY_URGENT" ;
VAL_ 905 DAS_robState 2 "ROB_STATE_ACTIVE" 0 "ROB_STATE_INHIBITED" 3 "ROB_STATE_MAPLESS" 1 "ROB_STATE_MEASURE" ;
VAL_ 921 DAS_autoLaneChangeState 19 "ALC_ABORT_BLINKER_TURNED_OFF" 18 "ALC_ABORT_LC_HEALTH_BAD" 30 "ALC_ABORT_MISSION_PLAN_INVALID" 20 "ALC_ABORT_OTHER_REASON" 17 "ALC_ABORT_POOR_VIEW_RANGE" 15 "ALC_ABORT_SIDE_OBSTACLE_PRESENT_L" 16 "ALC_ABORT_SIDE_OBSTACLE_PRESENT_R" 29 "ALC_ABORT_TIMEOUT" 8 "ALC_AVAILABLE_BOTH" 6 "ALC_AVAILABLE_ONLY_L" 7 "ALC_AVAILABLE_ONLY_R" 26 "ALC_BLOCKED_LANE_TYPE_L" 27 "ALC_BLOCKED_LANE_TYPE_R" 23 "ALC_BLOCKED_VEH_TTC_AND_USS_L" 25 "ALC_BLOCKED_VEH_TTC_AND_USS_R" 22 "ALC_BLOCKED_VEH_TTC_L" 24 "ALC_BLOCKED_VEH_TTC_R" 9 "ALC_IN_PROGRESS_L" 10 "ALC_IN_PROGRESS_R" 31 "ALC_SNA" 0 "ALC_UNAVAILABLE_DISABLED" 4 "ALC_UNAVAILABLE_EXITING_HIGHWAY" 1 "ALC_UNAVAILABLE_NO_LANES" 21 "ALC_UNAVAILABLE_SOLID_LANE_LINE" 2 "ALC_UNAVAILABLE_SONICS_INVALID" 3 "ALC_UNAVAILABLE_TP_FOLLOW" 5 "ALC_UNAVAILABLE_VEHICLE_SPEED" 13 "ALC_WAITING_FOR_FWD_OBST_TO_PASS_L" 14 "ALC_WAITING_FOR_FWD_OBST_TO_PASS_R" 11 "ALC_WAITING_FOR_SIDE_OBST_TO_PASS_L" 12 "ALC_WAITING_FOR_SIDE_OBST_TO_PASS_R" 28 "ALC_WAITING_HANDS_ON" ;
VAL_ 921 DAS_autoparkReady 1 "AUTOPARK_READY" 0 "AUTOPARK_UNAVAILABLE" ;
VAL_ 921 DAS_autopilotHandsOnState 0 "LC_HANDS_ON_NOT_REQD" 4 "LC_HANDS_ON_REQD_CHIME_1" 5 "LC_HANDS_ON_REQD_CHIME_2" 1 "LC_HANDS_ON_REQD_DETECTED" 9 "LC_HANDS_ON_REQD_ESCALATED_CHIME_1" 10 "LC_HANDS_ON_REQD_ESCALATED_CHIME_2" 2 "LC_HANDS_ON_REQD_NOT_DETECTED" 6 "LC_HANDS_ON_REQD_SLOWING" 7 "LC_HANDS_ON_REQD_STRUCK_OUT" 3 "LC_HANDS_ON_REQD_VISUAL" 15 "LC_HANDS_ON_SNA" 8 "LC_HANDS_ON_SUSPENDED" ;
VAL_ 921 DAS_autopilotState 9 "ABORTED" 8 "ABORTING" 5 "ACTIVE_NAV" 3 "ACTIVE_NOMINAL" 4 "ACTIVE_RESTRICTED" 2 "AVAILABLE" 0 "DISABLED" 14 "FAULT" 15 "SNA" 1 "UNAVAILABLE" ;
VAL_ 921 DAS_blindSpotRearLeft 0 "NO_WARNING" 3 "SNA" 1 "WARNING_LEVEL_1" 2 "WARNING_LEVEL_2" ;
VAL_ 921 DAS_blindSpotRearRight 0 "NO_WARNING" 3 "SNA" 1 "WARNING_LEVEL_1" 2 "WARNING_LEVEL_2" ;
VAL_ 921 DAS_fleetSpeedState 2 "FLEETSPEED_ACTIVE" 1 "FLEETSPEED_AVAILABLE" 3 "FLEETSPEED_HOLD" 0 "FLEETSPEED_UNAVAILABLE" ;
VAL_ 921 DAS_forwardCollisionWarning 1 "FORWARD_COLLISION_WARNING" 0 "NONE" 3 "SNA" ;
VAL_ 921 DAS_fusedSpeedLimit 31 "NONE" 0 "UNKNOWN_SNA" ;
VAL_ 921 DAS_heaterState 0 "HEATER_OFF_SNA" 1 "HEATER_ON" ;
VAL_ 921 DAS_laneDepartureWarning 1 "LEFT_WARNING" 3 "LEFT_WARNING_SEVERE" 0 "NONE" 2 "RIGHT_WARNING" 4 "RIGHT_WARNING_SEVERE" 5 "SNA" ;
VAL_ 921 DAS_lssState 6 "LSS_STATE_ABORT" 5 "LSS_STATE_BLINDSPOT" 3 "LSS_STATE_ELK" 0 "LSS_STATE_FAULT" 1 "LSS_STATE_LDW" 2 "LSS_STATE_LKA" 4 "LSS_STATE_MONITOR" 7 "LSS_STATE_OFF" ;
VAL_ 921 DAS_sideCollisionAvoid 1 "AVOID_LEFT" 2 "AVOID_RIGHT" 0 "NONE" 3 "SNA" ;
VAL_ 921 DAS_sideCollisionInhibit 1 "INHIBIT" 0 "NO_INHIBIT" ;
VAL_ 921 DAS_sideCollisionWarning 0 "NONE" 1 "WARN_LEFT" 3 "WARN_LEFT_RIGHT" 2 "WARN_RIGHT" ;
VAL_ 921 DAS_suppressSpeedWarning 0 "Do_Not_Suppress" 1 "Suppress_Speed_Warning" ;
VAL_ 921 DAS_visionOnlySpeedLimit 31 "NONE" 0 "UNKNOWN_SNA" ;
VAL_ 925 IBST_driverBrakeApply 1 "BRAKES_NOT_APPLIED" 2 "DRIVER_APPLYING_BRAKES" 3 "FAULT" 0 "NOT_INIT_OR_OFF" ;
VAL_ 925 IBST_iBoosterStatus 4 "IBOOSTER_ACTIVE_GOOD_CHECK" 6 "IBOOSTER_ACTUATION" 3 "IBOOSTER_DIAGNOSTIC" 2 "IBOOSTER_FAILURE" 1 "IBOOSTER_INIT" 0 "IBOOSTER_OFF" 5 "IBOOSTER_READY" ;
VAL_ 925 IBST_internalState 4 "DIAGNOSTIC" 3 "EXTERNAL_BRAKE_REQUEST" 2 "LOCAL_BRAKE_REQUEST" 0 "NO_MODE_ACTIVE" 6 "POST_DRIVE_CHECK" 1 "PRE_DRIVE_CHECK" 5 "TRANSITION_TO_IDLE" ;
VAL_ 929 VCFRONT_12vStatusForDrive 2 "EXIT_DRIVE_REQUESTED_12V" 0 "NOT_READY_FOR_DRIVE_12V" 1 "READY_FOR_DRIVE_12V" ;
VAL_ 929 VCFRONT_2RowCenterUnbuckled 0 "CHIME_NONE" 1 "CHIME_OCCUPIED_AND_UNBUCKLED" 2 "CHIME_SNA" ;
VAL_ 929 VCFRONT_2RowLeftUnbuckled 0 "CHIME_NONE" 1 "CHIME_OCCUPIED_AND_UNBUCKLED" 2 "CHIME_SNA" ;
VAL_ 929 VCFRONT_2RowRightUnbuckled 0 "CHIME_NONE" 1 "CHIME_OCCUPIED_AND_UNBUCKLED" 2 "CHIME_SNA" ;
VAL_ 929 VCFRONT_APGlassHeaterState 4 "HEATER_STATE_FAULT" 2 "HEATER_STATE_OFF" 3 "HEATER_STATE_OFF_UNAVAILABLE" 1 "HEATER_STATE_ON" 0 "HEATER_STATE_SNA" ;
VAL_ 929 VCFRONT_diPowerOnState 0 "DI_POWERED_OFF" 3 "DI_POWERED_ON_FOR_DRIVE" 2 "DI_POWERED_ON_FOR_STATIONARY_HEAT" 1 "DI_POWERED_ON_FOR_SUMMON" 4 "DI_POWER_GOING_DOWN" ;
VAL_ 929 VCFRONT_driverBuckleStatus 1 "BUCKLED" 0 "UNBUCKLED" ;
VAL_ 929 VCFRONT_driverDoorStatus 1 "DOOR_CLOSED" 0 "DOOR_OPEN" ;
VAL_ 929 VCFRONT_driverUnbuckled 0 "CHIME_NONE" 1 "CHIME_OCCUPIED_AND_UNBUCKLED" 2 "CHIME_SNA" ;
VAL_ 929 VCFRONT_passengerUnbuckled 0 "CHIME_NONE" 1 "CHIME_OCCUPIED_AND_UNBUCKLED" 2 "CHIME_SNA" ;
VAL_ 929 VCFRONT_pcsEFuseVoltage 1023 "SNA" ;
VAL_ 929 VCFRONT_thermalSystemType 1 "HEAT_PUMP_THERMAL_SYSTEM" 0 "LEGACY_THERMAL_SYSTEM" ;
VAL_ 985 UI_conditionalSpeedLimit 31 "SNA" ;
VAL_ 985 UI_mapSpeedLimitUnits 1 "KPH" 0 "MPH" ;
VAL_ 985 UI_userSpeedOffsetUnits 1 "KPH" 0 "MPH" ;
VAL_ 994 VCLEFT_FLMapLightStatus 2 "LIGHT_FAULT" 0 "LIGHT_OFF" 1 "LIGHT_ON" 3 "LIGHT_SNA" ;
VAL_ 994 VCLEFT_FRMapLightStatus 2 "LIGHT_FAULT" 0 "LIGHT_OFF" 1 "LIGHT_ON" 3 "LIGHT_SNA" ;
VAL_ 994 VCLEFT_RLMapLightStatus 2 "LIGHT_FAULT" 0 "LIGHT_OFF" 1 "LIGHT_ON" 3 "LIGHT_SNA" ;
VAL_ 994 VCLEFT_RRMapLightStatus 2 "LIGHT_FAULT" 0 "LIGHT_OFF" 1 "LIGHT_ON" 3 "LIGHT_SNA" ;
VAL_ 994 VCLEFT_brakeLightStatus 2 "LIGHT_FAULT" 0 "LIGHT_OFF" 1 "LIGHT_ON" 3 "LIGHT_SNA" ;
VAL_ 994 VCLEFT_brakeTrailerLightStatus 2 "LIGHT_FAULT" 0 "LIGHT_OFF" 1 "LIGHT_ON" 3 "LIGHT_SNA" ;
VAL_ 994 VCLEFT_dynamicBrakeLightStatus 2 "DYNAMIC_BRAKE_LIGHT_ACTIVE_HIGH" 1 "DYNAMIC_BRAKE_LIGHT_ACTIVE_LOW" 0 "DYNAMIC_BRAKE_LIGHT_OFF" ;
VAL_ 994 VCLEFT_fogTrailerLightStatus 2 "LIGHT_FAULT" 0 "LIGHT_OFF" 1 "LIGHT_ON" 3 "LIGHT_SNA" ;
VAL_ 994 VCLEFT_frontRideHeight -128 "SNA" ;
VAL_ 994 VCLEFT_leftTurnTrailerLightStatu 2 "LIGHT_FAULT" 0 "LIGHT_OFF" 1 "LIGHT_ON" 3 "LIGHT_SNA" ;
VAL_ 994 VCLEFT_rearRideHeight -128 "SNA" ;
VAL_ 994 VCLEFT_reverseTrailerLightStatus 2 "LIGHT_FAULT" 0 "LIGHT_OFF" 1 "LIGHT_ON" 3 "LIGHT_SNA" ;
VAL_ 994 VCLEFT_rightTrnTrailerLightStatu 2 "LIGHT_FAULT" 0 "LIGHT_OFF" 1 "LIGHT_ON" 3 "LIGHT_SNA" ;
VAL_ 994 VCLEFT_tailLightStatus 2 "LIGHT_FAULT" 0 "LIGHT_OFF" 1 "LIGHT_ON" 3 "LIGHT_SNA" ;
VAL_ 994 VCLEFT_tailTrailerLightStatus 2 "LIGHT_FAULT" 0 "LIGHT_OFF" 1 "LIGHT_ON" 3 "LIGHT_SNA" ;
VAL_ 994 VCLEFT_trailerDetected 2 "TRAILER_LIGHT_DETECTION_DETECTED" 1 "TRAILER_LIGHT_DETECTION_FAULT" 3 "TRAILER_LIGHT_DETECTION_NOT_DETECTED" 0 "TRAILER_LIGHT_DETECTION_SNA" ;
VAL_ 994 VCLEFT_turnSignalStatus 2 "LIGHT_FAULT" 0 "LIGHT_OFF" 1 "LIGHT_ON" 3 "LIGHT_SNA" ;
VAL_ 1001 DAS_hazardLightRequest 0 "DAS_REQUEST_HAZARDS_OFF" 1 "DAS_REQUEST_HAZARDS_ON" 3 "DAS_REQUEST_HAZARDS_SNA" 2 "DAS_REQUEST_HAZARDS_UNUSED" ;
VAL_ 1001 DAS_headlightRequest 3 "DAS_HEADLIGHT_REQUEST_INVALID" 0 "DAS_HEADLIGHT_REQUEST_OFF" 1 "DAS_HEADLIGHT_REQUEST_ON" ;
VAL_ 1001 DAS_heaterRequest 1 "DAS_HEATER_OFF" 2 "DAS_HEATER_ON" 0 "DAS_HEATER_SNA" ;
VAL_ 1001 DAS_highLowBeamDecision 1 "DAS_HIGH_BEAM_OFF" 2 "DAS_HIGH_BEAM_ON" 3 "DAS_HIGH_BEAM_SNA" 0 "DAS_HIGH_BEAM_UNDECIDED" ;
VAL_ 1001 DAS_highLowBeamOffReason 3 "HIGH_BEAM_OFF_REASON_AMBIENT_LIGHT" 4 "HIGH_BEAM_OFF_REASON_HEAD_LIGHT" 2 "HIGH_BEAM_OFF_REASON_MOVING_RADAR_TARGET" 1 "HIGH_BEAM_OFF_REASON_MOVING_VISION_TARGET" 5 "HIGH_BEAM_OFF_REASON_SNA" 0 "HIGH_BEAM_ON" ;
VAL_ 1001 DAS_turnIndicatorRequest 3 "DAS_TURN_INDICATOR_CANCEL" 4 "DAS_TURN_INDICATOR_DEFER" 1 "DAS_TURN_INDICATOR_LEFT" 0 "DAS_TURN_INDICATOR_NONE" 2 "DAS_TURN_INDICATOR_RIGHT" ;
VAL_ 1001 DAS_turnIndicatorRequestReason 8 "DAS_ACTIVE_COMMANDED_LANE_CHANGE" 3 "DAS_ACTIVE_FORK" 9 "DAS_ACTIVE_INTERSECTION" 6 "DAS_ACTIVE_MERGE" 1 "DAS_ACTIVE_NAV_LANE_CHANGE" 2 "DAS_ACTIVE_SPEED_LANE_CHANGE" 11 "DAS_ACTIVE_SUMMMON" 5 "DAS_CANCEL_FORK" 10 "DAS_CANCEL_INTERSECTION" 4 "DAS_CANCEL_LANE_CHANGE" 7 "DAS_CANCEL_MERGE" 12 "DAS_CANCEL_SUMMMON" 0 "DAS_NONE" ;
VAL_ 1001 DAS_wiperSpeed 1 "DAS_WIPER_SPEED_1" 10 "DAS_WIPER_SPEED_10" 11 "DAS_WIPER_SPEED_11" 12 "DAS_WIPER_SPEED_12" 13 "DAS_WIPER_SPEED_13" 14 "DAS_WIPER_SPEED_14" 2 "DAS_WIPER_SPEED_2" 3 "DAS_WIPER_SPEED_3" 4 "DAS_WIPER_SPEED_4" 5 "DAS_WIPER_SPEED_5" 6 "DAS_WIPER_SPEED_6" 7 "DAS_WIPER_SPEED_7" 8 "DAS_WIPER_SPEED_8" 9 "DAS_WIPER_SPEED_9" 15 "DAS_WIPER_SPEED_INVALID" 0 "DAS_WIPER_SPEED_OFF" ;
VAL_ 1011 UI_odometer 16777215 "SNA" ;
VAL_ 1013 VCFRONT_DRLLeftStatus 2 "LIGHT_FAULT" 0 "LIGHT_OFF" 1 "LIGHT_ON" 3 "LIGHT_SNA" ;
VAL_ 1013 VCFRONT_DRLRightStatus 2 "LIGHT_FAULT" 0 "LIGHT_OFF" 1 "LIGHT_ON" 3 "LIGHT_SNA" ;
VAL_ 1013 VCFRONT_ambientLightingBrightnes 255 "SNA" ;
VAL_ 1013 VCFRONT_fogLeftStatus 2 "LIGHT_FAULT" 0 "LIGHT_OFF" 1 "LIGHT_ON" 3 "LIGHT_SNA" ;
VAL_ 1013 VCFRONT_fogRightStatus 2 "LIGHT_FAULT" 0 "LIGHT_OFF" 1 "LIGHT_ON" 3 "LIGHT_SNA" ;
VAL_ 1013 VCFRONT_hazardLightRequest 1 "HAZARD_REQUEST_BUTTON" 6 "HAZARD_REQUEST_CAR_ALARM" 5 "HAZARD_REQUEST_CRASH" 7 "HAZARD_REQUEST_DAS" 2 "HAZARD_REQUEST_LOCK" 4 "HAZARD_REQUEST_MISLOCK" 0 "HAZARD_REQUEST_NONE" 8 "HAZARD_REQUEST_UDS" 3 "HAZARD_REQUEST_UNLOCK" ;
VAL_ 1013 VCFRONT_highBeamLeftStatus 2 "LIGHT_FAULT" 0 "LIGHT_OFF" 1 "LIGHT_ON" 3 "LIGHT_SNA" ;
VAL_ 1013 VCFRONT_highBeamRightStatus 2 "LIGHT_FAULT" 0 "LIGHT_OFF" 1 "LIGHT_ON" 3 "LIGHT_SNA" ;
VAL_ 1013 VCFRONT_indicatorLeftRequest 2 "TURN_SIGNAL_ACTIVE_HIGH" 1 "TURN_SIGNAL_ACTIVE_LOW" 0 "TURN_SIGNAL_OFF" ;
VAL_ 1013 VCFRONT_indicatorRightRequest 2 "TURN_SIGNAL_ACTIVE_HIGH" 1 "TURN_SIGNAL_ACTIVE_LOW" 0 "TURN_SIGNAL_OFF" ;
VAL_ 1013 VCFRONT_lowBeamLeftStatus 2 "LIGHT_FAULT" 0 "LIGHT_OFF" 1 "LIGHT_ON" 3 "LIGHT_SNA" ;
VAL_ 1013 VCFRONT_lowBeamRightStatus 2 "LIGHT_FAULT" 0 "LIGHT_OFF" 1 "LIGHT_ON" 3 "LIGHT_SNA" ;
VAL_ 1013 VCFRONT_parkLeftStatus 2 "LIGHT_FAULT" 0 "LIGHT_OFF" 1 "LIGHT_ON" 3 "LIGHT_SNA" ;
VAL_ 1013 VCFRONT_parkRightStatus 2 "LIGHT_FAULT" 0 "LIGHT_OFF" 1 "LIGHT_ON" 3 "LIGHT_SNA" ;
VAL_ 1013 VCFRONT_sideMarkersStatus 2 "LIGHT_FAULT" 0 "LIGHT_OFF" 1 "LIGHT_ON" 3 "LIGHT_SNA" ;
VAL_ 1013 VCFRONT_sideRepeaterLeftStatus 2 "LIGHT_FAULT" 0 "LIGHT_OFF" 1 "LIGHT_ON" 3 "LIGHT_SNA" ;
VAL_ 1013 VCFRONT_sideRepeaterRightStatus 2 "LIGHT_FAULT" 0 "LIGHT_OFF" 1 "LIGHT_ON" 3 "LIGHT_SNA" ;
VAL_ 1013 VCFRONT_simLatchingStalk 0 "SIMULATED_LATCHING_STALK_IDLE" 1 "SIMULATED_LATCHING_STALK_LEFT" 2 "SIMULATED_LATCHING_STALK_RIGHT" 3 "SIMULATED_LATCHING_STALK_SNA" ;
VAL_ 1013 VCFRONT_switchLightingBrightness 255 "SNA" ;
VAL_ 1013 VCFRONT_turnSignalLeftStatus 2 "LIGHT_FAULT" 0 "LIGHT_OFF" 1 "LIGHT_ON" 3 "LIGHT_SNA" ;
VAL_ 1013 VCFRONT_turnSignalRightStatus 2 "LIGHT_FAULT" 0 "LIGHT_OFF" 1 "LIGHT_ON" 3 "LIGHT_SNA" ;
VAL_ 1016 UI_accFollowDistanceSetting 0 "DISTANCE_SETTING_1" 1 "DISTANCE_SETTING_2" 2 "DISTANCE_SETTING_3" 3 "DISTANCE_SETTING_4" 4 "DISTANCE_SETTING_5" 5 "DISTANCE_SETTING_6" 6 "DISTANCE_SETTING_7" 7 "DISTANCE_SETTING_SNA" ;
VAL_ 1016 UI_autopilotControlRequest 0 "LEGACY_LAT_CTRL" 1 "NEXT_GEN_CTRL" ;
VAL_ 1016 UI_curvSpeedAdaptDisable 1 "CSA_OFF" 0 "CSA_ON" ;
VAL_ 1016 UI_curvatureDatabaseOnly 0 "OFF" 1 "ON" ;
VAL_ 1016 UI_driveOnMapsEnable 0 "DOM_OFF" 1 "DOM_ON" ;
VAL_ 1016 UI_drivingSide 0 "DRIVING_SIDE_LEFT" 1 "DRIVING_SIDE_RIGHT" 2 "DRIVING_SIDE_UNKNOWN" ;
VAL_ 1016 UI_exceptionListEnable 0 "EXCEPTION_LIST_OFF" 1 "EXCEPTION_LIST_ON" ;
VAL_ 1016 UI_followNavRouteEnable 0 "NAV_ROUTE_OFF" 1 "NAV_ROUTE_ON" ;
VAL_ 1016 UI_fuseHPPDisable 1 "FUSE_HPP_OFF" 0 "FUSE_HPP_ON" ;
VAL_ 1016 UI_fuseLanesDisable 1 "FUSE_LANES_OFF" 0 "FUSE_LANES_ON" ;
VAL_ 1016 UI_fuseVehiclesDisable 1 "FUSE_VEH_OFF" 0 "FUSE_VEH_ON" ;
VAL_ 1016 UI_handsOnRequirementDisable 1 "HANDS_ON_REQ_OFF" 0 "HANDS_ON_REQ_ON" ;
VAL_ 1016 UI_lssElkEnabled 0 "ELK_OFF" 1 "ELK_ON" ;
VAL_ 1016 UI_lssLdwEnabled 0 "LDW_OFF" 1 "LDW_ON" ;
VAL_ 1016 UI_lssLkaEnabled 0 "LKA_OFF" 1 "LKA_ON" ;
VAL_ 1016 UI_roadCheckDisable 1 "RC_OFF" 0 "RC_ON" ;
VAL_ 1016 UI_selfParkRequest 3 "ABORT" 9 "AUTO_SUMMON_CANCEL" 7 "AUTO_SUMMON_FORWARD" 10 "AUTO_SUMMON_PRIMED" 8 "AUTO_SUMMON_REVERSE" 0 "NONE" 5 "PAUSE" 4 "PRIME" 6 "RESUME" 1 "SELF_PARK_FORWARD" 2 "SELF_PARK_REVERSE" 11 "SMART_SUMMON" 12 "SMART_SUMMON_NO_OP" 15 "SNA" ;
VAL_ 1016 UI_smartSummonType 1 "FIND_ME" 0 "PIN_DROP" 2 "SMART_AUTOPARK" ;
VAL_ 1016 UI_source3D 2 "XYZ_PREDICTION" 0 "Z_FROM_MAP" 1 "Z_FROM_PATH_PREDICTION" ;
VAL_ 1016 UI_summonEntryType 3 "SNA" 0 "STRAIGHT" 2 "TURN_LEFT" 1 "TURN_RIGHT" ;
VAL_ 1016 UI_summonExitType 3 "SNA" 0 "STRAIGHT" 2 "TURN_LEFT" 1 "TURN_RIGHT" ;
VAL_ 1016 UI_summonReverseDist 63 "SNA" ;
VAL_ 1016 UI_ulcBlindSpotConfig 1 "AGGRESSIVE" 2 "MAD_MAX" 0 "STANDARD" ;
VAL_ 1016 UI_ulcSpeedConfig 2 "SPEED_BASED_ULC_AVERAGE" 0 "SPEED_BASED_ULC_DISABLED" 3 "SPEED_BASED_ULC_MAD_MAX" 1 "SPEED_BASED_ULC_MILD" ;
VAL_ 1016 UI_visionSpeedType 0 "VISION_SPEED_DISABLED" 1 "VISION_SPEED_ONE_SECOND" 3 "VISION_SPEED_OPTIMIZED" 2 "VISION_SPEED_TWO_SECOND" ;
VAL_ 1021 UI_autopilotControlIndex 0 "AUTOPILOT_CONTROL_0" 1 "AUTOPILOT_CONTROL_1" 2 "AUTOPILOT_CONTROL_2" 3 "AUTOPILOT_CONTROL_3" 4 "AUTOPILOT_CONTROL_4" 5 "AUTOPILOT_CONTROL_5" 6 "AUTOPILOT_CONTROL_6" 7 "AUTOPILOT_CONTROL_7" ;
VAL_ 1021 UI_apmv3Branch 5 "DEMO" 2 "DEV" 4 "EAP" 0 "LIVE" 1 "STAGE" 3 "STAGE2" ;
VAL_ 1021 UI_blindspotDistance 1 "BLINDSPOT_DISTANCE_0P5_M" 2 "BLINDSPOT_DISTANCE_1_M" 3 "BLINDSPOT_DISTANCE_2_M" 4 "BLINDSPOT_DISTANCE_4_M" 0 "BLINDSPOT_DISTANCE_DEFAULT" 5 "BLINDSPOT_DISTANCE_OFF" ;
VAL_ 1021 UI_blindspotMinSpeed 2 "BLINDSPOT_MIN_SPEED_10_KPH" 3 "BLINDSPOT_MIN_SPEED_15_KPH" 4 "BLINDSPOT_MIN_SPEED_20_KPH" 5 "BLINDSPOT_MIN_SPEED_25_KPH" 6 "BLINDSPOT_MIN_SPEED_30_KPH" 7 "BLINDSPOT_MIN_SPEED_35_KPH" 8 "BLINDSPOT_MIN_SPEED_40_KPH" 9 "BLINDSPOT_MIN_SPEED_45_KPH" 1 "BLINDSPOT_MIN_SPEED_5_KPH" 0 "BLINDSPOT_MIN_SPEED_DEFAULT" 10 "BLINDSPOT_MIN_SPEED_OFF" ;
VAL_ 1021 UI_blindspotTTC 1 "BLINDSPOT_TTC_0P5_S" 2 "BLINDSPOT_TTC_1_S" 3 "BLINDSPOT_TTC_2_S" 5 "BLINDSPOT_TTC_3_S" 4 "BLINDSPOT_TTC_4_S" 6 "BLINDSPOT_TTC_5_S" 0 "BLINDSPOT_TTC_DEFAULT" 7 "BLINDSPOT_TTC_OFF" ;
VAL_ 1021 UI_donAlcProgGoreAbortThres 1 "DON_ALC_PROGRESS_GORE_ABORT_THRESHOLD_0P00" 2 "DON_ALC_PROGRESS_GORE_ABORT_THRESHOLD_0P05" 3 "DON_ALC_PROGRESS_GORE_ABORT_THRESHOLD_0P10" 4 "DON_ALC_PROGRESS_GORE_ABORT_THRESHOLD_0P15" 5 "DON_ALC_PROGRESS_GORE_ABORT_THRESHOLD_0P20" 6 "DON_ALC_PROGRESS_GORE_ABORT_THRESHOLD_0P25" 7 "DON_ALC_PROGRESS_GORE_ABORT_THRESHOLD_0P30" 8 "DON_ALC_PROGRESS_GORE_ABORT_THRESHOLD_0P35" 9 "DON_ALC_PROGRESS_GORE_ABORT_THRESHOLD_0P40" 0 "DON_ALC_PROGRESS_GORE_ABORT_THRESHOLD_DEFAULT" ;
VAL_ 1021 UI_donDisableAutoWiperDuration 5 "DON_DISABLE_AUTO_WIPER_DURATION_120_S" 2 "DON_DISABLE_AUTO_WIPER_DURATION_15_S" 3 "DON_DISABLE_AUTO_WIPER_DURATION_30_S" 1 "DON_DISABLE_AUTO_WIPER_DURATION_5_S" 4 "DON_DISABLE_AUTO_WIPER_DURATION_60_S" 0 "DON_DISABLE_AUTO_WIPER_DURATION_DEFAULT" 6 "DON_DISABLE_AUTO_WIPER_DURATION_OFF" ;
VAL_ 1021 UI_donDisableCutin 0 "DON_DISABLE_CUTIN_OFF" 1 "DON_DISABLE_CUTIN_ON" ;
VAL_ 1021 UI_donDisableOnAutoWiperSpeed 1 "DAS_WIPER_SPEED_1" 10 "DAS_WIPER_SPEED_10" 11 "DAS_WIPER_SPEED_11" 12 "DAS_WIPER_SPEED_12" 13 "DAS_WIPER_SPEED_13" 14 "DAS_WIPER_SPEED_14" 2 "DAS_WIPER_SPEED_2" 3 "DAS_WIPER_SPEED_3" 4 "DAS_WIPER_SPEED_4" 5 "DAS_WIPER_SPEED_5" 6 "DAS_WIPER_SPEED_6" 7 "DAS_WIPER_SPEED_7" 8 "DAS_WIPER_SPEED_8" 9 "DAS_WIPER_SPEED_9" 15 "DAS_WIPER_SPEED_INVALID" 0 "DAS_WIPER_SPEED_OFF" ;
VAL_ 1021 UI_donMinGoreWidthForAbortMap 2 "DON_MIN_GORE_WIDTH_FOR_ABORT_0P5_M" 1 "DON_MIN_GORE_WIDTH_FOR_ABORT_0_M" 4 "DON_MIN_GORE_WIDTH_FOR_ABORT_1P5_M" 3 "DON_MIN_GORE_WIDTH_FOR_ABORT_1_M" 6 "DON_MIN_GORE_WIDTH_FOR_ABORT_2P5_M" 5 "DON_MIN_GORE_WIDTH_FOR_ABORT_2_M" 8 "DON_MIN_GORE_WIDTH_FOR_ABORT_3P5_M" 7 "DON_MIN_GORE_WIDTH_FOR_ABORT_3_M" 10 "DON_MIN_GORE_WIDTH_FOR_ABORT_4P5_M" 9 "DON_MIN_GORE_WIDTH_FOR_ABORT_4_M" 11 "DON_MIN_GORE_WIDTH_FOR_ABORT_5_M" 0 "DON_MIN_GORE_WIDTH_FOR_ABORT_DEFAULT" ;
VAL_ 1021 UI_donMinGoreWidthForAbortNotMap 2 "DON_MIN_GORE_WIDTH_FOR_ABORT_0P5_M" 1 "DON_MIN_GORE_WIDTH_FOR_ABORT_0_M" 4 "DON_MIN_GORE_WIDTH_FOR_ABORT_1P5_M" 3 "DON_MIN_GORE_WIDTH_FOR_ABORT_1_M" 6 "DON_MIN_GORE_WIDTH_FOR_ABORT_2P5_M" 5 "DON_MIN_GORE_WIDTH_FOR_ABORT_2_M" 8 "DON_MIN_GORE_WIDTH_FOR_ABORT_3P5_M" 7 "DON_MIN_GORE_WIDTH_FOR_ABORT_3_M" 10 "DON_MIN_GORE_WIDTH_FOR_ABORT_4P5_M" 9 "DON_MIN_GORE_WIDTH_FOR_ABORT_4_M" 11 "DON_MIN_GORE_WIDTH_FOR_ABORT_5_M" 0 "DON_MIN_GORE_WIDTH_FOR_ABORT_DEFAULT" ;
VAL_ 1021 UI_donStopEndOfRampBuffer 1 "DON_STOP_END_OF_RAMP_BUFFER_15_M" 2 "DON_STOP_END_OF_RAMP_BUFFER_30_M" 3 "DON_STOP_END_OF_RAMP_BUFFER_45_M" 0 "DON_STOP_END_OF_RAMP_BUFFER_DEFAULT" 4 "DON_STOP_END_OF_RAMP_BUFFER_OFF" ;
VAL_ 1021 UI_homelinkNearby 1 "HOMELINK_NEARBY" 0 "HOMELINK_NOT_NEARBY" ;
VAL_ 1021 UI_hovEnabled 0 "HOV_OFF" 1 "HOV_ON" ;
VAL_ 611 VCRIGHT_logging10HzIndex 4 "END" 1 "HVAC_ACTUATOR_POSITIONS" 2 "HVAC_ACTUATOR_STATE" 0 "HVAC_ACTUATOR_TARGETS" 3 "HVAC_EVAP_PULLDOWN" ;
VAL_ 611 VCRIGHT_EvapPulldownBias 255 "SNA" ;
VAL_ 611 VCRIGHT_hvacIntakeActuatorState 0 "HVACACTUATOR_STATE_BRAKING" 2 "HVACACTUATOR_STATE_COASTING" 1 "HVACACTUATOR_STATE_RUNNING" ;
VAL_ 611 VCRIGHT_hvacIntakeOperationMode 1 "HVACACTUATOR_OPERATION_MODE_CALIBRATION" 0 "HVACACTUATOR_OPERATION_MODE_NORMAL" ;
VAL_ 611 VCRIGHT_hvacLHBleedActuatorState 0 "HVACACTUATOR_STATE_BRAKING" 2 "HVACACTUATOR_STATE_COASTING" 1 "HVACACTUATOR_STATE_RUNNING" ;
VAL_ 611 VCRIGHT_hvacLHBleedOperationMode 1 "HVACACTUATOR_OPERATION_MODE_CALIBRATION" 0 "HVACACTUATOR_OPERATION_MODE_NORMAL" ;
VAL_ 611 VCRIGHT_hvacLHVaneActuatorState 0 "HVACACTUATOR_STATE_BRAKING" 2 "HVACACTUATOR_STATE_COASTING" 1 "HVACACTUATOR_STATE_RUNNING" ;
VAL_ 611 VCRIGHT_hvacLHVaneOperationMode 1 "HVACACTUATOR_OPERATION_MODE_CALIBRATION" 0 "HVACACTUATOR_OPERATION_MODE_NORMAL" ;
VAL_ 611 VCRIGHT_hvacLowerModeActState 0 "HVACACTUATOR_STATE_BRAKING" 2 "HVACACTUATOR_STATE_COASTING" 1 "HVACACTUATOR_STATE_RUNNING" ;
VAL_ 611 VCRIGHT_hvacLowerModeOpMode 1 "HVACACTUATOR_OPERATION_MODE_CALIBRATION" 0 "HVACACTUATOR_OPERATION_MODE_NORMAL" ;
VAL_ 611 VCRIGHT_hvacRHBleedActuatorState 0 "HVACACTUATOR_STATE_BRAKING" 2 "HVACACTUATOR_STATE_COASTING" 1 "HVACACTUATOR_STATE_RUNNING" ;
VAL_ 611 VCRIGHT_hvacRHBleedOperationMode 1 "HVACACTUATOR_OPERATION_MODE_CALIBRATION" 0 "HVACACTUATOR_OPERATION_MODE_NORMAL" ;
VAL_ 611 VCRIGHT_hvacRHVaneActuatorState 0 "HVACACTUATOR_STATE_BRAKING" 2 "HVACACTUATOR_STATE_COASTING" 1 "HVACACTUATOR_STATE_RUNNING" ;
VAL_ 611 VCRIGHT_hvacRHVaneOperationMode 1 "HVACACTUATOR_OPERATION_MODE_CALIBRATION" 0 "HVACACTUATOR_OPERATION_MODE_NORMAL" ;
VAL_ 611 VCRIGHT_hvacUpperModeActState 0 "HVACACTUATOR_STATE_BRAKING" 2 "HVACACTUATOR_STATE_COASTING" 1 "HVACACTUATOR_STATE_RUNNING" ;
VAL_ 611 VCRIGHT_hvacUpperModeOpMode 1 "HVACACTUATOR_OPERATION_MODE_CALIBRATION" 0 "HVACACTUATOR_OPERATION_MODE_NORMAL" ;
VAL_ 615 DI_massConfidence 1 "MASS_CONFIDED" 0 "MASS_NOT_CONFIDED" ;
VAL_ 615 DI_relativeTireTreadDepth -32 "SNA" ;
VAL_ 615 DI_tireFitment 3 "FITMENT_SNA" 0 "FITMENT_SQUARE" 1 "FITMENT_STAGGERED" ;
VAL_ 615 DI_trailerDetected 1 "TRAILER_DETECTED" 0 "TRAILER_NOT_DETECTED" ;
VAL_ 642 VCLEFT_blowerIndex 0 "HVAC_FEEDBACK_SIGNALS" 1 "HVAC_VARS" ;
VAL_ 642 VCLEFT_hvacBlowerCBCCtrlState 4 "COUNT" 0 "ERROR" 1 "IDLE" 2 "OFFLINE" 3 "ONLINE" ;
VAL_ 642 VCLEFT_hvacBlowerCBCEstState 14 "COUNT" 0 "ERROR" 1 "IDLE" 5 "IDRATED" 10 "INDUCTANCE_EST" 9 "LOCKROTOR" 12 "MOTOR_IDENTIFIED" 13 "ONLINE" 8 "RAMPDOWN" 4 "RAMPUP" 7 "RATEDFLUX" 6 "RATEDFLUX_OL" 11 "ROTOR_RESISTANCE" 2 "ROVERL" 3 "RS" ;
VAL_ 642 VCLEFT_hvacBlowerFETTemp 127 "SNA" ;
VAL_ 642 VCLEFT_hvacBlowerIPhase0 255 "SNA" ;
VAL_ 642 VCLEFT_hvacBlowerIPhase1 255 "SNA" ;
VAL_ 642 VCLEFT_hvacBlowerIPhase2 255 "SNA" ;
VAL_ 642 VCLEFT_hvacBlowerITerm 127 "SNA" ;
VAL_ 642 VCLEFT_hvacBlowerOutputDuty 127 "SNA" ;
VAL_ 642 VCLEFT_hvacBlowerRPMTarget 1023 "SNA" ;
VAL_ 642 VCLEFT_hvacBlowerRs 255 "SNA" ;
VAL_ 642 VCLEFT_hvacBlowerTorque 1023 "SNA" ;
VAL_ 642 VCLEFT_hvacBlower_IO_CBC_Status 0 "IDLE" 1 "RX" ;
VAL_ 755 UI_hvacReqACDisable 0 "AUTO" 1 "OFF" 2 "ON" ;
VAL_ 755 UI_hvacReqAirDistributionMode 0 "AUTO" 4 "MANUAL_DEFROST" 5 "MANUAL_DEFROST_FLOOR" 6 "MANUAL_DEFROST_PANEL" 7 "MANUAL_DEFROST_PANEL_FLOOR" 1 "MANUAL_FLOOR" 2 "MANUAL_PANEL" 3 "MANUAL_PANEL_FLOOR" ;
VAL_ 755 UI_hvacReqBlowerSegment 1 "1" 10 "10" 2 "2" 3 "3" 4 "4" 5 "5" 6 "6" 7 "7" 8 "8" 9 "9" 11 "AUTO" 0 "OFF" ;
VAL_ 755 UI_hvacReqKeepClimateOn 2 "KEEP_CLIMATE_ON_REQ_DOG" 0 "KEEP_CLIMATE_ON_REQ_OFF" 1 "KEEP_CLIMATE_ON_REQ_ON" 3 "KEEP_CLIMATE_ON_REQ_PARTY" ;
VAL_ 755 UI_hvacReqManualDefogState 1 "DEFOG" 2 "DEFROST" 0 "NONE" ;
VAL_ 755 UI_hvacReqRecirc 0 "AUTO" 2 "FRESH" 1 "RECIRC" ;
VAL_ 755 UI_hvacReqSecondRowState 0 "AUTO" 4 "HIGH" 2 "LOW" 3 "MED" 1 "OFF" ;
VAL_ 755 UI_hvacReqTempSetpointLeft 26 "HI" 0 "LO" ;
VAL_ 755 UI_hvacReqTempSetpointRight 26 "HI" 0 "LO" ;
VAL_ 755 UI_hvacReqUserPowerState 0 "OFF" 1 "ON" 4 "OVERHEAT_PROTECT" 3 "OVERHEAT_PROTECT_FANONLY" 2 "PRECONDITION" ;
VAL_ 787 UI_trackCmpOverclock 0 "TRACK_MODE_CMP_OVERCLOCK_OFF" 1 "TRACK_MODE_CMP_OVERCLOCK_ON" ;
VAL_ 787 UI_trackModeRequest 0 "TRACK_MODE_REQUEST_IDLE" 2 "TRACK_MODE_REQUEST_OFF" 1 "TRACK_MODE_REQUEST_ON" ;
VAL_ 787 UI_trackPostCooling 0 "TRACK_MODE_POST_COOLING_OFF" 1 "TRACK_MODE_POST_COOLING_ON" ;
VAL_ 821 DIR_infoIndex 13 "DI_INFO_APP_CRC" 17 "DI_INFO_APP_GITHASH" 15 "DI_INFO_BOOTLOADER_CRC" 18 "DI_INFO_BOOTLOADER_GITHASH" 14 "DI_INFO_BOOTLOADER_SVN" 10 "DI_INFO_BUILD_HWID_COMPONENTID" 0 "DI_INFO_DEPRECATED_0" 1 "DI_INFO_DEPRECATED_1" 2 "DI_INFO_DEPRECATED_2" 3 "DI_INFO_DEPRECATED_3" 4 "DI_INFO_DEPRECATED_4" 5 "DI_INFO_DEPRECATED_5" 6 "DI_INFO_DEPRECATED_6" 7 "DI_INFO_DEPRECATED_7" 8 "DI_INFO_DEPRECATED_8" 9 "DI_INFO_DEPRECATED_9" 255 "DI_INFO_END" 11 "DI_INFO_PCBAID_ASSYID_USAGEID" 16 "DI_INFO_SUBCOMPONENT" 23 "DI_INFO_SUBCOMPONENT2" 31 "DI_INFO_SUBCOMPONENT_GITHASH" 20 "DI_INFO_UDS_PROTOCOL_BOOTCRC" 19 "DI_INFO_VERSION_DEPRECATED" ;
VAL_ 821 DIR_FPGA_version 254 "FPGA_VERSION_LOCAL_BUILD" 255 "FPGA_VERSION_SNA" ;
VAL_ 821 DIR_buildType 2 "INFO_LOCAL_BUILD" 4 "INFO_MFG_BUILD" 1 "INFO_PLATFORM_BUILD" 3 "INFO_TRACEABLE_CI_BUILD" 0 "INFO_UNKNOWN_BUILD" ;
VAL_ 821 DIR_hardwareId 252 "CONFIGURABLE_HWID_PLACEHOLDER" ;
VAL_ 821 DIR_oilPumpBuildType 2 "INFO_LOCAL_BUILD" 4 "INFO_MFG_BUILD" 1 "INFO_PLATFORM_BUILD" 3 "INFO_TRACEABLE_CI_BUILD" 0 "INFO_UNKNOWN_BUILD" ;
VAL_ 899 VCRIGHT_estimatedThsSolarLoad 1023 "SNA" ;
VAL_ 899 VCRIGHT_estimatedVehicleSituatio 1 "VEHICLE_SITUATION_INDOOR" 2 "VEHICLE_SITUATION_OUTDOOR" 0 "VEHICLE_SITUATION_UNKNOWN" ;
VAL_ 899 VCRIGHT_thsHumidity 255 "SNA" ;
VAL_ 899 VCRIGHT_thsSolarLoadInfrared 1023 "SNA" ;
VAL_ 899 VCRIGHT_thsSolarLoadVisible 1023 "SNA" ;
VAL_ 899 VCRIGHT_thsTemperature -128 "SNA" ;
VAL_ 915 VCRIGHT_epbmDebugIndex 2 "EPBM_HVDISCONNECT" 0 "EPBM_STATES" 1 "EPBM_TRANSITIONS" ;
VAL_ 915 VCRIGHT_cdpEnumDummy 0 "EPB_EXTERNAL_APPLY_IDLE" 2 "EPB_EXTERNAL_APPLY_INVALID" 1 "EPB_EXTERNAL_APPLY_VALID" ;
VAL_ 915 VCRIGHT_epbFaultStatus 2 "EPB_STATUS_FAULT" 3 "EPB_STATUS_FAULT_IDLE" 0 "EPB_STATUS_NOMINAL" 1 "EPB_STATUS_RETRY" ;
VAL_ 915 VCRIGHT_epbSummonState 3 "EPB_SUMMON_ACTIVE" 2 "EPB_SUMMON_ARMED" 4 "EPB_SUMMON_COMPLETE" 5 "EPB_SUMMON_FAULT" 1 "EPB_SUMMON_IDLE" 0 "EPB_SUMMON_INIT" 6 "EPB_SUMMON_UNAVAILABLE" ;
VAL_ 915 VCRIGHT_epbUnitStatus 22 "EPB_STATUS_COUNT" 2 "EPB_STATUS_DYNAMIC" 9 "EPB_STATUS_DYNAMIC_APPLYING" 20 "EPB_STATUS_DYNAMIC_PARKING" 17 "EPB_STATUS_EXTERNAL_DYNAMIC" 19 "EPB_STATUS_EXTERNAL_PARKING" 21 "EPB_STATUS_FREE_ROLL_MODE" 1 "EPB_STATUS_OPEN" 3 "EPB_STATUS_PARK" 8 "EPB_STATUS_PARKING" 12 "EPB_STATUS_PARK_PENDING" 10 "EPB_STATUS_RELEASING" 18 "EPB_STATUS_RELEASING_FOR_EXTERNAL_PARK" 5 "EPB_STATUS_SERVICE" 11 "EPB_STATUS_SERVICE_RELEASING" 4 "EPB_STATUS_START" 14 "EPB_STATUS_SUMMON" 16 "EPB_STATUS_SUMMON_PARKING" 15 "EPB_STATUS_SUMMON_RELEASING" 0 "EPB_STATUS_UNKNOWN" 6 "EPB_STATUS_WINCHMODE" 13 "EPB_STATUS_WINCHMODE_PENDING" 7 "EPB_STATUS_WINCHMODE_RELEASING" ;
VAL_ 915 VCRIGHT_epbmCaliperState 4 "EPB_SAVED_CALIPERSTATE_OPEN" 3 "EPB_SAVED_CALIPERSTATE_PARK" 2 "EPB_SAVED_CALIPERSTATE_REAPPLY" 5 "EPB_SAVED_CALIPERSTATE_SERVICE" 1 "EPB_SAVED_CALIPERSTATE_UNKNOWN" 0 "EPB_SAVED_CALIPERSTATE_UNSAVED" 6 "EPB_SAVED_CALIPERSTATE_WINCHMODE" ;
VAL_ 915 VCRIGHT_epbmFaultStatus 2 "EPB_STATUS_FAULT" 3 "EPB_STATUS_FAULT_IDLE" 0 "EPB_STATUS_NOMINAL" 1 "EPB_STATUS_RETRY" ;
VAL_ 915 VCRIGHT_epbmSummonState 3 "EPB_SUMMON_ACTIVE" 2 "EPB_SUMMON_ARMED" 4 "EPB_SUMMON_COMPLETE" 5 "EPB_SUMMON_FAULT" 1 "EPB_SUMMON_IDLE" 0 "EPB_SUMMON_INIT" 6 "EPB_SUMMON_UNAVAILABLE" ;
VAL_ 915 VCRIGHT_epbmSystemStatus 3 "EPB_VEHICLE_STATUS_DYNAMIC" 6 "EPB_VEHICLE_STATUS_FAULT" 7 "EPB_VEHICLE_STATUS_FAULT_SECURE" 8 "EPB_VEHICLE_STATUS_MISMATCH" 2 "EPB_VEHICLE_STATUS_PARKED" 4 "EPB_VEHICLE_STATUS_PARKING" 1 "EPB_VEHICLE_STATUS_RELEASED" 5 "EPB_VEHICLE_STATUS_RELEASING" 0 "EPB_VEHICLE_STATUS_UNKNOWN" ;
VAL_ 915 VCRIGHT_summonFaultReason 7 "EPB_SUMMONFAULT_DAS_FAULT" 2 "EPB_SUMMONFAULT_DAS_MIA" 6 "EPB_SUMMONFAULT_DI_APC_FAULT" 5 "EPB_SUMMONFAULT_DI_FAULT" 1 "EPB_SUMMONFAULT_DI_MIA" 20 "EPB_SUMMONFAULT_DI_STATE_INVALID" 10 "EPB_SUMMONFAULT_EAC_NOT_ALLOWED" 4 "EPB_SUMMONFAULT_EPBM_MIA" 11 "EPB_SUMMONFAULT_EPBM_REQUEST" 22 "EPB_SUMMONFAULT_EPBREMOTE_MIA" 19 "EPB_SUMMONFAULT_EPB_FAULT" 8 "EPB_SUMMONFAULT_ESP_FAULT" 3 "EPB_SUMMONFAULT_ESP_MIA" 13 "EPB_SUMMONFAULT_EXTERNAL" 27 "EPB_SUMMONFAULT_INVALID_REMOTE_STATE" 24 "EPB_SUMMONFAULT_LOCAL_UNIT_FAULTED" 18 "EPB_SUMMONFAULT_MISMATCH" 0 "EPB_SUMMONFAULT_NONE" 17 "EPB_SUMMONFAULT_OOC" 14 "EPB_SUMMONFAULT_PARK_MIA" 21 "EPB_SUMMONFAULT_PASSIVE_REQUEST" 15 "EPB_SUMMONFAULT_PM_MIA" 16 "EPB_SUMMONFAULT_PM_REQUEST" 28 "EPB_SUMMONFAULT_REMOTE_DID_NOT_START" 23 "EPB_SUMMONFAULT_REMOTE_SUMMON_FAULTED" 25 "EPB_SUMMONFAULT_REMOTE_UNIT_FAULTED" 12 "EPB_SUMMONFAULT_SPEED" 26 "EPB_SUMMONFAULT_START_IN_UNAVAILABLE" 9 "EPB_SUMMONFAULT_VEH_CAN_FAULT" ;
VAL_ 947 UI_autopilotPowerStateRequest 0 "AUTOPILOT_NOMINAL" 1 "AUTOPILOT_SENTRY" 2 "AUTOPILOT_SUSPEND" ;
VAL_ 947 UI_lightSwitch 0 "LIGHT_SWITCH_AUTO" 3 "LIGHT_SWITCH_OFF" 1 "LIGHT_SWITCH_ON" 2 "LIGHT_SWITCH_PARKING" 4 "LIGHT_SWITCH_SNA" ;
VAL_ 947 UI_shorted12VCellTestMode 2 "SHORTED_CELL_TEST_MODE_ACTIVE" 0 "SHORTED_CELL_TEST_MODE_DISABLED" 1 "SHORTED_CELL_TEST_MODE_SHADOW" ;
VAL_ 947 UI_summonState 3 "ACTIVE" 1 "IDLE" 2 "PRE_PRIMED" 0 "SNA" ;
VAL_ 947 UI_windowRequest 3 "WINDOW_REQUEST_GOTO_CLOSED" 4 "WINDOW_REQUEST_GOTO_OPEN" 1 "WINDOW_REQUEST_GOTO_PERCENT" 2 "WINDOW_REQUEST_GOTO_VENT" 0 "WINDOW_REQUEST_IDLE" ;
VAL_ 963 VCRIGHT_frontBuckleSwitch 3 "SWITCH_FAULT" 1 "SWITCH_OFF" 2 "SWITCH_ON" 0 "SWITCH_SNA" ;
VAL_ 963 VCRIGHT_frontOccupancySwitch 3 "SWITCH_FAULT" 1 "SWITCH_OFF" 2 "SWITCH_ON" 0 "SWITCH_SNA" ;
VAL_ 963 VCRIGHT_frontSeatBackrestBack 3 "SWITCH_FAULT" 1 "SWITCH_OFF" 2 "SWITCH_ON" 0 "SWITCH_SNA" ;
VAL_ 963 VCRIGHT_frontSeatBackrestForward 3 "SWITCH_FAULT" 1 "SWITCH_OFF" 2 "SWITCH_ON" 0 "SWITCH_SNA" ;
VAL_ 963 VCRIGHT_frontSeatLiftDown 3 "SWITCH_FAULT" 1 "SWITCH_OFF" 2 "SWITCH_ON" 0 "SWITCH_SNA" ;
VAL_ 963 VCRIGHT_frontSeatLiftUp 3 "SWITCH_FAULT" 1 "SWITCH_OFF" 2 "SWITCH_ON" 0 "SWITCH_SNA" ;
VAL_ 963 VCRIGHT_frontSeatLumbarDown 3 "SWITCH_FAULT" 1 "SWITCH_OFF" 2 "SWITCH_ON" 0 "SWITCH_SNA" ;
VAL_ 963 VCRIGHT_frontSeatLumbarIn 3 "SWITCH_FAULT" 1 "SWITCH_OFF" 2 "SWITCH_ON" 0 "SWITCH_SNA" ;
VAL_ 963 VCRIGHT_frontSeatLumbarOut 3 "SWITCH_FAULT" 1 "SWITCH_OFF" 2 "SWITCH_ON" 0 "SWITCH_SNA" ;
VAL_ 963 VCRIGHT_frontSeatLumbarUp 3 "SWITCH_FAULT" 1 "SWITCH_OFF" 2 "SWITCH_ON" 0 "SWITCH_SNA" ;
VAL_ 963 VCRIGHT_frontSeatTiltDown 3 "SWITCH_FAULT" 1 "SWITCH_OFF" 2 "SWITCH_ON" 0 "SWITCH_SNA" ;
VAL_ 963 VCRIGHT_frontSeatTiltUp 3 "SWITCH_FAULT" 1 "SWITCH_OFF" 2 "SWITCH_ON" 0 "SWITCH_SNA" ;
VAL_ 963 VCRIGHT_frontSeatTrackBack 3 "SWITCH_FAULT" 1 "SWITCH_OFF" 2 "SWITCH_ON" 0 "SWITCH_SNA" ;
VAL_ 963 VCRIGHT_frontSeatTrackForward 3 "SWITCH_FAULT" 1 "SWITCH_OFF" 2 "SWITCH_ON" 0 "SWITCH_SNA" ;
VAL_ 963 VCRIGHT_rearCenterBuckleSwitch 3 "SWITCH_FAULT" 1 "SWITCH_OFF" 2 "SWITCH_ON" 0 "SWITCH_SNA" ;
VAL_ 963 VCRIGHT_rearRightBuckleSwitch 3 "SWITCH_FAULT" 1 "SWITCH_OFF" 2 "SWITCH_ON" 0 "SWITCH_SNA" ;
VAL_ 995 VCRIGHT_brakeLightStatus 2 "LIGHT_FAULT" 0 "LIGHT_OFF" 1 "LIGHT_ON" 3 "LIGHT_SNA" ;
VAL_ 995 VCRIGHT_interiorTrunkLightStatus 2 "LIGHT_FAULT" 0 "LIGHT_OFF" 1 "LIGHT_ON" 3 "LIGHT_SNA" ;
VAL_ 995 VCRIGHT_rearFogLightStatus 2 "LIGHT_FAULT" 0 "LIGHT_OFF" 1 "LIGHT_ON" 3 "LIGHT_SNA" ;
VAL_ 995 VCRIGHT_reverseLightStatus 2 "LIGHT_FAULT" 0 "LIGHT_OFF" 1 "LIGHT_ON" 3 "LIGHT_SNA" ;
VAL_ 995 VCRIGHT_tailLightStatus 2 "LIGHT_FAULT" 0 "LIGHT_OFF" 1 "LIGHT_ON" 3 "LIGHT_SNA" ;
VAL_ 995 VCRIGHT_turnSignalStatus 2 "LIGHT_FAULT" 0 "LIGHT_OFF" 1 "LIGHT_ON" 3 "LIGHT_SNA" ;
